[part 8 of 23: package /Cluster]
AUTOSAR XML (schema 4-3-0)
package /Cluster  (continued)
  can cluster E3V_EVCANFD: baudrate=500000, protocol-name=CAN, protocol-version=2.0, bus-off-recovery={bor-counter-l-1-to-l-2=1, bor-time-l-1=0.05, bor-time-l-2=0.2}, can-fd-baudrate=2000000  (continued)
    can physical channel CHNL: comm-connectors=CN_E3V_EVCANFD  (continued)
      frame SAD_01_XIX_E3V_EVCANFD: id 0x5E0, to Klima, frame-length=8, can-addressing-mode=STANDARD, can-frame-rx-behavior=CAN-FD, can-frame-tx-behavior=CAN-FD
        pdu SAD_01_XIX_E3V_EVCANFD: length=8, minimum-delay=0.05, transmission-mode-true-timing={cyclic-timing={time-offset=0.0, time-period=0.5}, event-controlled-timing={number-of-repetitions=5, repetition-period=0.1}}, unused-bit-pattern=0  # MLBevo 8Byte LIN-CAN (1:1) Botschaft wird geroutet: - wenn entsprechender Slave codiert ist - wenn fehlerfreie Kommunikation zum Slave besteht - bei fehlerhafter Kommunikation zum Slave wird die Botschaft für 4s mit den letzten gültigen Werten versendet
          signal MD1_Position_XIX_SAD_01_XIX_E3V_EVCANFD: start 8, 7 bit, little-endian, data-type-policy=OVERRIDE, i-signal-type=PRIMITIVE, init-value=126, base-type=BT_MD1_Position, compu {phys=raw for raw 0..100, 126=Cx7e_Init (CM_MD1_Position_Cx7e_Init), 127=Cx7f_nicht_normiert (CM_MD1_Position_Cx7f_nicht_normiert); unit Unit_PerCent}, range phys 0..100 Unit_PerCent, raw 0..127, unit=Unit_PerCent, transfer-property=PENDING, to Klima(timeout 5 s)  # Aktuelle Öffnungsweite Schiebedach.
          signal MD1_Lage_XIX_SAD_01_XIX_E3V_EVCANFD: start 15, 1 bit, little-endian, data-type-policy=OVERRIDE, i-signal-type=PRIMITIVE, init-value=0, base-type=BT_MD1_Lage, compu {0=Cx0_Ausstelllage (CM_MD1_Lage_Cx0_Ausstelllage), 1=Cx1_Schiebelage (CM_MD1_Lage_Cx1_Schiebelage)}, range raw 0..1, transfer-property=PENDING, to Klima(timeout 5 s)  # Lage Schiebedachstellung 1 (Signal wird 1:1 vom BCM2 geroutet; ursprünglicher Sender: SAD = LIN-Slave vom BCM2)
          signal MD3_Position_XIX_SAD_01_XIX_E3V_EVCANFD: start 16, 7 bit, little-endian, data-type-policy=OVERRIDE, i-signal-type=PRIMITIVE, init-value=0, base-type=BT_MD3_Position, compu {phys=raw for raw 0..100; unit Unit_PerCent}, range phys 0..100 Unit_PerCent, raw 0..100, unit=Unit_PerCent, transfer-property=PENDING  # Schiebedachstellung 3 (Signal wird 1:1 vom BCM2 geroutet; ursprünglicher Sender: SAD = LIN-Slave vom BCM2)
          signal MD3_Lage_XIX_SAD_01_XIX_E3V_EVCANFD: start 23, 1 bit, little-endian, data-type-policy=OVERRIDE, i-signal-type=PRIMITIVE, init-value=0, base-type=BT_MD3_Lage, compu {0=Cx0_Ausstelllage (CM_MD3_Lage_Cx0_Ausstelllage), 1=Cx1_Schiebelage (CM_MD3_Lage_Cx1_Schiebelage)}, range raw 0..1, transfer-property=PENDING, to Klima(timeout 5 s)  # Lage Schiebedachstellung 3 (Signal wird 1:1 vom BCM2 geroutet; ursprünglicher Sender: SAD = LIN-Slave vom BCM2)
          signal MRollo_Position_XIX_SAD_01_XIX_E3V_EVCANFD: start 24, 7 bit, little-endian, data-type-policy=OVERRIDE, i-signal-type=PRIMITIVE, init-value=126, base-type=BT_MRollo_Position, compu {phys=raw for raw 0..100, 126=Cx7e_Init (CM_MRollo_Position_Cx7e_Init), 127=Cx7f_nicht_normiert (CM_MRollo_Position_Cx7f_nicht_normiert); unit Unit_PerCent}, range phys 0..100 Unit_PerCent, raw 0..127, unit=Unit_PerCent, transfer-property=PENDING, to Klima(timeout 5 s)  # Aktuelle Öffnungsweite des Dachrollos.
          signal MRollo_Lage_XIX_SAD_01_XIX_E3V_EVCANFD: start 31, 1 bit, little-endian, data-type-policy=OVERRIDE, i-signal-type=PRIMITIVE, init-value=0, base-type=BT_MRollo_Lage, compu {0=Cx0_Ausstelllage (CM_MRollo_Lage_Cx0_Ausstelllage), 1=Cx1_Schiebelage (CM_MRollo_Lage_Cx1_Schiebelage)}, range raw 0..1, transfer-property=PENDING, to Klima(timeout 5 s)  # Lage Rollo (Signal wird 1:1 vom BCM2 geroutet; ursprünglicher Sender: Rollo = LIN-Slave vom BCM2)
          signal SAD_normiert_XIX_SAD_01_XIX_E3V_EVCANFD: start 32, 1 bit, little-endian, data-type-policy=OVERRIDE, i-signal-type=PRIMITIVE, init-value=0, base-type=BT_SAD_normiert, compu {0=Cx0_inaktiv (CM_SAD_normiert_Cx0_inaktiv), 1=Cx1_aktiv (CM_SAD_normiert_Cx1_aktiv)}, range raw 0..1, transfer-property=TRIGGERED-ON-CHANGE-WITHOUT-REPETITION  # Anzeige Normierung des Schiebeausstelldaches
          signal SAD_Thermoschutz_XIX_SAD_01_XIX_E3V_EVCANFD: start 33, 1 bit, little-endian, data-type-policy=OVERRIDE, i-signal-type=PRIMITIVE, init-value=0, base-type=BT_SAD_Thermoschutz, compu {0=Cx0_inaktiv (CM_SAD_Thermoschutz_Cx0_inaktiv), 1=Cx1_aktiv (CM_SAD_Thermoschutz_Cx1_aktiv)}, range raw 0..1, transfer-property=TRIGGERED-ON-CHANGE-WITHOUT-REPETITION  # Anzeige aktivierter Thermoschutz des Schiebeausstelldaches
          signal SAD_UEKB_aktiv_XIX_SAD_01_XIX_E3V_EVCANFD: start 34, 1 bit, little-endian, data-type-policy=OVERRIDE, i-signal-type=PRIMITIVE, init-value=0, base-type=BT_SAD_UEKB_aktiv, compu {0=Cx0_inaktiv (CM_SAD_UEKB_aktiv_Cx0_inaktiv), 1=Cx1_aktiv (CM_SAD_UEKB_aktiv_Cx1_aktiv)}, range raw 0..1, transfer-property=TRIGGERED-ON-CHANGE-WITHOUT-REPETITION  # Anzeige aktivierter Überschusskraftbegrenzung des Schiebeausstelldaches
          signal Rollo_normiert_XIX_SAD_01_XIX_E3V_EVCANFD: start 35, 1 bit, little-endian, data-type-policy=OVERRIDE, i-signal-type=PRIMITIVE, init-value=0, base-type=BT_Rollo_normiert, compu {0=Cx0_inaktiv (CM_Rollo_normiert_Cx0_inaktiv), 1=Cx1_aktiv (CM_Rollo_normiert_Cx1_aktiv)}, range raw 0..1, transfer-property=TRIGGERED-ON-CHANGE-WITHOUT-REPETITION  # Anzeigen Normierung des Dachrollos
          signal Rollo_Thermoschutz_XIX_SAD_01_XIX_E3V_EVCANFD: start 36, 1 bit, little-endian, data-type-policy=OVERRIDE, i-signal-type=PRIMITIVE, init-value=0, base-type=BT_Rollo_Thermoschutz, compu {0=Cx0_inaktiv (CM_Rollo_Thermoschutz_Cx0_inaktiv), 1=Cx1_aktiv (CM_Rollo_Thermoschutz_Cx1_aktiv)}, range raw 0..1, transfer-property=TRIGGERED-ON-CHANGE-WITHOUT-REPETITION  # Anzeigen aktivierter Thermoschutz des Dachrollo
          signal Rollo_UEKB_aktiv_XIX_SAD_01_XIX_E3V_EVCANFD: start 37, 1 bit, little-endian, data-type-policy=OVERRIDE, i-signal-type=PRIMITIVE, init-value=0, base-type=BT_Rollo_UEKB_aktiv, compu {0=Cx0_inaktiv (CM_Rollo_UEKB_aktiv_Cx0_inaktiv), 1=Cx1_aktiv (CM_Rollo_UEKB_aktiv_Cx1_aktiv)}, range raw 0..1, transfer-property=TRIGGERED-ON-CHANGE-WITHOUT-REPETITION  # Anzeigen aktivierter Überschusskraftbegrenzung des Dachrollos
          signal SAD_Taster_Deckel_hi_XIX_SAD_01_XIX_E3V_EVCANFD: start 38, 4 bit, little-endian, data-type-policy=OVERRIDE, i-signal-type=PRIMITIVE, init-value=0, base-type=BT_SAD_Taster_Deckel_hi, compu {0=Cx0_nicht_betaetigt (CM_SAD_Taster_Deckel_hi_Cx0_nicht_betaetigt), 1=Cx1_man_sl_zu (CM_SAD_Taster_Deckel_hi_Cx1_man_sl_zu), 2=Cx2_auto_sl_zu (CM_SAD_Taster_Deckel_hi_Cx2_auto_sl_zu), 3=Cx3_man_sl_auf (CM_SAD_Taster_Deckel_hi_Cx3_man_sl_auf), 4=Cx4_auto_sl_auf (CM_SAD_Taster_Deckel_hi_Cx4_auto_sl_auf), 5=Cx5_man_al_auf (CM_SAD_Taster_Deckel_hi_Cx5_man_al_auf), 6=Cx6_auto_al_auf (CM_SAD_Taster_Deckel_hi_Cx6_auto_al_auf), 7=Cx7_man_al_zu (CM_SAD_Taster_Deckel_hi_Cx7_man_al_zu), 8=Cx8_auto_al_zu (CM_SAD_Taster_Deckel_hi_Cx8_auto_al_zu), 14=Cxe_fehler_schalter_haengt (CM_SAD_Taster_Deckel_hi_Cxe_fehler_schalter_haengt), 15=Cxf_fehler_schalter_unplausibel (CM_SAD_Taster_Deckel_hi_Cxf_fehler_schalter_unplausibel)}, range raw 0..15, transfer-property=TRIGGERED-ON-CHANGE  # Taster für SAD Deckel hinten
          signal SAD_Taster_Deckel_vo_XIX_SAD_01_XIX_E3V_EVCANFD: start 42, 4 bit, little-endian, data-type-policy=OVERRIDE, i-signal-type=PRIMITIVE, init-value=0, base-type=BT_SAD_Taster_Deckel_vo, compu {0=Cx0_nicht_betaetigt (CM_SAD_Taster_Deckel_vo_Cx0_nicht_betaetigt), 1=Cx1_man_sl_zu (CM_SAD_Taster_Deckel_vo_Cx1_man_sl_zu), 2=Cx2_auto_sl_zu (CM_SAD_Taster_Deckel_vo_Cx2_auto_sl_zu), 3=Cx3_man_sl_auf (CM_SAD_Taster_Deckel_vo_Cx3_man_sl_auf), 4=Cx4_auto_sl_auf (CM_SAD_Taster_Deckel_vo_Cx4_auto_sl_auf), 5=Cx5_man_al_auf (CM_SAD_Taster_Deckel_vo_Cx5_man_al_auf), 6=Cx6_auto_al_auf (CM_SAD_Taster_Deckel_vo_Cx6_auto_al_auf), 7=Cx7_man_al_zu (CM_SAD_Taster_Deckel_vo_Cx7_man_al_zu), 8=Cx8_auto_al_zu (CM_SAD_Taster_Deckel_vo_Cx8_auto_al_zu), 14=Cxe_fehler_schalter_haengt (CM_SAD_Taster_Deckel_vo_Cxe_fehler_schalter_haengt), 15=Cxf_fehler_schalter_unplausibel (CM_SAD_Taster_Deckel_vo_Cxf_fehler_schalter_unplausibel)}, range raw 0..15, transfer-property=TRIGGERED-ON-CHANGE  # Taster für SAD Deckel vorne
          signal SAD_Taster_Rollo_hi_XIX_SAD_01_XIX_E3V_EVCANFD: start 46, 3 bit, little-endian, data-type-policy=OVERRIDE, i-signal-type=PRIMITIVE, init-value=0, base-type=BT_SAD_Taster_Rollo_hi, compu {0=Cx0_nicht_betaetigt (CM_SAD_Taster_Rollo_hi_Cx0_nicht_betaetigt), 1=Cx1_man_zu (CM_SAD_Taster_Rollo_hi_Cx1_man_zu), 2=Cx2_auto_zu (CM_SAD_Taster_Rollo_hi_Cx2_auto_zu), 3=Cx3_man_auf (CM_SAD_Taster_Rollo_hi_Cx3_man_auf), 4=Cx4_auto_auf (CM_SAD_Taster_Rollo_hi_Cx4_auto_auf), 6=Cx6_fehler_schalter_haengt (CM_SAD_Taster_Rollo_hi_Cx6_fehler_schalter_haengt), 7=Cx7_fehler_schalter_unplausibel (CM_SAD_Taster_Rollo_hi_Cx7_fehler_schalter_unplausibel)}, range raw 0..7, transfer-property=TRIGGERED-ON-CHANGE  # Taster für SAD Rollo hinten
          signal SAD_Taster_Rollo_vo_XIX_SAD_01_XIX_E3V_EVCANFD: start 49, 3 bit, little-endian, data-type-policy=OVERRIDE, i-signal-type=PRIMITIVE, init-value=0, base-type=BT_SAD_Taster_Rollo_vo, compu {0=Cx0_nicht_betaetigt (CM_SAD_Taster_Rollo_vo_Cx0_nicht_betaetigt), 1=Cx1_man_zu (CM_SAD_Taster_Rollo_vo_Cx1_man_zu), 2=Cx2_auto_zu (CM_SAD_Taster_Rollo_vo_Cx2_auto_zu), 3=Cx3_man_auf (CM_SAD_Taster_Rollo_vo_Cx3_man_auf), 4=Cx4_auto_auf (CM_SAD_Taster_Rollo_vo_Cx4_auto_auf), 6=Cx6_fehler_schalter_haengt (CM_SAD_Taster_Rollo_vo_Cx6_fehler_schalter_haengt), 7=Cx7_fehler_schalter_unplausibel (CM_SAD_Taster_Rollo_vo_Cx7_fehler_schalter_unplausibel)}, range raw 0..7, transfer-property=TRIGGERED-ON-CHANGE  # Taster für SAD Rollo vorne
          signal SAD_Anf_ESC_Zuschaltung_XIX_SAD_01_XIX_E3V_EVCANFD: start 52, 1 bit, little-endian, data-type-policy=OVERRIDE, i-signal-type=PRIMITIVE, init-value=0, base-type=BT_SAD_Anf_ESC_Zuschaltung, compu {0=Cx0_inaktiv (CM_SAD_Anf_ESC_Zuschaltung_Cx0_inaktiv), 1=Cx1_aktiv (CM_SAD_Anf_ESC_Zuschaltung_Cx1_aktiv)}, range raw 0..1, transfer-property=TRIGGERED-ON-CHANGE-WITHOUT-REPETITION  # Zwangsaktivierung ESP durch SAD-SG (bei geöffnetem Schiebedach und V> xx km/h).
          signal SAD_Text_XIX_SAD_01_XIX_E3V_EVCANFD: start 53, 1 bit, little-endian, data-type-policy=OVERRIDE, i-signal-type=PRIMITIVE, init-value=0, base-type=BT_SAD_Text, compu {0=Cx0_inaktiv (CM_SAD_Text_Cx0_inaktiv), 1=Cx1_aktiv (CM_SAD_Text_Cx1_aktiv)}, range raw 0..1, transfer-property=TRIGGERED-ON-CHANGE  # Fehler Windabweiser in Abhängigkeit von der Geschwindigkeit
          signal SAD_ToggleBit_XIX_SAD_01_XIX_E3V_EVCANFD: start 54, 1 bit, little-endian, data-type-policy=OVERRIDE, i-signal-type=PRIMITIVE, init-value=0, base-type=BT_SAD_ToggleBit, compu {phys=raw for raw 0..1}, range phys 0..1, raw 0..1, transfer-property=PENDING  # SIL A Absicherung für die Signale: SAD_normiert, MD1_Lage, MD1_Position, SAD_Anf_ESC_Zuschaltung
          signal SAD_ParityBit_XIX_SAD_01_XIX_E3V_EVCANFD: start 55, 1 bit, little-endian, data-type-policy=OVERRIDE, i-signal-type=PRIMITIVE, init-value=0, base-type=BT_SAD_ParityBit, compu {phys=raw for raw 0..1}, range phys 0..1, raw 0..1, transfer-property=PENDING  # SIL A Absicherung für die Signale: SAD_normiert, MD1_Lage, MD1_Position, SAD_Anf_ESC_Zuschaltung
      frame SMLS_01_XIX_E3V_EVCANFD: id 0x3D4, to Klima, frame-length=8, can-addressing-mode=STANDARD, can-frame-rx-behavior=CAN-FD, can-frame-tx-behavior=CAN-FD
        pdu SMLS_01_XIX_E3V_EVCANFD: length=8, minimum-delay=0.05, transmission-mode-true-timing={cyclic-timing={time-offset=0.0, time-period=1.0}, event-controlled-timing={number-of-repetitions=5, repetition-period=0.1}}, unused-bit-pattern=0  # Ab MQB 7.2
          signal SMLS_01_CRC_XIX_SMLS_01_XIX_E3V_EVCANFD: start 0, 8 bit, little-endian, data-type-policy=OVERRIDE, i-signal-type=PRIMITIVE, base-type=BT_SMLS_01_CRC, compu {phys=raw for raw 0..255}, range phys 0..255, raw 0..255, transfer-property=PENDING  # Für MLB: "Berechnung siehe Lastenheft "Kommunikationsabsicherung für FlexRay und CAN"" Ab MQB und MLBevo: "Berechnung siehe Lastenheft "End-to-End Kommunikationsabsicherung"" Endwerte siehe Begleitdokument "S-PDU Kennungsfolgen"
          signal SMLS_01_BZ_XIX_SMLS_01_XIX_E3V_EVCANFD: start 8, 4 bit, little-endian, data-type-policy=OVERRIDE, i-signal-type=PRIMITIVE, base-type=BT_SMLS_01_BZ, compu {phys=raw for raw 0..15}, range phys 0..15, raw 0..15, transfer-property=PENDING  # 4bit Botschaftszaehler, wird mit jeder Sendebotschaft inkrementiert
          signal BH_Blinker_li_XIX_SMLS_01_XIX_E3V_EVCANFD: start 12, 1 bit, little-endian, data-type-policy=OVERRIDE, i-signal-type=PRIMITIVE, init-value=0, base-type=BT_BH_Blinker_li, compu {0=Cx0_nicht_betaetigt (CM_BH_Blinker_li_Cx0_nicht_betaetigt), 1=Cx1_Blinkerhebel_Pos_li_betaetigt (CM_BH_Blinker_li_Cx1_Blinkerhebel_Pos_li_betaetigt)}, range raw 0..1, transfer-property=TRIGGERED-ON-CHANGE  # Blinkerhebel Richtung links
          signal BH_Blinker_re_XIX_SMLS_01_XIX_E3V_EVCANFD: start 13, 1 bit, little-endian, data-type-policy=OVERRIDE, i-signal-type=PRIMITIVE, init-value=0, base-type=BT_BH_Blinker_re, compu {0=Cx0_nicht_betaetigt (CM_BH_Blinker_re_Cx0_nicht_betaetigt), 1=Cx1_Blinkerhebel_Pos_re_betaetigt (CM_BH_Blinker_re_Cx1_Blinkerhebel_Pos_re_betaetigt)}, range raw 0..1, transfer-property=TRIGGERED-ON-CHANGE  # Blinkerhebel Richtung rechts
          signal BH_Lichthupe_XIX_SMLS_01_XIX_E3V_EVCANFD: start 14, 1 bit, little-endian, data-type-policy=OVERRIDE, i-signal-type=PRIMITIVE, init-value=0, base-type=BT_BH_Lichthupe, compu {0=Cx0_nicht_betaetigt (CM_BH_Lichthupe_Cx0_nicht_betaetigt), 1=Cx1_Blinkerhebel_in_Richtung_Lichthupe_betaetigt (CM_BH_Lichthupe_Cx1_Blinkerhebel_in_Richtung_Lichthupe_betaetigt) (Blinkerhebel in Richtung Lichthupe betaetigt)}, range raw 0..1, transfer-property=TRIGGERED-ON-CHANGE  # Betaetigung Lichthupe
          signal BH_Fernlicht_XIX_SMLS_01_XIX_E3V_EVCANFD: start 15, 1 bit, little-endian, data-type-policy=OVERRIDE, i-signal-type=PRIMITIVE, init-value=0, base-type=BT_BH_Fernlicht, compu {0=Cx0_nicht_betaetigt (CM_BH_Fernlicht_Cx0_nicht_betaetigt), 1=Cx1_Blinkerhebel_in_Richtung_Fernlicht_betaetigt (CM_BH_Fernlicht_Cx1_Blinkerhebel_in_Richtung_Fernlicht_betaetigt)}, range raw 0..1, transfer-property=TRIGGERED-ON-CHANGE-WITHOUT-REPETITION  # Betaetigung Fernlicht
          signal WH_Tipwischen_XIX_SMLS_01_XIX_E3V_EVCANFD: start 16, 1 bit, little-endian, data-type-policy=OVERRIDE, i-signal-type=PRIMITIVE, init-value=0, base-type=BT_WH_Tipwischen, compu {0=Cx0_nicht_betaetigt (CM_WH_Tipwischen_Cx0_nicht_betaetigt), 1=Cx1_betaetigt (CM_WH_Tipwischen_Cx1_betaetigt)}, range raw 0..1, transfer-property=TRIGGERED-ON-CHANGE  # Wischerhebel: Tippwischen MQB A0/ PQ26: Bei Verbau LSS (kein SMLS): gespiegelter Wert zu Signal WH_WischerStufe1
          signal WH_Intervall_XIX_SMLS_01_XIX_E3V_EVCANFD: start 17, 1 bit, little-endian, data-type-policy=OVERRIDE, i-signal-type=PRIMITIVE, init-value=0, base-type=BT_WH_Intervall, compu {0=Cx0_aus (CM_WH_Intervall_Cx0_aus), 1=Cx1_Wischerhebel_in_Stellung_Intervall (CM_WH_Intervall_Cx1_Wischerhebel_in_Stellung_Intervall) (Wischerhebel in Stellung Intervall)}, range raw 0..1, transfer-property=TRIGGERED-ON-CHANGE-WITHOUT-REPETITION  # Wischerhebel: Stellung Intervall
          signal WH_WischerStufe1_XIX_SMLS_01_XIX_E3V_EVCANFD: start 18, 1 bit, little-endian, data-type-policy=OVERRIDE, i-signal-type=PRIMITIVE, init-value=0, base-type=BT_WH_WischerStufe1, compu {0=Cx0_aus (CM_WH_WischerStufe1_Cx0_aus), 1=Cx1_Wischerhebel_in_Stufe_Wischen_1 (CM_WH_WischerStufe1_Cx1_Wischerhebel_in_Stufe_Wischen_1) (Wischerhebel in Stufe Wischen 1)}, range raw 0..1, transfer-property=TRIGGERED-ON-CHANGE-WITHOUT-REPETITION  # Wischerhebel: Stufe Wischen 1
          signal WH_WischerStufe2_XIX_SMLS_01_XIX_E3V_EVCANFD: start 19, 1 bit, little-endian, data-type-policy=OVERRIDE, i-signal-type=PRIMITIVE, init-value=0, base-type=BT_WH_WischerStufe2, compu {0=Cx0_aus (CM_WH_WischerStufe2_Cx0_aus), 1=Cx1_Wischerhebel_in_Stufe_Wischen_2 (CM_WH_WischerStufe2_Cx1_Wischerhebel_in_Stufe_Wischen_2) (Wischerhebel in Stufe Wischen 2)}, range raw 0..1, transfer-property=TRIGGERED-ON-CHANGE-WITHOUT-REPETITION  # Wischerhebel: Stufe Wischen 2
          signal WH_Frontwaschen_XIX_SMLS_01_XIX_E3V_EVCANFD: start 20, 1 bit, little-endian, data-type-policy=OVERRIDE, i-signal-type=PRIMITIVE, init-value=0, base-type=BT_WH_Frontwaschen, compu {0=Cx0_aus (CM_WH_Frontwaschen_Cx0_aus), 1=Cx1_Wischerhebel_in_Stellung_Wisch_Wasch_vorne (CM_WH_Frontwaschen_Cx1_Wischerhebel_in_Stellung_Wisch_Wasch_vorne) (Wischerhebel in Stellung Wisch Wasch vorne)}, range raw 0..1, transfer-property=TRIGGERED-ON-CHANGE-WITHOUT-REPETITION  # Wischerhebel: Stellung Wisch Wasch vorne
          signal WH_Heckintervall_XIX_SMLS_01_XIX_E3V_EVCANFD: start 21, 1 bit, little-endian, data-type-policy=OVERRIDE, i-signal-type=PRIMITIVE, init-value=0, base-type=BT_WH_Heckintervall, compu {0=Cx0_nicht_betaetigt (CM_WH_Heckintervall_Cx0_nicht_betaetigt), 1=Cx1_Wischerhebel_in_Stellung_Heckintervall (CM_WH_Heckintervall_Cx1_Wischerhebel_in_Stellung_Heckintervall) (Wischerhebel in Stellung Heckintervall)}, range raw 0..1, transfer-property=TRIGGERED-ON-CHANGE-WITHOUT-REPETITION  # Wischerhebel: Stellung Heckintervall
          signal WH_Heckwaschen_XIX_SMLS_01_XIX_E3V_EVCANFD: start 22, 1 bit, little-endian, data-type-policy=OVERRIDE, i-signal-type=PRIMITIVE, init-value=0, base-type=BT_WH_Heckwaschen, compu {0=Cx0_nicht_betaetigt (CM_WH_Heckwaschen_Cx0_nicht_betaetigt), 1=Cx1_Wischerhebel_in_Stellung_Wisch_Wasch_hinten (CM_WH_Heckwaschen_Cx1_Wischerhebel_in_Stellung_Wisch_Wasch_hinten) (Wischerhebel in Stellung Wisch Wasch hinten)}, range raw 0..1, transfer-property=TRIGGERED-ON-CHANGE-WITHOUT-REPETITION  # Wischerhebel: Stellung Wisch Wasch hinten
          signal WH_Intervallstufen_XIX_SMLS_01_XIX_E3V_EVCANFD: start 23, 4 bit, little-endian, data-type-policy=OVERRIDE, i-signal-type=PRIMITIVE, init-value=0, base-type=BT_WH_Intervallstufen, invalid-value=Invalid_WH_Intervallstufen_XIX_SMLS_01_XIX_E3V_EVCANFD:15, compu {0=Cx0_Init_Default (CM_WH_Intervallstufen_Cx0_Init_Default) (Init / Default), 1=Cx1_Intervallstufe_1 (CM_WH_Intervallstufen_Cx1_Intervallstufe_1) (Intervallstufe 1), 5=Cx5_Intervallstufe_2 (CM_WH_Intervallstufen_Cx5_Intervallstufe_2) (Intervallstufe 2), 9=Cx9_Intervallstufe_3 (CM_WH_Intervallstufen_Cx9_Intervallstufe_3) (Intervallstufe 3), 13=Cxd_Intervallstufe_4 (CM_WH_Intervallstufen_Cxd_Intervallstufe_4) (Intervallstufe 4), 15=Cxf_Fehler (CM_WH_Intervallstufen_Cxf_Fehler)}, range raw 0..15, transfer-property=TRIGGERED-ON-CHANGE-WITHOUT-REPETITION  # Wischerhebel: Stellung Intervallstufen
          signal FAS_Taster_XIX_SMLS_01_XIX_E3V_EVCANFD: start 27, 1 bit, little-endian, data-type-policy=OVERRIDE, i-signal-type=PRIMITIVE, init-value=0, base-type=BT_FAS_Taster, compu {0=Cx0_nicht_betaetigt (CM_FAS_Taster_Cx0_nicht_betaetigt), 1=Cx1_betaetigt (CM_FAS_Taster_Cx1_betaetigt)}, range raw 0..1, transfer-property=TRIGGERED-ON-CHANGE-WITHOUT-REPETITION  # Betaetigung FAS Taster
          signal FAS_Taster_Fehler_XIX_SMLS_01_XIX_E3V_EVCANFD: start 28, 1 bit, little-endian, data-type-policy=OVERRIDE, i-signal-type=PRIMITIVE, init-value=0, base-type=BT_FAS_Taster_Fehler, invalid-value=Invalid_FAS_Taster_Fehler_XIX_SMLS_01_XIX_E3V_EVCANFD:1, compu {0=Cx0_kein_Fehler (CM_FAS_Taster_Fehler_Cx0_kein_Fehler), 1=Cx1_Fehler (CM_FAS_Taster_Fehler_Cx1_Fehler)}, range raw 0..1, transfer-property=TRIGGERED-ON-CHANGE-WITHOUT-REPETITION  # Fehlerstatus FAS Taster
          signal SMLS_Hupe_XIX_SMLS_01_XIX_E3V_EVCANFD: start 29, 1 bit, little-endian, data-type-policy=OVERRIDE, i-signal-type=PRIMITIVE, init-value=0, base-type=BT_SMLS_Hupe, compu {0=Cx0_nicht_betaetigt (CM_SMLS_Hupe_Cx0_nicht_betaetigt), 1=Cx1_Hupe_gedrueckt (CM_SMLS_Hupe_Cx1_Hupe_gedrueckt)}, range raw 0..1, transfer-property=TRIGGERED-ON-CHANGE  # Betaetigung Hupe
          signal LRH_On_Off_XIX_SMLS_01_XIX_E3V_EVCANFD: start 30, 2 bit, little-endian, data-type-policy=OVERRIDE, i-signal-type=PRIMITIVE, init-value=0, base-type=BT_LRH_On_Off, invalid-value=Invalid_LRH_On_Off_XIX_SMLS_01_XIX_E3V_EVCANFD:3, compu {0=Cx0_LRH_aus_keine_Anzeige (CM_LRH_On_Off_Cx0_LRH_aus_keine_Anzeige) (LRH_aus__keine Anzeige), 1=Cx1_LRH_aus (CM_LRH_On_Off_Cx1_LRH_aus), 2=Cx2_LRH_ein (CM_LRH_On_Off_Cx2_LRH_ein), 3=Cx3_Fehler (CM_LRH_On_Off_Cx3_Fehler)}, range raw 0..3, transfer-property=TRIGGERED-ON-CHANGE-WITHOUT-REPETITION, to Klima(timeout 5 s)  # Status Lenkradheizung
          signal LSS_Tastencode_XIX_SMLS_01_XIX_E3V_EVCANFD: start 32, 8 bit, little-endian, data-type-policy=OVERRIDE, i-signal-type=PRIMITIVE, init-value=0, base-type=BT_LSS_Tastencode, compu {0=Cx0_Key_Released_No_Key (CM_LSS_Tastencode_Cx0_Key_Released_No_Key) (Key_Released__No_Key), 4=Cx4_Up (CM_LSS_Tastencode_Cx4_Up), 5=Cx5_Down (CM_LSS_Tastencode_Cx5_Down), 7=Cx7_OK_ThumbWheel_Button (CM_LSS_Tastencode_Cx7_OK_ThumbWheel_Button) (OK__ThumbWheel_Button)}, range raw 0..7, transfer-property=TRIGGERED-ON-CHANGE-WITHOUT-REPETITION  # 0x00 = No key pressed / key released 0x01 = Menu 0x02 = Menu Up / Next Screen 0x03 = Menu Down / Previous Screen 0x04 = Up 0x05 = Down 0x06 = Up / Down ThumbWheel 0x07 = OK (ThumbWheel-Button) 0x08 = Cancel / Escape 0x09..0x0F = reserved for further menu controls 0x10 = Volume Up 0x11 = Volume Down 0x12 = Volume Up / Down ThumbWheel 0x13 = Volume-ThumbWheel-Button 0x14 = Audio Source 0x15 = Arrow A Up / Right 0x16 = Arrow A Down / Left 0x17 = Arrow B Up / Right 0x18 = Arrow B Down / Left 0x19 = PTT (Push To Talk) 0x1A = PTT Cancel 0x1B = Route Info 0x1C = Hook 0x1D = Hang Up 0x1E = Off Hook 0x1F = Light On / Off 0x20 = Mute 0x21 = Joker1 0x22 = Joker2 0x23..0xEF = reserved for further function controls 0xF0 = Startup_Reset
          signal LRH_aktiv_XIX_SMLS_01_XIX_E3V_EVCANFD: start 40, 1 bit, little-endian, data-type-policy=OVERRIDE, i-signal-type=PRIMITIVE, init-value=0, base-type=BT_LRH_aktiv, compu {0=Cx0_inaktiv (CM_LRH_aktiv_Cx0_inaktiv), 1=Cx1_aktiv (CM_LRH_aktiv_Cx1_aktiv)}, range raw 0..1, transfer-property=TRIGGERED-ON-CHANGE-WITHOUT-REPETITION  # Signal gibt an, ob ein Heizstrom durch die Lenkradheizung fließt. Es dient der Auswertung durch das Energiemanagement.
          signal SMLS_P_verriegelt_XIX_SMLS_01_XIX_E3V_EVCANFD: start 41, 2 bit, little-endian, data-type-policy=OVERRIDE, i-signal-type=PRIMITIVE, init-value=0, base-type=BT_SMLS_P_verriegelt, invalid-value=Invalid_SMLS_P_verriegelt_XIX_SMLS_01_XIX_E3V_EVCANFD:3, compu {0=Cx0_Init (CM_SMLS_P_verriegelt_Cx0_Init), 1=Cx1_nicht_verriegelt (CM_SMLS_P_verriegelt_Cx1_nicht_verriegelt), 2=Cx2_verriegelt (CM_SMLS_P_verriegelt_Cx2_verriegelt), 3=Cx3_Fehler (CM_SMLS_P_verriegelt_Cx3_Fehler)}, range raw 0..3, transfer-property=TRIGGERED-ON-CHANGE  # Signal stellt den Status des Signals P-verriegelt auf den Fahrzeugbus zur Verfügung. Nutzer sind z.B. die ELV, die das Signal für die Verriegelung benötigt und die Funktion Verlassenswarnung, die den Fahrer beim Verrollen des Fahrzeugs warnt.
          signal SMLS_P_verriegelt_plausibel_XIX_SMLS_01_XIX_E3V_EVCANFD: start 43, 1 bit, little-endian, data-type-policy=OVERRIDE, i-signal-type=PRIMITIVE, init-value=0, base-type=BT_SMLS_P_verriegelt_plausibel, compu {0=Cx0_unplausibel (CM_SMLS_P_verriegelt_plausibel_Cx0_unplausibel), 1=Cx1_plausibel (CM_SMLS_P_verriegelt_plausibel_Cx1_plausibel)}, range raw 0..1, transfer-property=TRIGGERED-ON-CHANGE-WITHOUT-REPETITION  # Signal stellt den Plausibilisierungstatus des Signals p_verriegelt auf den Fahrzeugbus zur Verfügung. Eine Plausibilität muss explizit erkannt werden. Initial wird "unplausibel" gesendet. Ein plausibles Signal wird erkannt, wenn p_verriegelt plausibel gegenüber Geschwindigkeit oder der Wählhebelposition ist. Nutzer des Signals ist die Funktion Verlassenskonzept mit der Automatischen Klemmenabschaltung.
          signal WH_SRA_XIX_SMLS_01_XIX_E3V_EVCANFD: start 44, 1 bit, little-endian, data-type-policy=OVERRIDE, i-signal-type=PRIMITIVE, init-value=0, base-type=BT_WH_SRA, compu {0=Cx0_SRA_Aus (CM_WH_SRA_Cx0_SRA_Aus), 1=Cx1_SRA_Ein (CM_WH_SRA_Cx1_SRA_Ein)}, range raw 0..1, transfer-property=TRIGGERED-ON-CHANGE-WITHOUT-REPETITION  # Scheinwerferreinigungsanlage derzeit nur bei PAG umgesetzt
          signal WH_Wischer_Fehler_XIX_SMLS_01_XIX_E3V_EVCANFD: start 45, 1 bit, little-endian, data-type-policy=OVERRIDE, i-signal-type=PRIMITIVE, init-value=0, base-type=BT_WH_Wischer_Fehler, invalid-value=Invalid_WH_Wischer_Fehler_XIX_SMLS_01_XIX_E3V_EVCANFD:1, compu {0=Cx0_kein_Fehler (CM_WH_Wischer_Fehler_Cx0_kein_Fehler), 1=Cx1_Fehler (CM_WH_Wischer_Fehler_Cx1_Fehler)}, range raw 0..1, transfer-property=TRIGGERED-ON-CHANGE-WITHOUT-REPETITION  # Anzeige, ob am Lenkstockschalter ein Fehler anliegt. Notwendig aufgrund ASIL-Einstufung
          signal BH_Blinker_Fehler_XIX_SMLS_01_XIX_E3V_EVCANFD: start 46, 1 bit, little-endian, data-type-policy=OVERRIDE, i-signal-type=PRIMITIVE, init-value=0, base-type=BT_BH_Blinker_Fehler, invalid-value=Invalid_BH_Blinker_Fehler_XIX_SMLS_01_XIX_E3V_EVCANFD:1, compu {0=Cx0_kein_Fehler (CM_BH_Blinker_Fehler_Cx0_kein_Fehler), 1=Cx1_Fehler (CM_BH_Blinker_Fehler_Cx1_Fehler)}, range raw 0..1, transfer-property=TRIGGERED-ON-CHANGE  # Anzeige, ob am Lenkstockschalter ein Fehler anliegt. Notwendig aufgrund ASIL-Einstufung
          signal SMLS_PTT_XIX_SMLS_01_XIX_E3V_EVCANFD: start 47, 1 bit, little-endian, data-type-policy=OVERRIDE, i-signal-type=PRIMITIVE, init-value=0, base-type=BT_SMLS_PTT, compu {0=Cx0_nicht_betaetigt (CM_SMLS_PTT_Cx0_nicht_betaetigt), 1=Cx1_PTT_gedrueckt (CM_SMLS_PTT_Cx1_PTT_gedrueckt)}, range raw 0..1, transfer-property=TRIGGERED-ON-CHANGE  # Betaetigung PTT
          signal WH_Tipwischen_lang_XIX_SMLS_01_XIX_E3V_EVCANFD: start 48, 1 bit, little-endian, data-type-policy=OVERRIDE, i-signal-type=PRIMITIVE, init-value=0, base-type=BT_WH_Tipwischen_lang, compu {0=Cx0_nicht_betaetigt (CM_WH_Tipwischen_lang_Cx0_nicht_betaetigt), 1=Cx1_betaetigt (CM_WH_Tipwischen_lang_Cx1_betaetigt)}, range raw 0..1, transfer-property=TRIGGERED-ON-CHANGE  # Wischerhebel: Tippwischen lang (dient zur Auswertung für die Unterscheidung Tippwischen oder Serviceposition Wischer)
      frame SOK_FoD_Klima_Req_Chal_02_XIX_E3V_EVCANFD: id 0x12E01046, from Klima, frame-length=8, can-addressing-mode=EXTENDED, can-frame-rx-behavior=CAN-FD, can-frame-tx-behavior=CAN-FD
        pdu SOK_FoD_Klima_Req_Chal_02_XIX_E3V_EVCANFD: length=8, minimum-delay=0.05, transmission-mode-true-timing=event-controlled-timing={number-of-repetitions=0, repetition-period=0.0}, unused-bit-pattern=0
          signal SOK_FoD_Klima_Req_Challenge_XIX_SOK_FoD_Klima_Req_Chal_02_XIX_E3V_EVCANFD: start 0, 64 bit, opaque, data-type-policy=OVERRIDE, i-signal-type=ARRAY, base-type=BT_SOK_FoD_Klima_Req_Challenge, compu {phys=raw for raw 0..18446744073709551615; unit Unit_None}, range phys 0..18446744073709551615 Unit_None, raw 0..18446744073709551615, unit=Unit_None, transfer-property=TRIGGERED-ON-CHANGE-WITHOUT-REPETITION  # Challenge im Rahmen des SOK Challenge-Response Protokolls. Geschützte Funktion: Function on Demand
      frame SOK_FoD_Klima_Resp_Chal_02_XIX_E3V_EVCANFD: id 0x12E22046, to Klima, frame-length=8, can-addressing-mode=EXTENDED, can-frame-rx-behavior=CAN-FD, can-frame-tx-behavior=CAN-FD
        pdu SOK_FoD_Klima_Resp_Chal_02_XIX_E3V_EVCANFD: length=8, minimum-delay=0.05, transmission-mode-true-timing=event-controlled-timing={number-of-repetitions=0, repetition-period=0.0}, unused-bit-pattern=0
          signal SOK_FoD_Klima_Resp_Challenge_XIX_SOK_FoD_Klima_Resp_Chal_02_XIX_E3V_EVCANFD: start 0, 64 bit, opaque, data-type-policy=OVERRIDE, i-signal-type=ARRAY, base-type=BT_SOK_FoD_Klima_Resp_Challenge, compu {phys=raw for raw 0..18446744073709551615; unit Unit_None}, range phys 0..18446744073709551615 Unit_None, raw 0..18446744073709551615, unit=Unit_None, transfer-property=TRIGGERED-ON-CHANGE-WITHOUT-REPETITION, to Klima  # Challenge im Rahmen des SOK Challenge-Response Protokolls. Geschützte Funktion: Function on Demand
      frame SoSe_01_XIX_E3V_EVCANFD: id 0x5BB, to Klima, frame-length=8, can-addressing-mode=STANDARD, can-frame-rx-behavior=CAN-FD, can-frame-tx-behavior=CAN-FD
        pdu SoSe_01_XIX_E3V_EVCANFD: length=8, transmission-mode-true-timing=cyclic-timing={time-offset=0.0, time-period=0.5}, unused-bit-pattern=0
          signal SoSe_SunInt_2D_Li_XIX_SoSe_01_XIX_E3V_EVCANFD: start 0, 8 bit, little-endian, data-type-policy=OVERRIDE, i-signal-type=PRIMITIVE, init-value=254, base-type=BT_SoSe_SunInt_2D_Li, invalid-value=Invalid_SoSe_SunInt_2D_Li_XIX_SoSe_01_XIX_E3V_EVCANFD:255, compu {phys=raw*5 for raw 0..240, 254=Cxfe_Init (CM_SoSe_SunInt_2D_Li_Cxfe_Init), 255=Cxff_Fehler (CM_SoSe_SunInt_2D_Li_Cxff_Fehler); unit Unit_WattPerMeterSquar}, range phys 0..1200 Unit_WattPerMeterSquar, raw 0..255, unit=Unit_WattPerMeterSquar, transfer-property=PENDING, to Klima(timeout 5 s)  # Sonnenintensität links (2D Sensor)
          signal SoSe_SunInt_2D_Re_XIX_SoSe_01_XIX_E3V_EVCANFD: start 8, 8 bit, little-endian, data-type-policy=OVERRIDE, i-signal-type=PRIMITIVE, init-value=254, base-type=BT_SoSe_SunInt_2D_Re, invalid-value=Invalid_SoSe_SunInt_2D_Re_XIX_SoSe_01_XIX_E3V_EVCANFD:255, compu {phys=raw*5 for raw 0..240, 254=Cxfe_Init (CM_SoSe_SunInt_2D_Re_Cxfe_Init), 255=Cxff_Fehler (CM_SoSe_SunInt_2D_Re_Cxff_Fehler); unit Unit_WattPerMeterSquar}, range phys 0..1200 Unit_WattPerMeterSquar, raw 0..255, unit=Unit_WattPerMeterSquar, transfer-property=PENDING, to Klima(timeout 5 s)  # Sonnenintensität rechts (2D Sensor)
      frame Standklima_01_XIX_E3V_EVCANFD: id 0x16A954FB, to Klima, frame-length=8, can-addressing-mode=EXTENDED, can-frame-rx-behavior=CAN-FD, can-frame-tx-behavior=CAN-FD
        pdu Standklima_01_XIX_E3V_EVCANFD: length=8, minimum-delay=0.05, transmission-mode-true-timing={cyclic-timing={time-offset=0.0, time-period=0.5}, event-controlled-timing={number-of-repetitions=0, repetition-period=0.0}}, unused-bit-pattern=0
          signal STK_Sofortstart_Sperre_FFB_XIX_Standklima_01_XIX_E3V_EVCANFD: start 4, 1 bit, little-endian, data-type-policy=OVERRIDE, i-signal-type=PRIMITIVE, base-type=BT_STK_Sofortstart_Sperre_FFB, compu {0=Cx0_nicht_gesperrt (CM_STK_Sofortstart_Sperre_FFB_Cx0_nicht_gesperrt), 1=Cx1_gesperrt (CM_STK_Sofortstart_Sperre_FFB_Cx1_gesperrt)}, range raw 0..1, transfer-property=PENDING, to Klima(timeout 5 s)  # Signalisiert den Sperrzustand beim Verwenden einer FFB zum Sofortstart der Standklimatisierung.
          signal STK_Betriebsdauer_XIX_Standklima_01_XIX_E3V_EVCANFD: start 5, 7 bit, little-endian, data-type-policy=OVERRIDE, i-signal-type=PRIMITIVE, init-value=0, base-type=BT_STK_Betriebsdauer, compu {phys=raw for raw 0..120; unit Unit_Minut}, range phys 0..120 Unit_Minut, raw 0..120, unit=Unit_Minut, transfer-property=PENDING, to Klima(timeout 5 s)  # Betriebsdauer (TimeRemaining) Standklima Frontend
          signal STK_FSH_Anf_XIX_Standklima_01_XIX_E3V_EVCANFD: start 12, 1 bit, little-endian, data-type-policy=OVERRIDE, i-signal-type=PRIMITIVE, init-value=0, base-type=BT_STK_FSH_Anf, compu {0=Cx0_keine_Anforderung (CM_STK_FSH_Anf_Cx0_keine_Anforderung), 1=Cx1_Frontscheibenheizung_Anf (CM_STK_FSH_Anf_Cx1_Frontscheibenheizung_Anf)}, range raw 0..1, transfer-property=TRIGGERED-ON-CHANGE-WITHOUT-REPETITION, to Klima(timeout 5 s)  # Frontscheibenheizung anfordern
          signal STK_HSH_Anf_XIX_Standklima_01_XIX_E3V_EVCANFD: start 13, 1 bit, little-endian, data-type-policy=OVERRIDE, i-signal-type=PRIMITIVE, init-value=0, base-type=BT_STK_HSH_Anf, compu {0=Cx0_keine_Anforderung (CM_STK_HSH_Anf_Cx0_keine_Anforderung), 1=Cx1_Heckscheibenheizung_Anf (CM_STK_HSH_Anf_Cx1_Heckscheibenheizung_Anf)}, range raw 0..1, transfer-property=TRIGGERED-ON-CHANGE-WITHOUT-REPETITION, to Klima(timeout 5 s)  # Heckscheibenheizung anfordern
          signal STK_Klima_Temp_XIX_Standklima_01_XIX_E3V_EVCANFD: start 14, 5 bit, little-endian, data-type-policy=OVERRIDE, i-signal-type=PRIMITIVE, init-value=30, base-type=BT_STK_Klima_Temp, invalid-value=Invalid_STK_Klima_Temp_XIX_Standklima_01_XIX_E3V_EVCANFD:31, compu {phys=raw*0.5+15.5 for raw 0..28, 29=Cx1d_VW_high_30C (CM_STK_Klima_Temp_Cx1d_VW_high_30C), 30=Cx1e_Init (CM_STK_Klima_Temp_Cx1e_Init), 31=Cx1f_Fehler (CM_STK_Klima_Temp_Cx1f_Fehler); unit Unit_DegreCelsi}, range phys 15.5..29.5 Unit_DegreCelsi, raw 0..31, unit=Unit_DegreCelsi, transfer-property=PENDING, to Klima(timeout 5 s)  # MEB: Gewünschte Innenraumtemperatur, auf die bei der Standklimatisierung geregelt werden soll. MQB: Temperatur die vom Nutzer vorgewählt wurde (VW: low=15,5 °C/ high=30,0°C)
          signal STK_KurzVK_Anf_XIX_Standklima_01_XIX_E3V_EVCANFD: start 19, 1 bit, little-endian, data-type-policy=OVERRIDE, i-signal-type=PRIMITIVE, init-value=0, base-type=BT_STK_KurzVK_Anf, compu {0=Cx0_nicht_angefordert (CM_STK_KurzVK_Anf_Cx0_nicht_angefordert), 1=Cx1_angefordert (CM_STK_KurzVK_Anf_Cx1_angefordert)}, range raw 0..1, transfer-property=TRIGGERED-ON-CHANGE-WITHOUT-REPETITION, to Klima(timeout 5 s)  # Anforderung der kurz-Vorkonditionierung zur Aktivierung der Vorkonditionierung Innenraum
          signal STK_Standklima_Anf_XIX_Standklima_01_XIX_E3V_EVCANFD: start 20, 1 bit, little-endian, data-type-policy=OVERRIDE, i-signal-type=PRIMITIVE, init-value=0, base-type=BT_STK_Standklima_Anf, compu {0=Cx0_nicht_angefordert (CM_STK_Standklima_Anf_Cx0_nicht_angefordert), 1=Cx1_angefordert (CM_STK_Standklima_Anf_Cx1_angefordert)}, range raw 0..1, transfer-property=TRIGGERED-ON-CHANGE-WITHOUT-REPETITION, to Klima(timeout 5 s)  # Anforderung der Vorkonditionierung zur Aktivierung der Vorkonditionierung Innenraum
          signal STK_Standklima_Timer_Status_XIX_Standklima_01_XIX_E3V_EVCANFD: start 21, 1 bit, little-endian, data-type-policy=OVERRIDE, i-signal-type=PRIMITIVE, init-value=0, base-type=BT_STK_Standklima_Timer_Status, compu {0=Cx0_Standklimatimer_nicht_aktiv (CM_STK_Standklima_Timer_Status_Cx0_Standklimatimer_nicht_aktiv), 1=Cx1_Standklimatimer_aktiv (CM_STK_Standklima_Timer_Status_Cx1_Standklimatimer_aktiv)}, range raw 0..1, transfer-property=TRIGGERED-ON-CHANGE-WITHOUT-REPETITION, to Klima(timeout 5 s)  # Signalisierung an die Klima Black Box ob mind. ein Timer zur Standklimatisierung programmiert ist
          signal STK_AirCLeaner_Anf_XIX_Standklima_01_XIX_E3V_EVCANFD: start 22, 1 bit, little-endian, data-type-policy=OVERRIDE, i-signal-type=PRIMITIVE, init-value=0, base-type=BT_STK_AirCLeaner_Anf, compu {0=Cx0_nicht_angefordert (CM_STK_AirCLeaner_Anf_Cx0_nicht_angefordert), 1=Cx1_angefordert (CM_STK_AirCLeaner_Anf_Cx1_angefordert)}, range raw 0..1, transfer-property=PENDING, to Klima(timeout 5 s)  # Anforderung an das Klimasteuergerät dien Zustand der Umluftklappe zu ändern.
          signal STK_VK_Modus_XIX_Standklima_01_XIX_E3V_EVCANFD: start 23, 2 bit, little-endian, data-type-policy=OVERRIDE, i-signal-type=PRIMITIVE, init-value=0, base-type=BT_STK_VK_Modus, invalid-value=Invalid_STK_VK_Modus_XIX_Standklima_01_XIX_E3V_EVCANFD:3, compu {0=Cx0_keine_Vorkonditionierung (CM_STK_VK_Modus_Cx0_keine_Vorkonditionierung), 1=Cx1_Sofort_Konditionierung (CM_STK_VK_Modus_Cx1_Sofort_Konditionierung), 2=Cx2_zeitversetzte_Konditionierung (CM_STK_VK_Modus_Cx2_zeitversetzte_Konditionierung), 3=Cx3_Fehler (CM_STK_VK_Modus_Cx3_Fehler)}, range raw 0..3, transfer-property=TRIGGERED-ON-CHANGE-WITHOUT-REPETITION, to Klima(timeout 5 s)  # Übermittlung des aktuellen Konditionierungs-Status für HMI, Mobile Online Dienste
          signal STK_ErwVK_Anf_XIX_Standklima_01_XIX_E3V_EVCANFD: start 25, 1 bit, little-endian, data-type-policy=OVERRIDE, i-signal-type=PRIMITIVE, init-value=0, base-type=BT_STK_ErwVK_Anf, compu {0=Cx0_nicht_angefordert (CM_STK_ErwVK_Anf_Cx0_nicht_angefordert), 1=Cx1_angefordert (CM_STK_ErwVK_Anf_Cx1_angefordert)}, range raw 0..1, transfer-property=TRIGGERED-ON-CHANGE-WITHOUT-REPETITION, to Klima(timeout 5 s)  # Anforderung zur Aktivierung der Erweiterten-Vorkonditionierung im Innenraum
          signal STK_ErwVK_Modus_XIX_Standklima_01_XIX_E3V_EVCANFD: start 26, 4 bit, little-endian, data-type-policy=OVERRIDE, i-signal-type=PRIMITIVE, init-value=0, base-type=BT_STK_ErwVK_Modus, compu {0=Cx0_nicht_angefordert (CM_STK_ErwVK_Modus_Cx0_nicht_angefordert), 1=Cx1_Fahrerzone (CM_STK_ErwVK_Modus_Cx1_Fahrerzone), 2=Cx2_Beifahrerzone (CM_STK_ErwVK_Modus_Cx2_Beifahrerzone), 3=Cx3_Heckzone_links (CM_STK_ErwVK_Modus_Cx3_Heckzone_links), 4=Cx4_Heckzone_rechts (CM_STK_ErwVK_Modus_Cx4_Heckzone_rechts), 5=Cx5_Scheibenheizung (CM_STK_ErwVK_Modus_Cx5_Scheibenheizung)}, range raw 0..5, transfer-property=TRIGGERED-ON-CHANGE-WITHOUT-REPETITION, to Klima(timeout 5 s)  # Erweiterte Voko angefordert
          signal STK_Berechnungsphase_XIX_Standklima_01_XIX_E3V_EVCANFD: start 30, 2 bit, little-endian, data-type-policy=OVERRIDE, i-signal-type=PRIMITIVE, init-value=2, base-type=BT_STK_Berechnungsphase, invalid-value=Invalid_STK_Berechnungsphase_XIX_Standklima_01_XIX_E3V_EVCANFD:3, compu {0=Cx0_keine_Berechnungsphase (CM_STK_Berechnungsphase_Cx0_keine_Berechnungsphase), 1=Cx1_Berechnungsphase_erforderlich (CM_STK_Berechnungsphase_Cx1_Berechnungsphase_erforderlich), 2=Cx2_Init (CM_STK_Berechnungsphase_Cx2_Init), 3=Cx3_Fehler (CM_STK_Berechnungsphase_Cx3_Fehler)}, range raw 0..3, transfer-property=TRIGGERED-ON-CHANGE-WITHOUT-REPETITION, to Klima(timeout 5 s)  # Status der Berechnungsphase Vorkonditionierung. 0 = keine Berechnungsphase 1 = Berechnungsphase erforderlich 2 = Init 3 = Fehler
          signal STK_VK_Timer_Status_XIX_Standklima_01_XIX_E3V_EVCANFD: start 32, 2 bit, little-endian, data-type-policy=OVERRIDE, i-signal-type=PRIMITIVE, base-type=BT_STK_VK_Timer_Status, compu {0=Cx0_nicht_aktiv (CM_STK_VK_Timer_Status_Cx0_nicht_aktiv), 1=Cx1_aktiv (CM_STK_VK_Timer_Status_Cx1_aktiv), 2=Cx2_Sofortstart_aktiv (CM_STK_VK_Timer_Status_Cx2_Sofortstart_aktiv)}, range raw 0..2, transfer-property=TRIGGERED-ON-CHANGE-WITHOUT-REPETITION  # Statusmeldung an BMCe zum Vorkonditionierungsmodus, zur Aktivierung der Vorkonditionierung der HV-Batterie. "aktiv" = falls die Batterie einen Kühl-/Heizbedarf festgestellt hat, darf diese Batterie darf diese eine HV-Aktivierung anfordern und die Batterie-Vorkonditionierung starten. "Sofortstart_aktiv" = falls die Batterie einen Kühl-/Heizbedarf festgestellt hat, darf diese die Batterie-Konditionierung starten.
          signal STK_Anf_AussenspiegelHZ_XIX_Standklima_01_XIX_E3V_EVCANFD: start 34, 1 bit, little-endian, data-type-policy=OVERRIDE, i-signal-type=PRIMITIVE, init-value=0, base-type=BT_STK_Anf_AussenspiegelHZ, compu {0=Cx0_nicht_angefordert (CM_STK_Anf_AussenspiegelHZ_Cx0_nicht_angefordert), 1=Cx1_angefordert (CM_STK_Anf_AussenspiegelHZ_Cx1_angefordert)}, range raw 0..1, transfer-property=PENDING, to Klima(timeout 5 s)  # Anforderung Außenspiegelheizung seitens Klimafunktion (z.B. bei Erweiterter VoKo)
          signal STK_ErwVK_Beifahrerzone_XIX_Standklima_01_XIX_E3V_EVCANFD: start 35, 1 bit, little-endian, data-type-policy=OVERRIDE, i-signal-type=PRIMITIVE, init-value=0, base-type=BT_STK_ErwVK_Beifahrerzone, compu {0=Cx0_nicht_angefordert (CM_STK_ErwVK_Beifahrerzone_Cx0_nicht_angefordert), 1=Cx1_Beifahrerzone_angefordert (CM_STK_ErwVK_Beifahrerzone_Cx1_Beifahrerzone_angefordert)}, range raw 0..1, transfer-property=TRIGGERED-ON-CHANGE-WITHOUT-REPETITION, to Klima(timeout 5 s)  # Erweiterte Voko Beifahrerseite
          signal STK_ErwVK_Fahrerzone_XIX_Standklima_01_XIX_E3V_EVCANFD: start 36, 1 bit, little-endian, data-type-policy=OVERRIDE, i-signal-type=PRIMITIVE, init-value=0, base-type=BT_STK_ErwVK_Fahrerzone, compu {0=Cx0_nicht_angefordert (CM_STK_ErwVK_Fahrerzone_Cx0_nicht_angefordert), 1=Cx1_Fahrerzone_angefordert (CM_STK_ErwVK_Fahrerzone_Cx1_Fahrerzone_angefordert)}, range raw 0..1, transfer-property=TRIGGERED-ON-CHANGE-WITHOUT-REPETITION, to Klima(timeout 5 s)  # Erweiterte Voko Fahrerseite
          signal STK_ErwVK_Heckzone_links_XIX_Standklima_01_XIX_E3V_EVCANFD: start 37, 1 bit, little-endian, data-type-policy=OVERRIDE, i-signal-type=PRIMITIVE, init-value=0, base-type=BT_STK_ErwVK_Heckzone_links, compu {0=Cx0_nicht_angefordert (CM_STK_ErwVK_Heckzone_links_Cx0_nicht_angefordert), 1=Cx1_Heckzone_links_angefordert (CM_STK_ErwVK_Heckzone_links_Cx1_Heckzone_links_angefordert)}, range raw 0..1, transfer-property=TRIGGERED-ON-CHANGE-WITHOUT-REPETITION, to Klima(timeout 5 s)  # Erweiterte Voko Sitzheizung hinten links
          signal STK_ErwVK_Heckzone_rechts_XIX_Standklima_01_XIX_E3V_EVCANFD: start 38, 1 bit, little-endian, data-type-policy=OVERRIDE, i-signal-type=PRIMITIVE, init-value=0, base-type=BT_STK_ErwVK_Heckzone_rechts, compu {0=Cx0_nicht_angefordert (CM_STK_ErwVK_Heckzone_rechts_Cx0_nicht_angefordert), 1=Cx1_Heckzone_rechts_angefordert (CM_STK_ErwVK_Heckzone_rechts_Cx1_Heckzone_rechts_angefordert)}, range raw 0..1, transfer-property=TRIGGERED-ON-CHANGE-WITHOUT-REPETITION, to Klima(timeout 5 s)  # Erweiterte Voko Sitzheizung hinten rechts
          signal STK_ErwVK_Scheibenheizung_XIX_Standklima_01_XIX_E3V_EVCANFD: start 39, 1 bit, little-endian, data-type-policy=OVERRIDE, i-signal-type=PRIMITIVE, init-value=0, base-type=BT_STK_ErwVK_Scheibenheizung, compu {0=Cx0_nicht_angefordert (CM_STK_ErwVK_Scheibenheizung_Cx0_nicht_angefordert), 1=Cx1_Scheibenheizung_angefordert (CM_STK_ErwVK_Scheibenheizung_Cx1_Scheibenheizung_angefordert)}, range raw 0..1, transfer-property=TRIGGERED-ON-CHANGE-WITHOUT-REPETITION, to Klima(timeout 5 s)  # Erweiterte Voko Scheibenheizung Freigabe
          signal STK_VK_STH_Einsatz_XIX_Standklima_01_XIX_E3V_EVCANFD: start 40, 3 bit, little-endian, data-type-policy=OVERRIDE, i-signal-type=PRIMITIVE, init-value=6, base-type=BT_STK_VK_STH_Einsatz, invalid-value=Invalid_STK_VK_STH_Einsatz_XIX_Standklima_01_XIX_E3V_EVCANFD:7, compu {0=Cx0_Verbrennerstandheizung_verbieten (CM_STK_VK_STH_Einsatz_Cx0_Verbrennerstandheizung_verbieten) (Verbrennerstandheizung verbieten), 1=Cx1_Automatik_Verbrennerstandheizung_erlauben (CM_STK_VK_STH_Einsatz_Cx1_Automatik_Verbrennerstandheizung_erlauben) (Automatik (Verbrennerstandheizung erlauben)), 2=Cx2_Verbrennerstandheizung_erzwingen (CM_STK_VK_STH_Einsatz_Cx2_Verbrennerstandheizung_erzwingen) (Verbrennerstandheizung erzwingen), 3=Cx3_reserviert (CM_STK_VK_STH_Einsatz_Cx3_reserviert), 4=Cx4_reserviert (CM_STK_VK_STH_Einsatz_Cx4_reserviert), 5=Cx5_reserviert (CM_STK_VK_STH_Einsatz_Cx5_reserviert), 6=Cx6_Init (CM_STK_VK_STH_Einsatz_Cx6_Init), 7=Cx7_Fehler (CM_STK_VK_STH_Einsatz_Cx7_Fehler)}, range raw 0..7, transfer-property=TRIGGERED-ON-CHANGE-WITHOUT-REPETITION  # Anforderung(STK) an CCM zur Freigabe der Standheizung
          signal STK_Voko_LED_XIX_Standklima_01_XIX_E3V_EVCANFD: start 43, 1 bit, little-endian, data-type-policy=OVERRIDE, i-signal-type=PRIMITIVE, init-value=0, base-type=BT_STK_Voko_LED, compu {0=Cx0_Aus (CM_STK_Voko_LED_Cx0_Aus), 1=Cx1_Ein (CM_STK_Voko_LED_Cx1_Ein)}, range raw 0..1, transfer-property=TRIGGERED-ON-CHANGE-WITHOUT-REPETITION  # Signalisierung des Standheizungsbetriebs
          signal STK_MaxLeistung_XIX_Standklima_01_XIX_E3V_EVCANFD: start 44, 8 bit, little-endian, data-type-policy=OVERRIDE, i-signal-type=PRIMITIVE, init-value=254, base-type=BT_STK_MaxLeistung, invalid-value=Invalid_STK_MaxLeistung_XIX_Standklima_01_XIX_E3V_EVCANFD:255, compu {phys=raw*0.1 for raw 0..150, 254=Cxfe_Init (CM_STK_MaxLeistung_Cxfe_Init), 255=Cxff_Fehler (CM_STK_MaxLeistung_Cxff_Fehler); unit Unit_KiloWatt}, range phys 0..15 Unit_KiloWatt, raw 0..255, unit=Unit_KiloWatt, transfer-property=PENDING  # Anforderung an HVLM über den Maximalwert der angeforderten Energieleistung für Klima-Vorkonditionierung
          signal STK_GesamtEnergiebedarf_XIX_Standklima_01_XIX_E3V_EVCANFD: start 52, 8 bit, little-endian, data-type-policy=OVERRIDE, i-signal-type=PRIMITIVE, init-value=254, base-type=BT_STK_GesamtEnergiebedarf, invalid-value=Invalid_STK_GesamtEnergiebedarf_XIX_Standklima_01_XIX_E3V_EVCANFD:255, compu {phys=raw*0.1 for raw 0..150, 254=Cxfe_Init (CM_STK_GesamtEnergiebedarf_Cxfe_Init), 255=Cxff_Fehler (CM_STK_GesamtEnergiebedarf_Cxff_Fehler); unit Unit_KiloWattHour}, range phys 0..15 Unit_KiloWattHour, raw 0..255, unit=Unit_KiloWattHour, transfer-property=PENDING  # Für den Klimavorgang benötigte Energie von ca. 15 kWh für Signal STK_GesamtEnergiebedarf
          signal STK_Stecker_Status_XIX_Standklima_01_XIX_E3V_EVCANFD: start 60, 2 bit, little-endian, data-type-policy=OVERRIDE, i-signal-type=PRIMITIVE, base-type=BT_STK_Stecker_Status, compu {0=Cx0_kein_Stecker_erkannt (CM_STK_Stecker_Status_Cx0_kein_Stecker_erkannt), 1=Cx1_AC_Stecker_erkannt (CM_STK_Stecker_Status_Cx1_AC_Stecker_erkannt), 2=Cx2_DC_Stecker_erkannt (CM_STK_Stecker_Status_Cx2_DC_Stecker_erkannt)}, range raw 0..2, transfer-property=PENDING  # Übermittlung Status des Ladesteckers für das Klima Steuergerät
          signal STK_ErwVK_Heckzone2_links_XIX_Standklima_01_XIX_E3V_EVCANFD: start 62, 1 bit, little-endian, data-type-policy=OVERRIDE, i-signal-type=PRIMITIVE, init-value=0, base-type=BT_STK_ErwVK_Heckzone2_links, compu {0=Cx0_nicht_angefordert (CM_STK_ErwVK_Heckzone2_links_Cx0_nicht_angefordert), 1=Cx1_Heckzone2_links_angefordert (CM_STK_ErwVK_Heckzone2_links_Cx1_Heckzone2_links_angefordert)}, range raw 0..1, transfer-property=PENDING  # Anforderung der erweiterten Standklimatisierung in der dritten Sitzreihe links
          signal STK_ErwVK_Heckzone2_rechts_XIX_Standklima_01_XIX_E3V_EVCANFD: start 63, 1 bit, little-endian, data-type-policy=OVERRIDE, i-signal-type=PRIMITIVE, init-value=0, base-type=BT_STK_ErwVK_Heckzone2_rechts, compu {0=Cx0_nicht_angefordert (CM_STK_ErwVK_Heckzone2_rechts_Cx0_nicht_angefordert), 1=Cx1_Heckzone2_rechts_angefordert (CM_STK_ErwVK_Heckzone2_rechts_Cx1_Heckzone2_rechts_angefordert)}, range raw 0..1, transfer-property=PENDING  # Anforderung der erweiterten Standklimatisierung für die dritte Sitzreihe rechts.
      frame Systeminfo_01_XIX_E3V_EVCANFD: id 0x585, to Klima, frame-length=8, can-addressing-mode=STANDARD, can-frame-rx-behavior=CAN-FD, can-frame-tx-behavior=CAN-FD
        pdu Systeminfo_01_XIX_E3V_EVCANFD: length=8, minimum-delay=0.01, transmission-mode-true-timing={cyclic-timing={time-offset=0.0, time-period=1.0}, event-controlled-timing={number-of-repetitions=0, repetition-period=0.0}}, unused-bit-pattern=0  # MQB, MLBevo
          signal SI_Sammel_SG_Fehler_XIX_Systeminfo_01_XIX_E3V_EVCANFD: start 0, 6 bit, little-endian, data-type-policy=OVERRIDE, i-signal-type=PRIMITIVE, init-value=63, base-type=BT_SI_Sammel_SG_Fehler, compu {phys=raw for raw 0..60, 61=Cx3d_Reserviert (CM_SI_Sammel_SG_Fehler_Cx3d_Reserviert), 62=Cx3e_Overflow (CM_SI_Sammel_SG_Fehler_Cx3e_Overflow), 63=Cx3f_ungueltig (CM_SI_Sammel_SG_Fehler_Cx3f_ungueltig)}, range phys 0..60, raw 0..63, transfer-property=PENDING  # Anzahl der gesetzten KD-Fehler direkt angeschlossener Steuergeräte der DK3 und DK4 gemäß 80127. Hinweis: Ein Subbusmaster stellt nur die gesammelte Information der an ihn angeschlossenen Steuergeräte der DK3 und DK4 zur Verfügung. Für ServiceKey Auswertung
          signal SI_P_Mode_gueltig_XIX_Systeminfo_01_XIX_E3V_EVCANFD: start 6, 1 bit, little-endian, data-type-policy=OVERRIDE, i-signal-type=PRIMITIVE, init-value=0, base-type=BT_SI_P_Mode_gueltig, compu {0=Cx0_dezentraler_Produktionsmode (CM_SI_P_Mode_gueltig_Cx0_dezentraler_Produktionsmode), 1=Cx1_zentraler_Produktionsmode (CM_SI_P_Mode_gueltig_Cx1_zentraler_Produktionsmode)}, range raw 0..1, transfer-property=TRIGGERED-ON-CHANGE-WITHOUT-REPETITION, to Klima(timeout 5 s)  # zeigt an, ob es sich um ein Fahrzeug mit zentraler oder dezentraler Steu-erung des Produktionsmodes handelt Siehe Q-LAH Produktionsmode (LAH.DUM.907.AS)
          signal SI_Diagnose_Aktiv_XIX_Systeminfo_01_XIX_E3V_EVCANFD: start 7, 1 bit, little-endian, data-type-policy=OVERRIDE, i-signal-type=PRIMITIVE, init-value=0, base-type=BT_SI_Diagnose_Aktiv, compu {0=Cx0_inaktiv (CM_SI_Diagnose_Aktiv_Cx0_inaktiv), 1=Cx1_aktiv (CM_SI_Diagnose_Aktiv_Cx1_aktiv)}, range raw 0..1, transfer-property=TRIGGERED-ON-CHANGE-WITHOUT-REPETITION  # Gibt an ob Diagnose-Botschaften empfangen werden und somit eine Diagnose aktiv ist. MQB: Gibt an ob Diagnose-Bus Botschaften empfangen werden und somit eine Diagnose aktiv ist.
          signal SI_QRS_Mode_XIX_Systeminfo_01_XIX_E3V_EVCANFD: start 8, 1 bit, little-endian, data-type-policy=OVERRIDE, i-signal-type=PRIMITIVE, init-value=0, base-type=BT_SI_QRS_Mode, compu {0=Cx0_QRS_Messmodus_nicht_aktiv (CM_SI_QRS_Mode_Cx0_QRS_Messmodus_nicht_aktiv), 1=Cx1_QRS_Messmodus_aktiv (CM_SI_QRS_Mode_Cx1_QRS_Messmodus_aktiv)}, range raw 0..1, transfer-property=TRIGGERED-ON-CHANGE-WITHOUT-REPETITION, to Klima(timeout 5 s)  # Messmodus Quick-Ruhestrom
          signal SI_T_Mode_XIX_Systeminfo_01_XIX_E3V_EVCANFD: start 9, 1 bit, little-endian, data-type-policy=OVERRIDE, i-signal-type=PRIMITIVE, init-value=0, base-type=BT_SI_T_Mode, compu {0=Cx0_Transportmodus_nicht_aktiv (CM_SI_T_Mode_Cx0_Transportmodus_nicht_aktiv), 1=Cx1_Transportmodus_aktiv (CM_SI_T_Mode_Cx1_Transportmodus_aktiv)}, range raw 0..1, transfer-property=TRIGGERED-ON-CHANGE-WITHOUT-REPETITION, to Klima(timeout 5 s)  # 0x0: Transportmodus nicht aktiv 0x1: Transportmodus aktiv
          signal SI_NWDF_XIX_Systeminfo_01_XIX_E3V_EVCANFD: start 10, 1 bit, little-endian, data-type-policy=OVERRIDE, i-signal-type=PRIMITIVE, init-value=0, base-type=BT_SI_NWDF, compu {0=Cx0_Ueberwachung_nicht_freigegeben (CM_SI_NWDF_Cx0_Ueberwachung_nicht_freigegeben), 1=Cx1_Ueberwachung_freigegeben (CM_SI_NWDF_Cx1_Ueberwachung_freigegeben)}, range raw 0..1, transfer-property=TRIGGERED-ON-CHANGE-WITHOUT-REPETITION, to Klima(timeout 5 s)  # Netzwerk-Diagnose Freigebe zur zentralen Aktivierung der Netzwerkdiagnose
          signal SI_NWDF_gueltig_XIX_Systeminfo_01_XIX_E3V_EVCANFD: start 11, 1 bit, little-endian, data-type-policy=OVERRIDE, i-signal-type=PRIMITIVE, base-type=BT_SI_NWDF_gueltig, compu {0=Cx0_NWDF_wird_nicht_unterstuetzt (CM_SI_NWDF_gueltig_Cx0_NWDF_wird_nicht_unterstuetzt), 1=Cx1_NWDF_wird_unterstuetzt (CM_SI_NWDF_gueltig_Cx1_NWDF_wird_unterstuetzt)}, range raw 0..1, transfer-property=TRIGGERED-ON-CHANGE-WITHOUT-REPETITION, to Klima(timeout 5 s)  # Gültigkeitsbit zu SI_NWDF gemäß Lastenheft: Zentrale Aktivierung Netzwerkdiagnose
          signal SI_Sammelfehler_XIX_Systeminfo_01_XIX_E3V_EVCANFD: start 12, 1 bit, little-endian, data-type-policy=OVERRIDE, i-signal-type=PRIMITIVE, init-value=0, base-type=BT_SI_Sammelfehler, compu {0=Cx0_kein_Sammelfehler (CM_SI_Sammelfehler_Cx0_kein_Sammelfehler), 1=Cx1_Sammelfehler (CM_SI_Sammelfehler_Cx1_Sammelfehler)}, range raw 0..1, transfer-property=TRIGGERED-ON-CHANGE-WITHOUT-REPETITION  # Sammelfehlermeldung zur Anzeige im Kombi - siehe Spez. Sammelfehlermeldung Hinweis: Einzelne Steuergeräte können zur Anpassung an den Produktionsprozess im Gateway auskodiert werden!
          signal GW_KD_Fehler_XIX_Systeminfo_01_XIX_E3V_EVCANFD: start 13, 1 bit, little-endian, data-type-policy=OVERRIDE, i-signal-type=PRIMITIVE, init-value=0, base-type=BT_GW_KD_Fehler, compu {0=Cx0_kein_KD_Fehler (CM_GW_KD_Fehler_Cx0_kein_KD_Fehler), 1=Cx1_KD_Fehler (CM_GW_KD_Fehler_Cx1_KD_Fehler)}, range raw 0..1, transfer-property=TRIGGERED-ON-CHANGE-WITHOUT-REPETITION  # Kundendienstfehlerbit Gateway zur Anzeige eines im Gateway abgelegten Fehlerspeichereintrages.
          signal SI_T_Schutz_XIX_Systeminfo_01_XIX_E3V_EVCANFD: start 14, 1 bit, little-endian, data-type-policy=OVERRIDE, i-signal-type=PRIMITIVE, init-value=0, base-type=BT_SI_T_Schutz, compu {0=Cx0_Transportschutz_nicht_aktiv (CM_SI_T_Schutz_Cx0_Transportschutz_nicht_aktiv), 1=Cx1_Transportschutz_aktiv (CM_SI_T_Schutz_Cx1_Transportschutz_aktiv)}, range raw 0..1, transfer-property=TRIGGERED-ON-CHANGE-WITHOUT-REPETITION, to Klima(timeout 5 s)  # Transportschutz-Signal, das bei Transportmodus und Motorlauf aktiv bleibt 0x0: Transportschutz nicht aktiv 0x1: Transportschutz aktiv
          signal SI_P_Mode_XIX_Systeminfo_01_XIX_E3V_EVCANFD: start 15, 1 bit, little-endian, data-type-policy=OVERRIDE, i-signal-type=PRIMITIVE, init-value=0, base-type=BT_SI_P_Mode, compu {0=Cx0_inaktiv (CM_SI_P_Mode_Cx0_inaktiv), 1=Cx1_aktiv (CM_SI_P_Mode_Cx1_aktiv)}, range raw 0..1, transfer-property=TRIGGERED-ON-CHANGE-WITHOUT-REPETITION, to Klima(timeout 5 s)  # Zentrale Steuerung des Produktionsmodes gemäß Q-LAH-Produktionsmode (LAH.DUM.907.AS)
          signal SI_BUS_01_XIX_Systeminfo_01_XIX_E3V_EVCANFD: start 16, 1 bit, little-endian, data-type-policy=OVERRIDE, i-signal-type=PRIMITIVE, init-value=1, base-type=BT_SI_BUS_01, compu {0=Cx0_keine_Busruhe (CM_SI_BUS_01_Cx0_keine_Busruhe), 1=Cx1_Busruhe (CM_SI_BUS_01_Cx1_Busruhe)}, range raw 0..1, transfer-property=TRIGGERED-ON-CHANGE-WITHOUT-REPETITION  # MQB/MQB_A0/PQ26: ACAN MQB2020: ACAN(FD) MLBevo: HCAN E3_Volumen: ACAN(FD) MQBw_Baseline: ACAN(FD)
          signal SI_BUS_02_XIX_Systeminfo_01_XIX_E3V_EVCANFD: start 17, 1 bit, little-endian, data-type-policy=OVERRIDE, i-signal-type=PRIMITIVE, init-value=1, base-type=BT_SI_BUS_02, compu {0=Cx0_keine_Busruhe (CM_SI_BUS_02_Cx0_keine_Busruhe), 1=Cx1_Busruhe (CM_SI_BUS_02_Cx1_Busruhe)}, range raw 0..1, transfer-property=TRIGGERED-ON-CHANGE-WITHOUT-REPETITION  # MQB/MQB A0 Standard+, High: FCAN MQB2020: FCAN(FD) MLBevo: Frei E3_Volumen: FCAN(FD) MQBw_Baseline: FCAN(FD)
          signal SI_BUS_03_XIX_Systeminfo_01_XIX_E3V_EVCANFD: start 18, 1 bit, little-endian, data-type-policy=OVERRIDE, i-signal-type=PRIMITIVE, init-value=1, base-type=BT_SI_BUS_03, compu {0=Cx0_keine_Busruhe (CM_SI_BUS_03_Cx0_keine_Busruhe), 1=Cx1_Busruhe (CM_SI_BUS_03_Cx1_Busruhe)}, range raw 0..1, transfer-property=TRIGGERED-ON-CHANGE-WITHOUT-REPETITION  # MQB/MQB A0/PQ26: KCAN MQB2020: KCAN MLBevo: KCAN E3_Volumen: KCAN(HS) / K2CAN(FD) (Buskopplung) MQBw_Baseline: KCAN(HS)
          signal SI_BUS_04_XIX_Systeminfo_01_XIX_E3V_EVCANFD: start 19, 1 bit, little-endian, data-type-policy=OVERRIDE, i-signal-type=PRIMITIVE, init-value=1, base-type=BT_SI_BUS_04, compu {0=Cx0_keine_Busruhe (CM_SI_BUS_04_Cx0_keine_Busruhe), 1=Cx1_Busruhe (CM_SI_BUS_04_Cx1_Busruhe)}, range raw 0..1, transfer-property=TRIGGERED-ON-CHANGE-WITHOUT-REPETITION, to Klima(timeout 5 s)  # MQB/MQB A0 Standard+, High: ICAN MQB2020: ICAN(HS) MLBevo: ICAN E3_Volumen: ABCAN(FD) MQBw_Baseline: ICAN(HS)
          signal SI_BUS_05_XIX_Systeminfo_01_XIX_E3V_EVCANFD: start 20, 1 bit, little-endian, data-type-policy=OVERRIDE, i-signal-type=PRIMITIVE, init-value=1, base-type=BT_SI_BUS_05, compu {0=Cx0_keine_Busruhe (CM_SI_BUS_05_Cx0_keine_Busruhe), 1=Cx1_Busruhe (CM_SI_BUS_05_Cx1_Busruhe)}, range raw 0..1, transfer-property=TRIGGERED-ON-CHANGE-WITHOUT-REPETITION  # MQB/MQB A0/PQ26: DiagCAN MQB2020: DiagCAN(FD) MLBevo: DiagCAN E3_Volumen: DiagCAN(FD) MQBw_Baseline: DiagCAN(FD)
          signal SI_BUS_06_XIX_Systeminfo_01_XIX_E3V_EVCANFD: start 21, 1 bit, little-endian, data-type-policy=OVERRIDE, i-signal-type=PRIMITIVE, init-value=1, base-type=BT_SI_BUS_06, compu {0=Cx0_keine_Busruhe (CM_SI_BUS_06_Cx0_keine_Busruhe), 1=Cx1_Busruhe (CM_SI_BUS_06_Cx1_Busruhe)}, range raw 0..1, transfer-property=TRIGGERED-ON-CHANGE-WITHOUT-REPETITION  # MQB/MQB A0/PQ26: ECAN MQB2020: FASCAN(FD) MLBevo: ECAN E3_Volumen: FASCAN_1(FD) MQBw_Baseline: FASCAN_1(FD)
          signal SI_BUS_07_XIX_Systeminfo_01_XIX_E3V_EVCANFD: start 22, 1 bit, little-endian, data-type-policy=OVERRIDE, i-signal-type=PRIMITIVE, init-value=1, base-type=BT_SI_BUS_07, compu {0=Cx0_keine_Busruhe (CM_SI_BUS_07_Cx0_keine_Busruhe), 1=Cx1_Busruhe (CM_SI_BUS_07_Cx1_Busruhe)}, range raw 0..1, transfer-property=TRIGGERED-ON-CHANGE-WITHOUT-REPETITION  # MQB: LIN1 (Energie) MQB2020: LIN1 (Energie) MLBevo: LIN1 (Energie) E3_Volumen: LIN 1 (Energie) MQBw_Baseline: LIN1 (Energie)
          signal SI_BUS_08_XIX_Systeminfo_01_XIX_E3V_EVCANFD: start 23, 1 bit, little-endian, data-type-policy=OVERRIDE, i-signal-type=PRIMITIVE, init-value=1, base-type=BT_SI_BUS_08, compu {0=Cx0_keine_Busruhe (CM_SI_BUS_08_Cx0_keine_Busruhe), 1=Cx1_Busruhe (CM_SI_BUS_08_Cx1_Busruhe)}, range raw 0..1, transfer-property=TRIGGERED-ON-CHANGE-WITHOUT-REPETITION  # MQB: LIN2 (MFL) MQB2020: LIN2 (MFL) MLBevo: LIN2 (MFL) E3_Volumen: LIN2 (MFL) MQBw_Baseline: LIN2 (MFL)
          signal SI_BUS_09_XIX_Systeminfo_01_XIX_E3V_EVCANFD: start 24, 1 bit, little-endian, data-type-policy=OVERRIDE, i-signal-type=PRIMITIVE, init-value=1, base-type=BT_SI_BUS_09, compu {0=Cx0_keine_Busruhe (CM_SI_BUS_09_Cx0_keine_Busruhe), 1=Cx1_Busruhe (CM_SI_BUS_09_Cx1_Busruhe)}, range raw 0..1, transfer-property=TRIGGERED-ON-CHANGE-WITHOUT-REPETITION  # MQB: LIN3 (unbelegt) MQB2020: LIN3 (Uhr/FES) MLBevo: LIN3 (Energie2) MEB: LIN3 E³ 1.1 UNECE: MDKCAN
          signal SI_BUS_10_XIX_Systeminfo_01_XIX_E3V_EVCANFD: start 25, 1 bit, little-endian, data-type-policy=OVERRIDE, i-signal-type=PRIMITIVE, init-value=1, base-type=BT_SI_BUS_10, compu {0=Cx0_keine_Busruhe (CM_SI_BUS_10_Cx0_keine_Busruhe), 1=Cx1_Busruhe (CM_SI_BUS_10_Cx1_Busruhe)}, range raw 0..1, transfer-property=TRIGGERED-ON-CHANGE-WITHOUT-REPETITION  # MLBevo: Flexray MQB2020: MCAN MQBw_Baseline: FASCAN_2(FD) E³ 1.1 UNECE: FASCAN_2(FD)
          signal SI_BUS_11_XIX_Systeminfo_01_XIX_E3V_EVCANFD: start 26, 1 bit, little-endian, data-type-policy=OVERRIDE, i-signal-type=PRIMITIVE, init-value=1, base-type=BT_SI_BUS_11, compu {0=Cx0_keine_Busruhe (CM_SI_BUS_11_Cx0_keine_Busruhe), 1=Cx1_Busruhe (CM_SI_BUS_11_Cx1_Busruhe)}, range raw 0..1, transfer-property=TRIGGERED-ON-CHANGE-WITHOUT-REPETITION  # MLBevo: Ethernet MEB: LIN4
          signal SI_BUS_12_XIX_Systeminfo_01_XIX_E3V_EVCANFD: start 27, 1 bit, little-endian, data-type-policy=OVERRIDE, i-signal-type=PRIMITIVE, init-value=1, base-type=BT_SI_BUS_12, compu {0=Cx0_keine_Busruhe (CM_SI_BUS_12_Cx0_keine_Busruhe), 1=Cx1_Busruhe (CM_SI_BUS_12_Cx1_Busruhe)}, range raw 0..1, transfer-property=TRIGGERED-ON-CHANGE-WITHOUT-REPETITION  # MQB: unbelegt MLBevo: K2CAN E3_Volumen: MFLCAN MQBw_Baseline: K2CAN(FD)
          signal SI_BUS_13_XIX_Systeminfo_01_XIX_E3V_EVCANFD: start 28, 1 bit, little-endian, data-type-policy=OVERRIDE, i-signal-type=PRIMITIVE, init-value=1, base-type=BT_SI_BUS_13, compu {0=Cx0_keine_Busruhe (CM_SI_BUS_13_Cx0_keine_Busruhe), 1=Cx1_Busruhe (CM_SI_BUS_13_Cx1_Busruhe)}, range raw 0..1, transfer-property=TRIGGERED-ON-CHANGE-WITHOUT-REPETITION  # MQB: unbelegt MLBevo: DCAN MEB: CCAN MQBw_Baseline: K3CAN(FD)
          signal SI_BUS_14_XIX_Systeminfo_01_XIX_E3V_EVCANFD: start 29, 1 bit, little-endian, data-type-policy=OVERRIDE, i-signal-type=PRIMITIVE, init-value=1, base-type=BT_SI_BUS_14, compu {0=Cx0_keine_Busruhe (CM_SI_BUS_14_Cx0_keine_Busruhe), 1=Cx1_Busruhe (CM_SI_BUS_14_Cx1_Busruhe)}, range raw 0..1, transfer-property=TRIGGERED-ON-CHANGE-WITHOUT-REPETITION  # MQB/MQB A0: unbelegt MQB2020: HCAN MLBevo: CCAN E3_Volumen: EVCAN(FD) MQBw_Baseline: EVCANFD(FD)
          signal SI_BUS_15_XIX_Systeminfo_01_XIX_E3V_EVCANFD: start 30, 1 bit, little-endian, data-type-policy=OVERRIDE, i-signal-type=PRIMITIVE, init-value=1, base-type=BT_SI_BUS_15, compu {0=Cx0_keine_Busruhe (CM_SI_BUS_15_Cx0_keine_Busruhe), 1=Cx1_Busruhe (CM_SI_BUS_15_Cx1_Busruhe)}, range raw 0..1, transfer-property=TRIGGERED-ON-CHANGE-WITHOUT-REPETITION  # MQB: frei MQB2020: frei MLBevo: frei MEB: AFSCAN
          signal SI_NWDF_30_XIX_Systeminfo_01_XIX_E3V_EVCANFD: start 31, 1 bit, little-endian, data-type-policy=OVERRIDE, i-signal-type=PRIMITIVE, init-value=0, base-type=BT_SI_NWDF_30, compu {0=Cx0_Ueberwachung_nicht_freigegeben (CM_SI_NWDF_30_Cx0_Ueberwachung_nicht_freigegeben), 1=Cx1_Ueberwachung_freigegeben (CM_SI_NWDF_30_Cx1_Ueberwachung_freigegeben)}, range raw 0..1, transfer-property=PENDING  # Netzwerk-Diagnose Freigabe zur zentralen Aktivierung der Netzwerkdiagnose (keine Ausblendbedingung aktiv)
          signal SI_Bus_Identifikation_XIX_Systeminfo_01_XIX_E3V_EVCANFD: start 32, 8 bit, little-endian, data-type-policy=OVERRIDE, i-signal-type=PRIMITIVE, base-type=BT_SI_Bus_Identifikation, compu {16=Cx10_CAN_Diagnose (CM_SI_Bus_Identifikation_Cx10_CAN_Diagnose), 17=Cx11_CAN_Antrieb (CM_SI_Bus_Identifikation_Cx11_CAN_Antrieb), 18=Cx12_CAN_Komfort (CM_SI_Bus_Identifikation_Cx12_CAN_Komfort), 19=Cx13_CAN_Infotainment (CM_SI_Bus_Identifikation_Cx13_CAN_Infotainment), 20=Cx14_CAN_Fahrwerk (CM_SI_Bus_Identifikation_Cx14_CAN_Fahrwerk), 21=Cx15_CAN_Extended (CM_SI_Bus_Identifikation_Cx15_CAN_Extended), 22=Cx16_CAN_Hybrid (CM_SI_Bus_Identifikation_Cx16_CAN_Hybrid), 23=Cx17_CAN_Lade (CM_SI_Bus_Identifikation_Cx17_CAN_Lade), 24=Cx18_CAN_Kombi (CM_SI_Bus_Identifikation_Cx18_CAN_Kombi), 25=Cx19_CAN_Komfort_2 (CM_SI_Bus_Identifikation_Cx19_CAN_Komfort_2), 26=Cx1a_CAN_AFS (CM_SI_Bus_Identifikation_Cx1a_CAN_AFS), 27=Cx1b_CAN_MIB (CM_SI_Bus_Identifikation_Cx1b_CAN_MIB), 28=Cx1c_CAN_Batterie_BMC (CM_SI_Bus_Identifikation_Cx1c_CAN_Batterie_BMC), 29=Cx1d_CAN_Motor (CM_SI_Bus_Identifikation_Cx1d_CAN_Motor), 31=Cx1f_CAN_Airbag_Sicherheitssysteme (CM_SI_Bus_Identifikation_Cx1f_CAN_Airbag_Sicherheitssysteme), 33=Cx21_CAN_FahrerAssistenzSysteme (CM_SI_Bus_Identifikation_Cx21_CAN_FahrerAssistenzSysteme), 34=Cx22_CAN_Migration (CM_SI_Bus_Identifikation_Cx22_CAN_Migration), 35=Cx23_CAN_Connect (CM_SI_Bus_Identifikation_Cx23_CAN_Connect), 36=Cx24_CAN_AnzeigeBedienung (CM_SI_Bus_Identifikation_Cx24_CAN_AnzeigeBedienung), 37=Cx25_CAN_ElectricalVehicle (CM_SI_Bus_Identifikation_Cx25_CAN_ElectricalVehicle), 40=Cx28_CAN_Telematik (CM_SI_Bus_Identifikation_Cx28_CAN_Telematik), 41=Cx29_CAN_MFL (CM_SI_Bus_Identifikation_Cx29_CAN_MFL), 42=Cx2a_CAN_FahrerAssistenzSysteme_2 (CM_SI_Bus_Identifikation_Cx2a_CAN_FahrerAssistenzSysteme_2), 43=Cx2b_CAN_FahrerAssistenzSysteme_3 (CM_SI_Bus_Identifikation_Cx2b_CAN_FahrerAssistenzSysteme_3), 45=Cx2d_CAN_Fahrwerk_2 (CM_SI_Bus_Identifikation_Cx2d_CAN_Fahrwerk_2), 47=Cx2f_CAN_Komfort_3 (CM_SI_Bus_Identifikation_Cx2f_CAN_Komfort_3), 48=Cx30_FlexRay_A (CM_SI_Bus_Identifikation_Cx30_FlexRay_A), 49=Cx31_FlexRay_B (CM_SI_Bus_Identifikation_Cx31_FlexRay_B), 70=Cx46_CAN_PowerSupply (CM_SI_Bus_Identifikation_Cx46_CAN_PowerSupply), 71=Cx47_CAN_Passenger (CM_SI_Bus_Identifikation_Cx47_CAN_Passenger), 72=Cx48_CAN_Connect_2 (CM_SI_Bus_Identifikation_Cx48_CAN_Connect_2), 73=Cx49_CAN_ElectricalVehicle_2 (CM_SI_Bus_Identifikation_Cx49_CAN_ElectricalVehicle_2), 74=Cx4a_CAN_ElectricalVehicle_3 (CM_SI_Bus_Identifikation_Cx4a_CAN_ElectricalVehicle_3), 75=Cx4b_CAN_ElectricalVehicle_4 (CM_SI_Bus_Identifikation_Cx4b_CAN_ElectricalVehicle_4), 76=Cx4c_CAN_AutonomousDriving_1 (CM_SI_Bus_Identifikation_Cx4c_CAN_AutonomousDriving_1), 77=Cx4d_CAN_AutonomousDriving_2 (CM_SI_Bus_Identifikation_Cx4d_CAN_AutonomousDriving_2), 78=Cx4e_CAN_Drive (CM_SI_Bus_Identifikation_Cx4e_CAN_Drive), 79=Cx4f_CAN_NVEV (CM_SI_Bus_Identifikation_Cx4f_CAN_NVEV), 97=Cx61_VLAN_FAS (CM_SI_Bus_Identifikation_Cx61_VLAN_FAS), 98=Cx62_VLAN_Infotainment (CM_SI_Bus_Identifikation_Cx62_VLAN_Infotainment), 99=Cx63_VLAN_Connect (CM_SI_Bus_Identifikation_Cx63_VLAN_Connect), 100=Cx64_VLAN_Komfort (CM_SI_Bus_Identifikation_Cx64_VLAN_Komfort), 101=Cx65_VLAN_Antrieb (CM_SI_Bus_Identifikation_Cx65_VLAN_Antrieb), 102=Cx66_VLAN_Diagnose (CM_SI_Bus_Identifikation_Cx66_VLAN_Diagnose), 103=Cx67_VLAN_Internet (CM_SI_Bus_Identifikation_Cx67_VLAN_Internet), 104=Cx68_VLAN_Gateway (CM_SI_Bus_Identifikation_Cx68_VLAN_Gateway), 105=Cx69_VLAN_Remote_FC (CM_SI_Bus_Identifikation_Cx69_VLAN_Remote_FC), 106=Cx6a_VLAN_Connect_2 (CM_SI_Bus_Identifikation_Cx6a_VLAN_Connect_2), 107=Cx6b_VLAN_Licht (CM_SI_Bus_Identifikation_Cx6b_VLAN_Licht), 108=Cx6c_VLAN_Charge (CM_SI_Bus_Identifikation_Cx6c_VLAN_Charge), 109=Cx6d_VLAN_Cockpit (CM_SI_Bus_Identifikation_Cx6d_VLAN_Cockpit), 110=Cx6e_VLAN_Connect_3 (CM_SI_Bus_Identifikation_Cx6e_VLAN_Connect_3), 111=Cx6f_VLAN_IoT (CM_SI_Bus_Identifikation_Cx6f_VLAN_IoT), 112=Cx70_VLAN_CarPerformance (CM_SI_Bus_Identifikation_Cx70_VLAN_CarPerformance), 113=Cx71_VLAN_ConMod (CM_SI_Bus_Identifikation_Cx71_VLAN_ConMod), 114=Cx72_VLAN_FAS2 (CM_SI_Bus_Identifikation_Cx72_VLAN_FAS2), 115=Cx73_VLAN_DMZ_1 (CM_SI_Bus_Identifikation_Cx73_VLAN_DMZ_1), 116=Cx74_VLAN_SDS (CM_SI_Bus_Identifikation_Cx74_VLAN_SDS), 117=Cx75_VLAN_Rechenplattform (CM_SI_Bus_Identifikation_Cx75_VLAN_Rechenplattform), 118=Cx76_VLAN_Internet_2 (CM_SI_Bus_Identifikation_Cx76_VLAN_Internet_2), 119=Cx77_VLAN_MaaS (CM_SI_Bus_Identifikation_Cx77_VLAN_MaaS), 176=Cxb0_HCP1_CANFD01 (CM_SI_Bus_Identifikation_Cxb0_HCP1_CANFD01), 177=Cxb1_HCP1_CANFD02 (CM_SI_Bus_Identifikation_Cxb1_HCP1_CANFD02), 178=Cxb2_HCP1_CANFD03 (CM_SI_Bus_Identifikation_Cxb2_HCP1_CANFD03), 179=Cxb3_HCP1_CANFD04 (CM_SI_Bus_Identifikation_Cxb3_HCP1_CANFD04), 180=Cxb4_HCP1_CANFD05 (CM_SI_Bus_Identifikation_Cxb4_HCP1_CANFD05), 181=Cxb5_HCP1_CANFD06 (CM_SI_Bus_Identifikation_Cxb5_HCP1_CANFD06), 182=Cxb6_HCP1_CANFD07 (CM_SI_Bus_Identifikation_Cxb6_HCP1_CANFD07), 183=Cxb7_HCP1_CANFD08 (CM_SI_Bus_Identifikation_Cxb7_HCP1_CANFD08), 186=Cxba_HCP4_CANFD03 (CM_SI_Bus_Identifikation_Cxba_HCP4_CANFD03), 187=Cxbb_HCP4_CANFD04 (CM_SI_Bus_Identifikation_Cxbb_HCP4_CANFD04), 188=Cxbc_HCP1_CANFD09 (CM_SI_Bus_Identifikation_Cxbc_HCP1_CANFD09), 189=Cxbd_HCP4_CANFD06 (CM_SI_Bus_Identifikation_Cxbd_HCP4_CANFD06), 190=Cxbe_HCP4_CANFD07 (CM_SI_Bus_Identifikation_Cxbe_HCP4_CANFD07), 191=Cxbf_HCP4_CANFD08 (CM_SI_Bus_Identifikation_Cxbf_HCP4_CANFD08), 192=Cxc0_HCP4_CANFD09 (CM_SI_Bus_Identifikation_Cxc0_HCP4_CANFD09), 193=Cxc1_HCP4_CANFD10 (CM_SI_Bus_Identifikation_Cxc1_HCP4_CANFD10), 194=Cxc2_HCP1_CANFD10 (CM_SI_Bus_Identifikation_Cxc2_HCP1_CANFD10), 195=Cxc3_ICAS1_CANFD2_HCP5_CANFD02 (CM_SI_Bus_Identifikation_Cxc3_ICAS1_CANFD2_HCP5_CANFD02), 196=Cxc4_HCP1_CANFD11 (CM_SI_Bus_Identifikation_Cxc4_HCP1_CANFD11), 197=Cxc5_WU_HCP1_CANFD (CM_SI_Bus_Identifikation_Cxc5_WU_HCP1_CANFD), 199=Cxc7_WU_HCP2_CANFD (CM_SI_Bus_Identifikation_Cxc7_WU_HCP2_CANFD), 200=Cxc8_WU_HCP3_CANFD (CM_SI_Bus_Identifikation_Cxc8_WU_HCP3_CANFD), 201=Cxc9_WU_HCP4_CANFD (CM_SI_Bus_Identifikation_Cxc9_WU_HCP4_CANFD), 202=Cxca_HCP3_CANFD02 (CM_SI_Bus_Identifikation_Cxca_HCP3_CANFD02), 204=Cxcc_ESC_CANFD (CM_SI_Bus_Identifikation_Cxcc_ESC_CANFD), 205=Cxcd_HCP4_CANFD11 (CM_SI_Bus_Identifikation_Cxcd_HCP4_CANFD11), 206=Cxce_HCP4_CANFD12 (CM_SI_Bus_Identifikation_Cxce_HCP4_CANFD12), 207=Cxcf_CAN_Innenraumsensorik (CM_SI_Bus_Identifikation_Cxcf_CAN_Innenraumsensorik), 212=Cxd4_WU_ConMod_CANFD (CM_SI_Bus_Identifikation_Cxd4_WU_ConMod_CANFD), 213=Cxd5_WU_PASD_CANFD (CM_SI_Bus_Identifikation_Cxd5_WU_PASD_CANFD), 215=Cxd7_CAN_MobileDeviceKey (CM_SI_Bus_Identifikation_Cxd7_CAN_MobileDeviceKey), 217=Cxd9_CAN_Tuerantrieb_VL (CM_SI_Bus_Identifikation_Cxd9_CAN_Tuerantrieb_VL), 218=Cxda_CAN_Tuerantrieb_VR (CM_SI_Bus_Identifikation_Cxda_CAN_Tuerantrieb_VR), 219=Cxdb_CAN_Tuerantrieb_HL (CM_SI_Bus_Identifikation_Cxdb_CAN_Tuerantrieb_HL), 220=Cxdc_CAN_Tuerantrieb_HR (CM_SI_Bus_Identifikation_Cxdc_CAN_Tuerantrieb_HR), 221=Cxdd_CAN_Komfort_4 (CM_SI_Bus_Identifikation_Cxdd_CAN_Komfort_4), 222=Cxde_CAN_Komfort_5 (CM_SI_Bus_Identifikation_Cxde_CAN_Komfort_5)}, range raw 16..222, transfer-property=PENDING  # Das Signal identifiziert den Bus eindeutig. Das Signal ist konstant auf jedem Bus. Der Signalwert entspricht dem Wert "Busnummer" aus der VW80127 Gateway_component_list_databus_identification (0x2A2D) "Bus-Identifier".
          signal SI_CAB_V15_XIX_Systeminfo_01_XIX_E3V_EVCANFD: start 40, 24 bit, opaque, data-type-policy=OVERRIDE, i-signal-type=ARRAY, base-type=BT_SI_CAB_V15, compu {0=Cx0_Init (CM_SI_CAB_V15_Cx0_Init), 1=Cx1_CAB_01_Antrieb (CM_SI_CAB_V15_Cx1_CAB_01_Antrieb), 2=Cx2_CAB_02_Hybrid_Laden (CM_SI_CAB_V15_Cx2_CAB_02_Hybrid_Laden), 4=Cx4_CAB_03_Fahrwerk (CM_SI_CAB_V15_Cx4_CAB_03_Fahrwerk), 8=Cx8_CAB_04_Fahrerassistenz (CM_SI_CAB_V15_Cx8_CAB_04_Fahrerassistenz), 16=Cx10_CAB_05_Komfort (CM_SI_CAB_V15_Cx10_CAB_05_Komfort), 32=Cx20_CAB_06_Anzeige (CM_SI_CAB_V15_Cx20_CAB_06_Anzeige), 64=Cx40_CAB_07_Connect (CM_SI_CAB_V15_Cx40_CAB_07_Connect), 128=Cx80_CAB_08_MIB (CM_SI_CAB_V15_Cx80_CAB_08_MIB), 256=Cx100_CAB_09_Standheizung (CM_SI_CAB_V15_Cx100_CAB_09_Standheizung), 512=Cx200_CAB_10_MDK (CM_SI_CAB_V15_Cx200_CAB_10_MDK), 1024=Cx400_CAB_11_VLAN_Fahrerassistenz (CM_SI_CAB_V15_Cx400_CAB_11_VLAN_Fahrerassistenz), 4096=Cx1000_CAB_13_VLAN_Connect (CM_SI_CAB_V15_Cx1000_CAB_13_VLAN_Connect), 8192=Cx2000_CAB_14_VLAN_Infotainment (CM_SI_CAB_V15_Cx2000_CAB_14_VLAN_Infotainment), 16384=Cx4000_CAB_15_Laden (CM_SI_CAB_V15_Cx4000_CAB_15_Laden), 32768=Cx8000_CAB_16_Licht (CM_SI_CAB_V15_Cx8000_CAB_16_Licht), 65536=Cx10000_CAB_17_RTM (CM_SI_CAB_V15_Cx10000_CAB_17_RTM)}, range raw 0..65536, transfer-property=TRIGGERED-ON-CHANGE-WITHOUT-REPETITION, to Klima(timeout 5 s)  # CAB = Clusteraktivbits (V15)
      frame Temperaturen_01_XIX_E3V_EVCANFD: id 0x1A5555A6, to Klima, frame-length=8, can-addressing-mode=EXTENDED, can-frame-rx-behavior=CAN-FD, can-frame-tx-behavior=CAN-FD
        pdu Temperaturen_01_XIX_E3V_EVCANFD: length=8, transmission-mode-true-timing=cyclic-timing={time-offset=0.0, time-period=1.0}, unused-bit-pattern=0
          signal KBI_QBit_Aussen_Temp_gef_XIX_Temperaturen_01_XIX_E3V_EVCANFD: start 12, 1 bit, little-endian, data-type-policy=OVERRIDE, i-signal-type=PRIMITIVE, init-value=1, base-type=BT_KBI_QBit_Aussen_Temp_gef, compu {0=Cx0_gueltiger_Wert (CM_KBI_QBit_Aussen_Temp_gef_Cx0_gueltiger_Wert), 1=Cx1_Ersatz_Init_oder_Fehlerwert (CM_KBI_QBit_Aussen_Temp_gef_Cx1_Ersatz_Init_oder_Fehlerwert)}, range raw 0..1, transfer-property=PENDING, to Klima(timeout 5 s)  # 0x0 = gültiger Wert 0x1 = Ersatz-, Init- oder Fehlerwert
          signal KBI_Aussen_Temp_gef_XIX_Temperaturen_01_XIX_E3V_EVCANFD: start 16, 8 bit, little-endian, data-type-policy=OVERRIDE, i-signal-type=PRIMITIVE, init-value=254, base-type=BT_KBI_Aussen_Temp_gef, invalid-value=Invalid_KBI_Aussen_Temp_gef_XIX_Temperaturen_01_XIX_E3V_EVCANFD:255, compu {phys=raw*0.5-50 for raw 0..250, 253=Cxfd_nicht_verbaut (CM_KBI_Aussen_Temp_gef_Cxfd_nicht_verbaut) (nicht verbaut), 254=Cxfe_Init (CM_KBI_Aussen_Temp_gef_Cxfe_Init), 255=Cxff_Fehler (CM_KBI_Aussen_Temp_gef_Cxff_Fehler); unit Unit_DegreCelsi}, range phys -50..75 Unit_DegreCelsi, raw 0..255, unit=Unit_DegreCelsi, transfer-property=PENDING, to Klima(timeout 5 s)
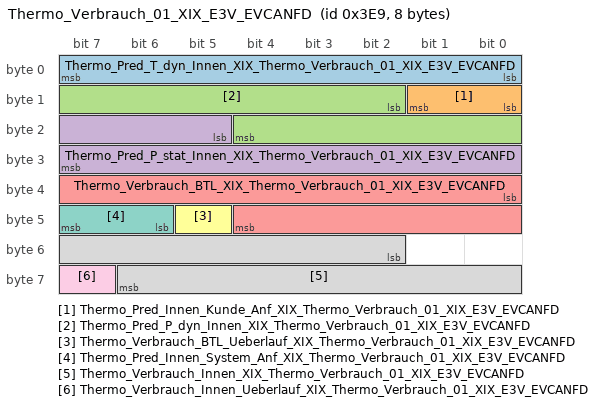
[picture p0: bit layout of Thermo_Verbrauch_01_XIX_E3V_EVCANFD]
      frame Thermo_Verbrauch_01_XIX_E3V_EVCANFD: id 0x3E9, from Klima, frame-length=8, can-addressing-mode=STANDARD, can-frame-rx-behavior=CAN-FD, can-frame-tx-behavior=CAN-FD
        pdu Thermo_Verbrauch_01_XIX_E3V_EVCANFD: length=8, transmission-mode-true-timing=cyclic-timing={time-offset=0.0, time-period=0.1}, unused-bit-pattern=0
          signal Thermo_Pred_T_dyn_Innen_XIX_Thermo_Verbrauch_01_XIX_E3V_EVCANFD: start 0, 8 bit, little-endian, data-type-policy=OVERRIDE, i-signal-type=PRIMITIVE, init-value=254, base-type=BT_Thermo_Pred_T_dyn_Innen, invalid-value=Invalid_Thermo_Pred_T_dyn_Innen_XIX_Thermo_Verbrauch_01_XIX_E3V_EVCANFD:255, compu {phys=raw for raw 0..253, 254=Cxfe_Init (CM_Thermo_Pred_T_dyn_Innen_Cxfe_Init), 255=Cxff_Fehler (CM_Thermo_Pred_T_dyn_Innen_Cxff_Fehler); unit Unit_Minut}, range phys 0..253 Unit_Minut, raw 0..255, unit=Unit_Minut, transfer-property=PENDING  # Zeit bis zum Übergang vom dynamischen in stationären Betrieb
          signal Thermo_Pred_Innen_Kunde_Anf_XIX_Thermo_Verbrauch_01_XIX_E3V_EVCANFD: start 8, 2 bit, little-endian, data-type-policy=OVERRIDE, i-signal-type=PRIMITIVE, init-value=0, base-type=BT_Thermo_Pred_Innen_Kunde_Anf, compu {phys=raw for raw 0..3; unit Unit_None}, range phys 0..3 Unit_None, raw 0..3, unit=Unit_None, transfer-property=PENDING  # Änderung der Prädiktion iniziiert durch Kundenaktion
          signal Thermo_Pred_P_dyn_Innen_XIX_Thermo_Verbrauch_01_XIX_E3V_EVCANFD: start 10, 11 bit, little-endian, data-type-policy=OVERRIDE, i-signal-type=PRIMITIVE, init-value=2046, base-type=BT_Thermo_Pred_P_dyn_Innen, invalid-value=Invalid_Thermo_Pred_P_dyn_Innen_XIX_Thermo_Verbrauch_01_XIX_E3V_EVCANFD:2047, compu {phys=raw*10 for raw 0..2045, 2046=Cx7fe_Init (CM_Thermo_Pred_P_dyn_Innen_Cx7fe_Init), 2047=Cx7ff_Fehler (CM_Thermo_Pred_P_dyn_Innen_Cx7ff_Fehler); unit Unit_Watt}, range phys 0..20450 Unit_Watt, raw 0..2047, unit=Unit_Watt, transfer-property=PENDING  # Dynamsiche Leistung für Headup / Cooldown
          signal Thermo_Pred_P_stat_Innen_XIX_Thermo_Verbrauch_01_XIX_E3V_EVCANFD: start 21, 11 bit, little-endian, data-type-policy=OVERRIDE, i-signal-type=PRIMITIVE, init-value=2046, base-type=BT_Thermo_Pred_P_stat_Innen, invalid-value=Invalid_Thermo_Pred_P_stat_Innen_XIX_Thermo_Verbrauch_01_XIX_E3V_EVCANFD:2047, compu {phys=raw*10 for raw 0..2045, 2046=Cx7fe_Init (CM_Thermo_Pred_P_stat_Innen_Cx7fe_Init), 2047=Cx7ff_Fehler (CM_Thermo_Pred_P_stat_Innen_Cx7ff_Fehler); unit Unit_Watt}, range phys 0..20450 Unit_Watt, raw 0..2047, unit=Unit_Watt, transfer-property=PENDING  # Stationäre Leistung für Heizen / Kühlen
          signal Thermo_Verbrauch_BTL_XIX_Thermo_Verbrauch_01_XIX_E3V_EVCANFD: start 32, 13 bit, little-endian, data-type-policy=OVERRIDE, i-signal-type=PRIMITIVE, init-value=0, base-type=BT_Thermo_Verbrauch_BTL, compu {phys=raw for raw 0..8191; unit Unit_WattSecond}, range phys 0..8191 Unit_WattSecond, raw 0..8191, unit=Unit_WattSecond, transfer-property=PENDING  # Verbrauch für Heizen und Kühlen der Bauteile
          signal Thermo_Verbrauch_BTL_Ueberlauf_XIX_Thermo_Verbrauch_01_XIX_E3V_EVCANFD: start 45, 1 bit, little-endian, data-type-policy=OVERRIDE, i-signal-type=PRIMITIVE, init-value=0, base-type=BT_Thermo_Verbrauch_BTL_Ueberlauf, compu {0=Cx0_kein_Ueberlauf (CM_Thermo_Verbrauch_BTL_Ueberlauf_Cx0_kein_Ueberlauf), 1=Cx1_Ueberlauf (CM_Thermo_Verbrauch_BTL_Ueberlauf_Cx1_Ueberlauf)}, range raw 0..1, transfer-property=PENDING  # Überlauf-Bit Verbrauch Bauteil
          signal Thermo_Pred_Innen_System_Anf_XIX_Thermo_Verbrauch_01_XIX_E3V_EVCANFD: start 46, 2 bit, little-endian, data-type-policy=OVERRIDE, i-signal-type=PRIMITIVE, init-value=0, base-type=BT_Thermo_Pred_Innen_System_Anf, compu {phys=raw for raw 0..3; unit Unit_None}, range phys 0..3 Unit_None, raw 0..3, unit=Unit_None, transfer-property=PENDING  # Systemseitig initiierte Änderung der Prädiktion; Signal ist einheitsloser Zähler mit Überlauf. Eine Inkrementierung steht für die Änderung der Umgebungsbedingungen mit dazugehöriger Klimaleistungsänderung.
          signal Thermo_Verbrauch_Innen_XIX_Thermo_Verbrauch_01_XIX_E3V_EVCANFD: start 50, 13 bit, little-endian, data-type-policy=OVERRIDE, i-signal-type=PRIMITIVE, init-value=0, base-type=BT_Thermo_Verbrauch_Innen, compu {phys=raw for raw 0..8191; unit Unit_WattSecond}, range phys 0..8191 Unit_WattSecond, raw 0..8191, unit=Unit_WattSecond, transfer-property=PENDING  # Verbrauch für Heizen und Kühlen Innenraum
          signal Thermo_Verbrauch_Innen_Ueberlauf_XIX_Thermo_Verbrauch_01_XIX_E3V_EVCANFD: start 63, 1 bit, little-endian, data-type-policy=OVERRIDE, i-signal-type=PRIMITIVE, init-value=0, base-type=BT_Thermo_Verbrauch_Innen_Ueberlauf, compu {0=Cx0_kein_Ueberlauf (CM_Thermo_Verbrauch_Innen_Ueberlauf_Cx0_kein_Ueberlauf), 1=Cx1_Ueberlauf (CM_Thermo_Verbrauch_Innen_Ueberlauf_Cx1_Ueberlauf)}, range raw 0..1, transfer-property=PENDING  # Überlauf-Bit Verbrauch Innenraum
      frame Thermo_Verbrauch_02_XIX_E3V_EVCANFD: id 0x16A954FA, from Klima, frame-length=16, can-addressing-mode=EXTENDED, can-frame-rx-behavior=CAN-FD, can-frame-tx-behavior=CAN-FD
        pdu Thermo_Verbrauch_02_XIX_E3V_EVCANFD: length=16, transmission-mode-true-timing=cyclic-timing={time-offset=0.0, time-period=0.2}, unused-bit-pattern=0
          signal Thermo_Pred_T_dyn_In_Standard_XIX_Thermo_Verbrauch_02_XIX_E3V_EVCANFD: start 12, 8 bit, little-endian, data-type-policy=OVERRIDE, i-signal-type=PRIMITIVE, init-value=254, base-type=BT_Thermo_Pred_T_dyn_In_Standard, invalid-value=Invalid_Thermo_Pred_T_dyn_In_Standard_XIX_Thermo_Verbrauch_02_XIX_E3V_EVCANFD:255, compu {phys=raw for raw 0..253, 254=Cxfe_Init (CM_Thermo_Pred_T_dyn_In_Standard_Cxfe_Init), 255=Cxff_Fehler (CM_Thermo_Pred_T_dyn_In_Standard_Cxff_Fehler); unit Unit_Minut}, range phys 0..253 Unit_Minut, raw 0..255, unit=Unit_Minut, transfer-property=PENDING  # Zeit bis zum Übergang vom dynamischen in stationären Betrieb für Fahrprofil "Standard".
          signal Thermo_Pred_P_stat_In_Standard_XIX_Thermo_Verbrauch_02_XIX_E3V_EVCANFD: start 20, 11 bit, little-endian, data-type-policy=OVERRIDE, i-signal-type=PRIMITIVE, init-value=2046, base-type=BT_Thermo_Pred_P_stat_In_Standard, invalid-value=Invalid_Thermo_Pred_P_stat_In_Standard_XIX_Thermo_Verbrauch_02_XIX_E3V_EVCANFD:2047, compu {phys=raw*10 for raw 0..2045, 2046=Cx7fe_Init (CM_Thermo_Pred_P_stat_In_Standard_Cx7fe_Init), 2047=Cx7ff_Fehler (CM_Thermo_Pred_P_stat_In_Standard_Cx7ff_Fehler); unit Unit_Watt}, range phys 0..20450 Unit_Watt, raw 0..2047, unit=Unit_Watt, transfer-property=PENDING  # Stationäre Leistung für Heizen / Kühlen für Fahrprofil "Standard"
          signal Thermo_Pred_T_dyn_In_Efficien1_XIX_Thermo_Verbrauch_02_XIX_E3V_EVCANFD: start 31, 8 bit, little-endian, data-type-policy=OVERRIDE, i-signal-type=PRIMITIVE, init-value=254, base-type=BT_Thermo_Pred_T_dyn_In_Efficien1, invalid-value=Invalid_Thermo_Pred_T_dyn_In_Efficien1_XIX_Thermo_Verbrauch_02_XIX_E3V_EVCANFD:255, compu {phys=raw for raw 0..253, 254=Cxfe_Init (CM_Thermo_Pred_T_dyn_In_Efficien1_Cxfe_Init), 255=Cxff_Fehler (CM_Thermo_Pred_T_dyn_In_Efficien1_Cxff_Fehler); unit Unit_Minut}, range phys 0..253 Unit_Minut, raw 0..255, unit=Unit_Minut, transfer-property=PENDING  # Zeit bis zum Übergang vom dynamischen in stationären Betrieb für Fahrprofil "Efficiency1"
          signal Thermo_Pred_P_dyn_In_Efficien1_XIX_Thermo_Verbrauch_02_XIX_E3V_EVCANFD: start 39, 11 bit, little-endian, data-type-policy=OVERRIDE, i-signal-type=PRIMITIVE, init-value=2046, base-type=BT_Thermo_Pred_P_dyn_In_Efficien1, invalid-value=Invalid_Thermo_Pred_P_dyn_In_Efficien1_XIX_Thermo_Verbrauch_02_XIX_E3V_EVCANFD:2047, compu {phys=raw*10 for raw 0..2045, 2046=Cx7fe_Init (CM_Thermo_Pred_P_dyn_In_Efficien1_Cx7fe_Init), 2047=Cx7ff_Fehler (CM_Thermo_Pred_P_dyn_In_Efficien1_Cx7ff_Fehler); unit Unit_Watt}, range phys 0..20450 Unit_Watt, raw 0..2047, unit=Unit_Watt, transfer-property=PENDING  # Dynamische Leistung für Heatup / Cooldown für Fahrprofil "Efficiency1"
          signal Thermo_Pred_P_stat_In_Efficien1_XIX_Thermo_Verbrauch_02_XIX_E3V_EVCANFD: start 50, 11 bit, little-endian, data-type-policy=OVERRIDE, i-signal-type=PRIMITIVE, init-value=2046, base-type=BT_Thermo_Pred_P_stat_In_Efficien1, invalid-value=Invalid_Thermo_Pred_P_stat_In_Efficien1_XIX_Thermo_Verbrauch_02_XIX_E3V_EVCANFD:2047, compu {phys=raw*10 for raw 0..2045, 2046=Cx7fe_Init (CM_Thermo_Pred_P_stat_In_Efficien1_Cx7fe_Init), 2047=Cx7ff_Fehler (CM_Thermo_Pred_P_stat_In_Efficien1_Cx7ff_Fehler); unit Unit_Watt}, range phys 0..20450 Unit_Watt, raw 0..2047, unit=Unit_Watt, transfer-property=PENDING  # Stationäre Leistung für Heizen / Kühlen für Fahrprofil "Efficiency1"
          signal Thermo_Pred_P_dyn_In_Efficien2_XIX_Thermo_Verbrauch_02_XIX_E3V_EVCANFD: start 76, 11 bit, little-endian, data-type-policy=OVERRIDE, i-signal-type=PRIMITIVE, init-value=2046, base-type=BT_Thermo_Pred_P_dyn_In_Efficien2, invalid-value=Invalid_Thermo_Pred_P_dyn_In_Efficien2_XIX_Thermo_Verbrauch_02_XIX_E3V_EVCANFD:2047, compu {phys=raw*10 for raw 0..2045, 2046=Cx7fe_Init (CM_Thermo_Pred_P_dyn_In_Efficien2_Cx7fe_Init), 2047=Cx7ff_Fehler (CM_Thermo_Pred_P_dyn_In_Efficien2_Cx7ff_Fehler); unit Unit_Watt}, range phys 0..20450 Unit_Watt, raw 0..2047, unit=Unit_Watt, transfer-property=PENDING  # Dynamische Leistung für Heatup / Cooldown für Fahrprofil "Efficiency2"
          signal Thermo_Pred_P_stat_In_Efficien2_XIX_Thermo_Verbrauch_02_XIX_E3V_EVCANFD: start 87, 11 bit, little-endian, data-type-policy=OVERRIDE, i-signal-type=PRIMITIVE, init-value=2046, base-type=BT_Thermo_Pred_P_stat_In_Efficien2, invalid-value=Invalid_Thermo_Pred_P_stat_In_Efficien2_XIX_Thermo_Verbrauch_02_XIX_E3V_EVCANFD:2047, compu {phys=raw*10 for raw 0..2045, 2046=Cx7fe_Init (CM_Thermo_Pred_P_stat_In_Efficien2_Cx7fe_Init), 2047=Cx7ff_Fehler (CM_Thermo_Pred_P_stat_In_Efficien2_Cx7ff_Fehler); unit Unit_Watt}, range phys 0..20450 Unit_Watt, raw 0..2047, unit=Unit_Watt, transfer-property=PENDING  # Stationäre Leistung für Heizen / Kühlen für Fahrprofil "Efficiency2"
          signal Thermo_Pred_T_dyn_In_Efficien2_XIX_Thermo_Verbrauch_02_XIX_E3V_EVCANFD: start 98, 8 bit, little-endian, data-type-policy=OVERRIDE, i-signal-type=PRIMITIVE, init-value=254, base-type=BT_Thermo_Pred_T_dyn_In_Efficien2, invalid-value=Invalid_Thermo_Pred_T_dyn_In_Efficien2_XIX_Thermo_Verbrauch_02_XIX_E3V_EVCANFD:255, compu {phys=raw for raw 0..253, 254=Cxfe_Init (CM_Thermo_Pred_T_dyn_In_Efficien2_Cxfe_Init), 255=Cxff_Fehler (CM_Thermo_Pred_T_dyn_In_Efficien2_Cxff_Fehler); unit Unit_Minut}, range phys 0..253 Unit_Minut, raw 0..255, unit=Unit_Minut, transfer-property=PENDING  # Zeit bis zum Übergang vom dynamischen in stationären Betrieb für Fahrprofil "Efficiency2"
          signal Thermo_Pred_P_dyn_In_Standard_XIX_Thermo_Verbrauch_02_XIX_E3V_EVCANFD: start 106, 11 bit, little-endian, data-type-policy=OVERRIDE, i-signal-type=PRIMITIVE, init-value=2046, base-type=BT_Thermo_Pred_P_dyn_In_Standard, invalid-value=Invalid_Thermo_Pred_P_dyn_In_Standard_XIX_Thermo_Verbrauch_02_XIX_E3V_EVCANFD:2047, compu {phys=raw*10 for raw 0..2045, 2046=Cx7fe_Init (CM_Thermo_Pred_P_dyn_In_Standard_Cx7fe_Init), 2047=Cx7ff_Fehler (CM_Thermo_Pred_P_dyn_In_Standard_Cx7ff_Fehler); unit Unit_Watt}, range phys 0..20450 Unit_Watt, raw 0..2047, unit=Unit_Watt, transfer-property=PENDING  # Dynamische Leistung für Heatup / Cooldown für Fahrprofil "Standard"
      frame TM_01_XIX_E3V_EVCANFD: id 0x5A7, to Klima, frame-length=8, can-addressing-mode=STANDARD, can-frame-rx-behavior=CAN-FD, can-frame-tx-behavior=CAN-FD
        pdu TM_01_XIX_E3V_EVCANFD: length=8, minimum-delay=0.05, transmission-mode-false-timing={cyclic-timing={time-offset=0.0, time-period=1.0}, event-controlled-timing={number-of-repetitions=0, repetition-period=0.0}}, transmission-mode-true-timing={cyclic-timing={time-offset=0.0, time-period=0.1}, event-controlled-timing={number-of-repetitions=0, repetition-period=0.0}}, unused-bit-pattern=0
          transmission-mode-conditions:
            {data-filter={data-filter-type=MASKED-NEW-DIFFERS-X, mask=1, x=0}, i-signal-in-i-pdu=TM_Spiegel_Anklappen}
            {data-filter={data-filter-type=MASKED-NEW-DIFFERS-X, mask=1, x=0}, i-signal-in-i-pdu=TM_Nur_Hupen}
            {data-filter={data-filter-type=MASKED-NEW-DIFFERS-X, mask=1, x=0}, i-signal-in-i-pdu=TM_Door_Lock}
            {data-filter={data-filter-type=MASKED-NEW-DIFFERS-X, mask=1, x=0}, i-signal-in-i-pdu=TM_Door_Unlock}
            {data-filter={data-filter-type=MASKED-NEW-DIFFERS-X, mask=1, x=0}, i-signal-in-i-pdu=TM_Warnblinken}
            {data-filter={data-filter-type=MASKED-NEW-DIFFERS-X, mask=1, x=0}, i-signal-in-i-pdu=TM_Panik_Alarm}
          signal TM_01_BZ_XIX_TM_01_XIX_E3V_EVCANFD: start 8, 4 bit, little-endian, data-type-policy=OVERRIDE, i-signal-type=PRIMITIVE, init-value=0, base-type=BT_TM_01_BZ, compu {phys=raw for raw 0..15}, range phys 0..15, raw 0..15, transfer-property=PENDING  # 4bit Botschaftszähler, wird mit jeder Sendebotschaft inkrementiert
          signal OCU_Privacymode_Locationdata_XIX_TM_01_XIX_E3V_EVCANFD: start 12, 2 bit, little-endian, data-type-policy=OVERRIDE, i-signal-type=PRIMITIVE, init-value=0, base-type=BT_OCU_Privacymode_Locationdata, compu {0=Cx0_Init (CM_OCU_Privacymode_Locationdata_Cx0_Init), 1=Cx1_locationdata_freigabe (CM_OCU_Privacymode_Locationdata_Cx1_locationdata_freigabe), 2=Cx2_locationdata_gesperrt (CM_OCU_Privacymode_Locationdata_Cx2_locationdata_gesperrt)}, range raw 0..2, transfer-property=PENDING  # Signal zur Ausgabe des speziellen Privacymode Status zur Ausleitung von Fahrzeugpositionsdaten. 0 = Init 1 = Ausgabe der Fahrzeugpositionsdaten ist erlaubt 2 = Ausgabe der Fahrzeugpositionsdaten ist untersagt
          signal OCU_Privacymode_Status_XIX_TM_01_XIX_E3V_EVCANFD: start 14, 2 bit, little-endian, data-type-policy=OVERRIDE, i-signal-type=PRIMITIVE, init-value=0, base-type=BT_OCU_Privacymode_Status, compu {0=Cx0_Init (CM_OCU_Privacymode_Status_Cx0_Init), 1=Cx1_Privacymode_not_active (CM_OCU_Privacymode_Status_Cx1_Privacymode_not_active), 2=Cx2_Privacymode_active (CM_OCU_Privacymode_Status_Cx2_Privacymode_active)}, range raw 0..2, transfer-property=PENDING  # Signal zur Ausgabe des Privacymode Status 0 = Init 1 = Privacymode ist nicht aktiv 2 = Privacymode ist aktiv
          signal MOD_Energie_Anf_XIX_TM_01_XIX_E3V_EVCANFD: start 22, 2 bit, little-endian, data-type-policy=OVERRIDE, i-signal-type=PRIMITIVE, init-value=0, base-type=BT_MOD_Energie_Anf, invalid-value=Invalid_MOD_Energie_Anf_XIX_TM_01_XIX_E3V_EVCANFD:3, compu {0=Cx0_Keine_Anforderung (CM_MOD_Energie_Anf_Cx0_Keine_Anforderung), 1=Cx1_Anforderung_NV (CM_MOD_Energie_Anf_Cx1_Anforderung_NV), 2=Cx2_Anforderung_HV_Nutzung_Erlaubt (CM_MOD_Energie_Anf_Cx2_Anforderung_HV_Nutzung_Erlaubt), 3=Cx3_Fehler (CM_MOD_Energie_Anf_Cx3_Fehler)}, range raw 0..3, transfer-property=PENDING  # Anforderung Energieversorgung MOD-Job an das NVEM
          signal FaceRec_Enroll_Challenge_Request_XIX_TM_01_XIX_E3V_EVCANFD: start 24, 1 bit, little-endian, data-type-policy=OVERRIDE, i-signal-type=PRIMITIVE, init-value=0, base-type=BT_FaceRec_Enroll_Challenge_Request, compu {0=Cx0_SEND_NOTHING (CM_FaceRec_Enroll_Challenge_Request_Cx0_SEND_NOTHING), 1=Cx1_SEND_CHALLENGE (CM_FaceRec_Enroll_Challenge_Request_Cx1_SEND_CHALLENGE)}, range raw 0..1, transfer-property=PENDING  # When FaceRec on MIK receives this signal it will provide a challenge via SOK_FR_Enroll_MIK_Challenge.
          signal eCall_Mute_Anf_XIX_TM_01_XIX_E3V_EVCANFD: start 25, 1 bit, little-endian, data-type-policy=OVERRIDE, i-signal-type=PRIMITIVE, init-value=0, base-type=BT_eCall_Mute_Anf, compu {0=Cx0_kein_mute (CM_eCall_Mute_Anf_Cx0_kein_mute), 1=Cx1_mute (CM_eCall_Mute_Anf_Cx1_mute)}, range raw 0..1, transfer-property=PENDING  # Signalisiert die Aufforderungen alle Soundquellen im Fahrzeug während eines aktiven Notrufs zu muten
          signal iCall_active_XIX_TM_01_XIX_E3V_EVCANFD: start 38, 1 bit, little-endian, data-type-policy=OVERRIDE, i-signal-type=PRIMITIVE, init-value=0, base-type=BT_iCall_active, compu {0=Cx0_inaktiv (CM_iCall_active_Cx0_inaktiv), 1=Cx1_aktiv (CM_iCall_active_Cx1_aktiv)}, range raw 0..1, transfer-property=TRIGGERED-ON-CHANGE-WITHOUT-REPETITION  # Statusrückmeldung von OCU über Infocall aktiv/inaktiv
          signal bCall_active_XIX_TM_01_XIX_E3V_EVCANFD: start 39, 1 bit, little-endian, data-type-policy=OVERRIDE, i-signal-type=PRIMITIVE, base-type=BT_bCall_active, compu {0=Cx0_bcall_inactive (CM_bCall_active_Cx0_bcall_inactive), 1=Cx1_bcall_active (CM_bCall_active_Cx1_bcall_active)}, range raw 0..1, transfer-property=TRIGGERED-ON-CHANGE-WITHOUT-REPETITION  # 1: Breakdown call is active 0: BreakdownCall is inactive
          signal eCall_Funktionsstatus_02_XIX_TM_01_XIX_E3V_EVCANFD: start 41, 3 bit, little-endian, data-type-policy=OVERRIDE, i-signal-type=PRIMITIVE, init-value=7, base-type=BT_eCall_Funktionsstatus_02, compu {0=Cx0_kein_Fehler (CM_eCall_Funktionsstatus_02_Cx0_kein_Fehler), 1=Cx1_Manueller_Notruf_aktiv (CM_eCall_Funktionsstatus_02_Cx1_Manueller_Notruf_aktiv), 2=Cx2_Automatischer_Notruf_aktiv (CM_eCall_Funktionsstatus_02_Cx2_Automatischer_Notruf_aktiv), 7=Cx7_Init (CM_eCall_Funktionsstatus_02_Cx7_Init)}, range raw 0..7, transfer-property=PENDING, to Klima(timeout 5 s)  # Erweiterung des Funktionsstatus für andere Funktionen ACN aktiv, MEC aktiv MEC = manual emergency call = maueller Notruf ACN = automatic emergency call = automatischer Notruf
          signal eCall_Funktionsstatus_XIX_TM_01_XIX_E3V_EVCANFD: start 44, 3 bit, little-endian, data-type-policy=OVERRIDE, i-signal-type=PRIMITIVE, init-value=0, base-type=BT_eCall_Funktionsstatus, compu {0=Cx0_kein_Fehler (CM_eCall_Funktionsstatus_Cx0_kein_Fehler), 1=Cx1_Fkt_eingeschraenkt (CM_eCall_Funktionsstatus_Cx1_Fkt_eingeschraenkt), 2=Cx2_Fkt_eingeschraenkt_service (CM_eCall_Funktionsstatus_Cx2_Fkt_eingeschraenkt_service), 3=Cx3_Fkt_nicht_verfuegbar (CM_eCall_Funktionsstatus_Cx3_Fkt_nicht_verfuegbar), 4=Cx4_Fkt_Service (CM_eCall_Funktionsstatus_Cx4_Fkt_Service), 5=Cx5_Fkt_deaktiviert (CM_eCall_Funktionsstatus_Cx5_Fkt_deaktiviert), 6=Cx6_Fkt_aktiviert (CM_eCall_Funktionsstatus_Cx6_Fkt_aktiviert), 7=Cx7_init (CM_eCall_Funktionsstatus_Cx7_init)}, range raw 0..7, transfer-property=PENDING  # HMI-Aufruf im Kombi (Broadcast) Fehlerfälle die im Kombi angezeigt werden können
          signal TM_Spiegel_Anklappen_XIX_TM_01_XIX_E3V_EVCANFD: start 47, 1 bit, little-endian, data-type-policy=OVERRIDE, i-signal-type=PRIMITIVE, init-value=0, base-type=BT_TM_Spiegel_Anklappen, compu {0=Cx0_Init (CM_TM_Spiegel_Anklappen_Cx0_Init), 1=Cx1_Spiegel_anklappen (CM_TM_Spiegel_Anklappen_Cx1_Spiegel_anklappen)}, range raw 0..1, transfer-property=PENDING  # Anklappen der Außenspiegel über Remote MOD Anforderung
          signal TM_Nur_Hupen_XIX_TM_01_XIX_E3V_EVCANFD: start 48, 1 bit, little-endian, data-type-policy=OVERRIDE, i-signal-type=PRIMITIVE, init-value=0, base-type=BT_TM_Nur_Hupen, compu {0=Cx0_inaktiv (CM_TM_Nur_Hupen_Cx0_inaktiv), 1=Cx1_aktiv (CM_TM_Nur_Hupen_Cx1_aktiv)}, range raw 0..1, transfer-property=PENDING  # Remote Hupen (ohne Blinken) aktiviert
          signal TM_Door_Lock_XIX_TM_01_XIX_E3V_EVCANFD: start 49, 1 bit, little-endian, data-type-policy=OVERRIDE, i-signal-type=PRIMITIVE, init-value=0, base-type=BT_TM_Door_Lock, compu {0=Cx0_Init (CM_TM_Door_Lock_Cx0_Init), 1=Cx1_door_lock (CM_TM_Door_Lock_Cx1_door_lock)}, range raw 0..1, transfer-property=PENDING  # Remote Door lock angefordert: ZV zu/verriegeln
          signal TM_Door_Unlock_XIX_TM_01_XIX_E3V_EVCANFD: start 50, 1 bit, little-endian, data-type-policy=OVERRIDE, i-signal-type=PRIMITIVE, init-value=0, base-type=BT_TM_Door_Unlock, compu {0=Cx0_Init (CM_TM_Door_Unlock_Cx0_Init), 1=Cx1_door_unlock (CM_TM_Door_Unlock_Cx1_door_unlock)}, range raw 0..1, transfer-property=PENDING  # Remote Door unlock angefordert: ZV auf/entriegeln
          signal TM_Warnblinken_XIX_TM_01_XIX_E3V_EVCANFD: start 51, 1 bit, little-endian, data-type-policy=OVERRIDE, i-signal-type=PRIMITIVE, init-value=0, base-type=BT_TM_Warnblinken, compu {0=Cx0_Init (CM_TM_Warnblinken_Cx0_Init), 1=Cx1_Warnblinken_on (CM_TM_Warnblinken_Cx1_Warnblinken_on)}, range raw 0..1, transfer-property=PENDING  # Remote Blinken aktiviert
          signal TM_Panik_Alarm_XIX_TM_01_XIX_E3V_EVCANFD: start 52, 1 bit, little-endian, data-type-policy=OVERRIDE, i-signal-type=PRIMITIVE, init-value=0, base-type=BT_TM_Panik_Alarm, compu {0=Cx0_Init (CM_TM_Panik_Alarm_Cx0_Init), 1=Cx1_panik_alarm_on (CM_TM_Panik_Alarm_Cx1_panik_alarm_on)}, range raw 0..1, transfer-property=PENDING  # Remote Hupen und Blinken aktiv
          signal TM_ZV_Signatur_XIX_TM_01_XIX_E3V_EVCANFD: start 53, 11 bit, little-endian, data-type-policy=OVERRIDE, i-signal-type=PRIMITIVE, init-value=0, base-type=BT_TM_ZV_Signatur, compu {0=Cx0_Init (CM_TM_ZV_Signatur_Cx0_Init), phys=raw for raw 1..2047; unit Unit_None}, range phys 1..2047 Unit_None, raw 0..2047, unit=Unit_None, transfer-property=PENDING  # Gespeicherte Signatur der ZV für Authentifizierung
      frame TSG_BT_01_XIX_E3V_EVCANFD: id 0x3D1, to Klima, frame-length=8, can-addressing-mode=STANDARD, can-frame-rx-behavior=CAN-FD, can-frame-tx-behavior=CAN-FD
        pdu TSG_BT_01_XIX_E3V_EVCANFD: length=8, minimum-delay=0.02, transmission-mode-true-timing={cyclic-timing={time-offset=0.0, time-period=0.1}, event-controlled-timing={number-of-repetitions=0, repetition-period=0.0}}, unused-bit-pattern=0  # ab MQB 7.05
          signal BT_Tuer_geoeffnet_XIX_TSG_BT_01_XIX_E3V_EVCANFD: start 0, 1 bit, little-endian, data-type-policy=OVERRIDE, i-signal-type=PRIMITIVE, init-value=0, base-type=BT_BT_Tuer_geoeffnet, compu {0=Cx0_geschlossen (CM_BT_Tuer_geoeffnet_Cx0_geschlossen), 1=Cx1_offen (CM_BT_Tuer_geoeffnet_Cx1_offen)}, range raw 0..1, transfer-property=TRIGGERED-ON-CHANGE-WITHOUT-REPETITION, to Klima(timeout 1 s)  # Zeigt eine geöffnete Tür an
          signal BT_verriegelt_XIX_TSG_BT_01_XIX_E3V_EVCANFD: start 1, 1 bit, little-endian, data-type-policy=OVERRIDE, i-signal-type=PRIMITIVE, init-value=0, base-type=BT_BT_verriegelt, compu {0=Cx0_Init (CM_BT_verriegelt_Cx0_Init), 1=Cx1_verriegelt (CM_BT_verriegelt_Cx1_verriegelt)}, range raw 0..1, transfer-property=TRIGGERED-ON-CHANGE-WITHOUT-REPETITION  # Zeigt eine verriegelte Tür an ( Status wird erst nach vollständiger Schlossansteuerung ausgegeben (<=1,5sek))
          signal BT_gesafet_XIX_TSG_BT_01_XIX_E3V_EVCANFD: start 2, 1 bit, little-endian, data-type-policy=OVERRIDE, i-signal-type=PRIMITIVE, init-value=0, base-type=BT_BT_gesafet, compu {0=Cx0_Init (CM_BT_gesafet_Cx0_Init), 1=Cx1_gesafet (CM_BT_gesafet_Cx1_gesafet)}, range raw 0..1, transfer-property=TRIGGERED-ON-CHANGE-WITHOUT-REPETITION  # Im Zustand Safe wird auch das Signal BT_verriegelt = 1 gesendet
          signal BT_Schluesselschalter_auf_XIX_TSG_BT_01_XIX_E3V_EVCANFD: start 3, 1 bit, little-endian, data-type-policy=OVERRIDE, i-signal-type=PRIMITIVE, init-value=0, base-type=BT_BT_Schluesselschalter_auf, compu {0=Cx0_Init (CM_BT_Schluesselschalter_auf_Cx0_Init), 1=Cx1_Schluesselschalter_auf_betaetigt (CM_BT_Schluesselschalter_auf_Cx1_Schluesselschalter_auf_betaetigt)}, range raw 0..1, transfer-property=TRIGGERED-ON-CHANGE-WITHOUT-REPETITION  # Schlüsselschalter Richtung auf betätigt
          signal BT_Schluesselschalter_zu_XIX_TSG_BT_01_XIX_E3V_EVCANFD: start 4, 1 bit, little-endian, data-type-policy=OVERRIDE, i-signal-type=PRIMITIVE, init-value=0, base-type=BT_BT_Schluesselschalter_zu, compu {0=Cx0_Init (CM_BT_Schluesselschalter_zu_Cx0_Init), 1=Cx1_Schluesselschalter_zu_betaetigt (CM_BT_Schluesselschalter_zu_Cx1_Schluesselschalter_zu_betaetigt)}, range raw 0..1, transfer-property=TRIGGERED-ON-CHANGE-WITHOUT-REPETITION  # Schluesselschalter Richtung zu betaetigt
          signal BT_Unlock_Taster_XIX_TSG_BT_01_XIX_E3V_EVCANFD: start 5, 1 bit, little-endian, data-type-policy=OVERRIDE, i-signal-type=PRIMITIVE, init-value=0, base-type=BT_BT_Unlock_Taster, compu {0=Cx0_Init (CM_BT_Unlock_Taster_Cx0_Init), 1=Cx1_Unlock_Taster_betaetigt (CM_BT_Unlock_Taster_Cx1_Unlock_Taster_betaetigt)}, range raw 0..1, transfer-property=TRIGGERED-ON-CHANGE-WITHOUT-REPETITION  # Entriegelungstaster betätigt
          signal BT_Lock_Taster_XIX_TSG_BT_01_XIX_E3V_EVCANFD: start 6, 1 bit, little-endian, data-type-policy=OVERRIDE, i-signal-type=PRIMITIVE, init-value=0, base-type=BT_BT_Lock_Taster, compu {0=Cx0_Init (CM_BT_Lock_Taster_Cx0_Init), 1=Cx1_Lock_Taster_betaetigt (CM_BT_Lock_Taster_Cx1_Lock_Taster_betaetigt)}, range raw 0..1, transfer-property=TRIGGERED-ON-CHANGE-WITHOUT-REPETITION  # Verriegelungstaster
          signal BT_Sperrklinke_XIX_TSG_BT_01_XIX_E3V_EVCANFD: start 7, 1 bit, little-endian, data-type-policy=OVERRIDE, i-signal-type=PRIMITIVE, init-value=0, base-type=BT_BT_Sperrklinke, compu {0=Cx0_Schloss_in_Vorraste_und_Hauptraste (CM_BT_Sperrklinke_Cx0_Schloss_in_Vorraste_und_Hauptraste), 1=Cx1_Tuer_auf_oder_Tuer_Position_zwischen_Vor_und_Hauptraste (CM_BT_Sperrklinke_Cx1_Tuer_auf_oder_Tuer_Position_zwischen_Vor_und_Hauptraste)}, range raw 0..1, transfer-property=TRIGGERED-ON-CHANGE-WITHOUT-REPETITION  # Vorraste für Schloß zwischen Vor- und Hauptraste Signal kurz auf 1, danach wieder auf 0 wenn Tür in Hauptraste (Tür ist sicher zu wenn Sperrklinke und Türkontakt auf 0 sind)
          signal BT_TAG_betaetigt_XIX_TSG_BT_01_XIX_E3V_EVCANFD: start 8, 1 bit, little-endian, data-type-policy=OVERRIDE, i-signal-type=PRIMITIVE, init-value=0, base-type=BT_BT_TAG_betaetigt, compu {0=Cx0_Init (CM_BT_TAG_betaetigt_Cx0_Init), 1=Cx1_Tuerinnengriff_betaetigt (CM_BT_TAG_betaetigt_Cx1_Tuerinnengriff_betaetigt)}, range raw 0..1, transfer-property=TRIGGERED-ON-CHANGE-WITHOUT-REPETITION  # Türaussengriff
          signal BT_TIG_betaetigt_XIX_TSG_BT_01_XIX_E3V_EVCANFD: start 9, 1 bit, little-endian, data-type-policy=OVERRIDE, i-signal-type=PRIMITIVE, init-value=0, base-type=BT_BT_TIG_betaetigt, compu {0=Cx0_Init (CM_BT_TIG_betaetigt_Cx0_Init), 1=Cx1_Tuerinnengriff_betaetigt (CM_BT_TIG_betaetigt_Cx1_Tuerinnengriff_betaetigt)}, range raw 0..1, transfer-property=TRIGGERED-ON-CHANGE-WITHOUT-REPETITION  # Türinnengriff
          signal BT_EC_Spiegel_Helligkeit_XIX_TSG_BT_01_XIX_E3V_EVCANFD: start 10, 5 bit, little-endian, data-type-policy=OVERRIDE, i-signal-type=PRIMITIVE, init-value=0, base-type=BT_BT_EC_Spiegel_Helligkeit, compu {phys=raw*3.125 for raw 0..31; unit Unit_PerCent}, range phys 0..96.875 Unit_PerCent, raw 0..31, unit=Unit_PerCent, transfer-property=TRIGGERED-ON-CHANGE-WITHOUT-REPETITION  # Dimmung für den Aussenspiegel in %
          signal BT_Sp_Heizung_Anf_XIX_TSG_BT_01_XIX_E3V_EVCANFD: start 15, 1 bit, little-endian, data-type-policy=OVERRIDE, i-signal-type=PRIMITIVE, init-value=0, base-type=BT_BT_Sp_Heizung_Anf, compu {phys=raw*100 for raw 0..1; unit Unit_PerCent}, range phys 0..100 Unit_PerCent, raw 0..1, unit=Unit_PerCent, transfer-property=PENDING  # Kundenanforderung der Außenspiegelheizung Beifahrertür
          signal BT_Tuer_Status_XIX_TSG_BT_01_XIX_E3V_EVCANFD: start 16, 2 bit, little-endian, data-type-policy=OVERRIDE, i-signal-type=PRIMITIVE, base-type=BT_BT_Tuer_Status, invalid-value=Invalid_BT_Tuer_Status_XIX_TSG_BT_01_XIX_E3V_EVCANFD:3, compu {0=Cx0_Init (CM_BT_Tuer_Status_Cx0_Init), 1=Cx1_Tuer_geschlossen (CM_BT_Tuer_Status_Cx1_Tuer_geschlossen), 2=Cx2_Tuer_offen (CM_BT_Tuer_Status_Cx2_Tuer_offen), 3=Cx3_Fehler (CM_BT_Tuer_Status_Cx3_Fehler)}, range raw 0..3, transfer-property=TRIGGERED-ON-CHANGE-WITHOUT-REPETITION  # Türstatus mit Fehler und Initwert
          signal BT_TSG_hinten_verbaut_XIX_TSG_BT_01_XIX_E3V_EVCANFD: start 18, 1 bit, little-endian, data-type-policy=OVERRIDE, i-signal-type=PRIMITIVE, init-value=0, base-type=BT_BT_TSG_hinten_verbaut, compu {0=Cx0_nicht_verbaut (CM_BT_TSG_hinten_verbaut_Cx0_nicht_verbaut) (nicht verbaut), 1=Cx1_verbaut (CM_BT_TSG_hinten_verbaut_Cx1_verbaut)}, range raw 0..1, transfer-property=TRIGGERED-ON-CHANGE-WITHOUT-REPETITION
          signal BT_Sp_Blk_def_XIX_TSG_BT_01_XIX_E3V_EVCANFD: start 19, 1 bit, little-endian, data-type-policy=OVERRIDE, i-signal-type=PRIMITIVE, init-value=0, base-type=BT_BT_Sp_Blk_def, compu {0=Cx0_iO (CM_BT_Sp_Blk_def_Cx0_iO), 1=Cx1_Spiegel_Blinker_defekt (CM_BT_Sp_Blk_def_Cx1_Spiegel_Blinker_defekt)}, range raw 0..1, transfer-property=TRIGGERED-ON-CHANGE-WITHOUT-REPETITION  # Blinker am Spiegel defekt
          signal BT_FH_S_ManHoch_XIX_TSG_BT_01_XIX_E3V_EVCANFD: start 20, 1 bit, little-endian, data-type-policy=OVERRIDE, i-signal-type=PRIMITIVE, init-value=0, base-type=BT_BT_FH_S_ManHoch, compu {0=Cx0_Init (CM_BT_FH_S_ManHoch_Cx0_Init), 1=Cx1_FH_Schalter_man_hoch_gedrueckt (CM_BT_FH_S_ManHoch_Cx1_FH_Schalter_man_hoch_gedrueckt)}, range raw 0..1, transfer-property=TRIGGERED-ON-CHANGE-WITHOUT-REPETITION  # FH Schalter manuell hoch gedrückt
          signal BT_FH_S_AutoHoch_XIX_TSG_BT_01_XIX_E3V_EVCANFD: start 21, 1 bit, little-endian, data-type-policy=OVERRIDE, i-signal-type=PRIMITIVE, init-value=0, base-type=BT_BT_FH_S_AutoHoch, compu {0=Cx0_Init (CM_BT_FH_S_AutoHoch_Cx0_Init), 1=Cx1_FH_Schalter_auto_hoch_gedrueckt (CM_BT_FH_S_AutoHoch_Cx1_FH_Schalter_auto_hoch_gedrueckt)}, range raw 0..1, transfer-property=TRIGGERED-ON-CHANGE-WITHOUT-REPETITION  # FH Schalter automatisch hoch gedrückt
          signal BT_FH_S_ManTief_XIX_TSG_BT_01_XIX_E3V_EVCANFD: start 22, 1 bit, little-endian, data-type-policy=OVERRIDE, i-signal-type=PRIMITIVE, init-value=0, base-type=BT_BT_FH_S_ManTief, compu {0=Cx0_Init (CM_BT_FH_S_ManTief_Cx0_Init), 1=Cx1_FH_Schalter_man_tief_gedrueckt (CM_BT_FH_S_ManTief_Cx1_FH_Schalter_man_tief_gedrueckt)}, range raw 0..1, transfer-property=TRIGGERED-ON-CHANGE-WITHOUT-REPETITION  # FH Schalter manuell tief gedrückt
          signal BT_FH_S_AutoTief_XIX_TSG_BT_01_XIX_E3V_EVCANFD: start 23, 1 bit, little-endian, data-type-policy=OVERRIDE, i-signal-type=PRIMITIVE, init-value=0, base-type=BT_BT_FH_S_AutoTief, compu {0=Cx0_Init (CM_BT_FH_S_AutoTief_Cx0_Init), 1=Cx1_FH_Schalter_auto_tief_gedrueckt (CM_BT_FH_S_AutoTief_Cx1_FH_Schalter_auto_tief_gedrueckt)}, range raw 0..1, transfer-property=TRIGGERED-ON-CHANGE-WITHOUT-REPETITION  # FH Schalter automatisch tief gedrückt
          signal BT_FH_Oeffnung_XIX_TSG_BT_01_XIX_E3V_EVCANFD: start 24, 8 bit, little-endian, data-type-policy=OVERRIDE, i-signal-type=PRIMITIVE, init-value=0, base-type=BT_BT_FH_Oeffnung, compu {phys=raw*0.5 for raw 0..200; unit Unit_PerCent}, range phys 0..100 Unit_PerCent, raw 0..200, unit=Unit_PerCent, transfer-property=TRIGGERED-ON-CHANGE-WITHOUT-REPETITION, to Klima(timeout 1 s)  # Gibt den Fensteröffnungswert in % an.
          signal BT_FH_Bew_hoch_XIX_TSG_BT_01_XIX_E3V_EVCANFD: start 32, 1 bit, little-endian, data-type-policy=OVERRIDE, i-signal-type=PRIMITIVE, init-value=0, base-type=BT_BT_FH_Bew_hoch, compu {0=Cx0_Init (CM_BT_FH_Bew_hoch_Cx0_Init), 1=Cx1_FH_ist_in_Bewegung_hoch (CM_BT_FH_Bew_hoch_Cx1_FH_ist_in_Bewegung_hoch)}, range raw 0..1, transfer-property=TRIGGERED-ON-CHANGE-WITHOUT-REPETITION  # Fensterheber in Bewegung Richtung hoch
          signal BT_FH_Bew_tief_XIX_TSG_BT_01_XIX_E3V_EVCANFD: start 33, 1 bit, little-endian, data-type-policy=OVERRIDE, i-signal-type=PRIMITIVE, init-value=0, base-type=BT_BT_FH_Bew_tief, compu {0=Cx0_Init (CM_BT_FH_Bew_tief_Cx0_Init), 1=Cx1_FH_ist_in_Bewegung_tief (CM_BT_FH_Bew_tief_Cx1_FH_ist_in_Bewegung_tief)}, range raw 0..1, transfer-property=TRIGGERED-ON-CHANGE-WITHOUT-REPETITION  # Fensterheber in Bewegung Richtung tief
          signal BT_FH_Fang_XIX_TSG_BT_01_XIX_E3V_EVCANFD: start 34, 1 bit, little-endian, data-type-policy=OVERRIDE, i-signal-type=PRIMITIVE, init-value=0, base-type=BT_BT_FH_Fang, compu {0=Cx0_ausserhalb_Fangbereich (CM_BT_FH_Fang_Cx0_ausserhalb_Fangbereich), 1=Cx1_innerhalb_Fangbereich (CM_BT_FH_Fang_Cx1_innerhalb_Fangbereich)}, range raw 0..1, transfer-property=TRIGGERED-ON-CHANGE-WITHOUT-REPETITION  # Fangbereich ist 4mm von oberer Lippendichtung
          signal BT_FH_Block_XIX_TSG_BT_01_XIX_E3V_EVCANFD: start 35, 1 bit, little-endian, data-type-policy=OVERRIDE, i-signal-type=PRIMITIVE, init-value=0, base-type=BT_BT_FH_Block, compu {0=Cx0_Init (CM_BT_FH_Block_Cx0_Init), 1=Cx1_Fensterheber_Block (CM_BT_FH_Block_Cx1_Fensterheber_Block)}, range raw 0..1, transfer-property=TRIGGERED-ON-CHANGE-WITHOUT-REPETITION  # Fensterscheibe befindet sich im mechanischen Block (oben oder unten)
          signal BT_FH_Thermo_XIX_TSG_BT_01_XIX_E3V_EVCANFD: start 36, 1 bit, little-endian, data-type-policy=OVERRIDE, i-signal-type=PRIMITIVE, init-value=0, base-type=BT_BT_FH_Thermo, compu {0=Cx0_Init (CM_BT_FH_Thermo_Cx0_Init), 1=Cx1_Thermoschutz_aktiv (CM_BT_FH_Thermo_Cx1_Thermoschutz_aktiv)}, range raw 0..1, transfer-property=TRIGGERED-ON-CHANGE-WITHOUT-REPETITION  # gibt an ob Fensterheber im Thermoschutz ist
          signal BT_UEKB_aktiviert_XIX_TSG_BT_01_XIX_E3V_EVCANFD: start 37, 1 bit, little-endian, data-type-policy=OVERRIDE, i-signal-type=PRIMITIVE, init-value=0, base-type=BT_BT_UEKB_aktiviert, compu {0=Cx0_Init (CM_BT_UEKB_aktiviert_Cx0_Init), 1=Cx1_aktiv (CM_BT_UEKB_aktiviert_Cx1_aktiv)}, range raw 0..1, transfer-property=TRIGGERED-ON-CHANGE-WITHOUT-REPETITION  # Überschutzbegrenzungskraft bei Reversieren
          signal BT_Kisi_Fehler_XIX_TSG_BT_01_XIX_E3V_EVCANFD: start 38, 1 bit, little-endian, data-type-policy=OVERRIDE, i-signal-type=PRIMITIVE, init-value=0, base-type=BT_BT_Kisi_Fehler, invalid-value=Invalid_BT_Kisi_Fehler_XIX_TSG_BT_01_XIX_E3V_EVCANFD:1, compu {0=Cx0_kein_Fehler (CM_BT_Kisi_Fehler_Cx0_kein_Fehler), 1=Cx1_Fehler (CM_BT_Kisi_Fehler_Cx1_Fehler)}, range raw 0..1, transfer-property=TRIGGERED-ON-CHANGE-WITHOUT-REPETITION  # Fehlerstatus Kindersicherungsfunktion
          signal BT_FH_normiert_XIX_TSG_BT_01_XIX_E3V_EVCANFD: start 39, 1 bit, little-endian, data-type-policy=OVERRIDE, i-signal-type=PRIMITIVE, init-value=0, base-type=BT_BT_FH_normiert, compu {0=Cx0_Init (CM_BT_FH_normiert_Cx0_Init), 1=Cx1_Fenster_normiert (CM_BT_FH_normiert_Cx1_Fenster_normiert)}, range raw 0..1, transfer-property=TRIGGERED-ON-CHANGE-WITHOUT-REPETITION  # Die Position der Fensterheberscheibe ist bekannt
          signal BT_Schliesstaster_XIX_TSG_BT_01_XIX_E3V_EVCANFD: start 40, 1 bit, little-endian, data-type-policy=OVERRIDE, i-signal-type=PRIMITIVE, init-value=0, base-type=BT_BT_Schliesstaster, compu {0=Cx0_nicht_betaetigt (CM_BT_Schliesstaster_Cx0_nicht_betaetigt), 1=Cx1_betaetigt (CM_BT_Schliesstaster_Cx1_betaetigt)}, range raw 0..1, transfer-property=TRIGGERED-ON-CHANGE-WITHOUT-REPETITION  # Schliesstaster Beifahrertür
          signal BT_Zuziehhilfe_aktiv_XIX_TSG_BT_01_XIX_E3V_EVCANFD: start 41, 1 bit, little-endian, data-type-policy=OVERRIDE, i-signal-type=PRIMITIVE, init-value=0, base-type=BT_BT_Zuziehhilfe_aktiv, compu {0=Cx0_Init (CM_BT_Zuziehhilfe_aktiv_Cx0_Init), 1=Cx1_Zuziehhilfe_aktiv (CM_BT_Zuziehhilfe_aktiv_Cx1_Zuziehhilfe_aktiv)}, range raw 0..1, transfer-property=TRIGGERED-ON-CHANGE-WITHOUT-REPETITION  # Zuziehhilfe aktiv
          signal BT_SP_ausgerastet_XIX_TSG_BT_01_XIX_E3V_EVCANFD: start 42, 1 bit, little-endian, data-type-policy=OVERRIDE, i-signal-type=PRIMITIVE, init-value=0, base-type=BT_BT_SP_ausgerastet, compu {0=Cx0_Init (CM_BT_SP_ausgerastet_Cx0_Init), 1=Cx1_Spiegel_ausgerastet (CM_BT_SP_ausgerastet_Cx1_Spiegel_ausgerastet)}, range raw 0..1, transfer-property=TRIGGERED-ON-CHANGE-WITHOUT-REPETITION  # Spiegel ausgerastet
          signal BT_SP_lr_aktiv_XIX_TSG_BT_01_XIX_E3V_EVCANFD: start 43, 1 bit, little-endian, data-type-policy=OVERRIDE, i-signal-type=PRIMITIVE, init-value=0, base-type=BT_BT_SP_lr_aktiv, compu {0=Cx0_Init (CM_BT_SP_lr_aktiv_Cx0_Init), 1=Cx1_Spiegel_xAchse_aktiv (CM_BT_SP_lr_aktiv_Cx1_Spiegel_xAchse_aktiv)}, range raw 0..1, transfer-property=TRIGGERED-ON-CHANGE-WITHOUT-REPETITION  # Spiegelverstellung in Richtung links/rechts aktiv
          signal BT_SP_ht_aktiv_XIX_TSG_BT_01_XIX_E3V_EVCANFD: start 44, 1 bit, little-endian, data-type-policy=OVERRIDE, i-signal-type=PRIMITIVE, init-value=0, base-type=BT_BT_SP_ht_aktiv, compu {0=Cx0_Init (CM_BT_SP_ht_aktiv_Cx0_Init), 1=Cx1_Spiegel_yAchse_aktiv (CM_BT_SP_ht_aktiv_Cx1_Spiegel_yAchse_aktiv)}, range raw 0..1, transfer-property=TRIGGERED-ON-CHANGE-WITHOUT-REPETITION  # Spiegelverstellung in Richtung hoch/tief aktiv
          signal BT_SP_Heizung_aktiv_XIX_TSG_BT_01_XIX_E3V_EVCANFD: start 45, 1 bit, little-endian, data-type-policy=OVERRIDE, i-signal-type=PRIMITIVE, init-value=0, base-type=BT_BT_SP_Heizung_aktiv, compu {0=Cx0_BF_Spiegelheizung_aus (CM_BT_SP_Heizung_aktiv_Cx0_BF_Spiegelheizung_aus), 1=Cx1_BF_Spiegelheizung_ein (CM_BT_SP_Heizung_aktiv_Cx1_BF_Spiegelheizung_ein)}, range raw 0..1, transfer-property=TRIGGERED-ON-CHANGE-WITHOUT-REPETITION  # Zustand Spiegelheizung Beifahrertür
          signal BT_Oben_Block_erw_XIX_TSG_BT_01_XIX_E3V_EVCANFD: start 46, 1 bit, little-endian, data-type-policy=OVERRIDE, i-signal-type=PRIMITIVE, init-value=0, base-type=BT_BT_Oben_Block_erw, compu {0=Cx0_Fensterheber_nicht_in_Blockerwar (CM_BT_Oben_Block_erw_Cx0_Fensterheber_nicht_in_Blockerwar), 1=Cx1_Fensterheber_in_Blockerwartung_o (CM_BT_Oben_Block_erw_Cx1_Fensterheber_in_Blockerwartung_o)}, range raw 0..1, transfer-property=TRIGGERED-ON-CHANGE-WITHOUT-REPETITION  # Fensterheber in Blockerwartung oben
          signal BT_Unten_Block_erw_XIX_TSG_BT_01_XIX_E3V_EVCANFD: start 47, 1 bit, little-endian, data-type-policy=OVERRIDE, i-signal-type=PRIMITIVE, init-value=0, base-type=BT_BT_Unten_Block_erw, compu {0=Cx0_Fensterheber_nicht_in_Blockerwar (CM_BT_Unten_Block_erw_Cx0_Fensterheber_nicht_in_Blockerwar), 1=Cx1_Fensterheber_in_Blockerwartung_u (CM_BT_Unten_Block_erw_Cx1_Fensterheber_in_Blockerwartung_u)}, range raw 0..1, transfer-property=TRIGGERED-ON-CHANGE-WITHOUT-REPETITION  # Fensterheber in Blockerwartung unten
          signal BT_Tuer_Status_QBit_XIX_TSG_BT_01_XIX_E3V_EVCANFD: start 48, 1 bit, little-endian, data-type-policy=OVERRIDE, i-signal-type=PRIMITIVE, init-value=0, base-type=BT_BT_Tuer_Status_QBit, compu {0=Cx0_Status_Tuerkontakt_sicher (CM_BT_Tuer_Status_QBit_Cx0_Status_Tuerkontakt_sicher), 1=Cx1_Status_Tuerkontakt_unsicher (CM_BT_Tuer_Status_QBit_Cx1_Status_Tuerkontakt_unsicher)}, range raw 0..1, transfer-property=PENDING  # Dieses Bit gibt die Zuverlässigkeit des Türkontakts an. Ein auf dieses Bit folgender Fehlereintrag ist mit dem Sender des Bits abzustimmen (gültig ab PPE).
          signal BFS_Status_eTAG_XIX_TSG_BT_01_XIX_E3V_EVCANFD: start 49, 2 bit, little-endian, data-type-policy=OVERRIDE, i-signal-type=PRIMITIVE, init-value=0, base-type=BT_BFS_Status_eTAG, invalid-value=Invalid_BFS_Status_eTAG_XIX_TSG_BT_01_XIX_E3V_EVCANFD:3, compu {0=Cx0_Init (CM_BFS_Status_eTAG_Cx0_Init), 1=Cx1_Griff_ausgefahren (CM_BFS_Status_eTAG_Cx1_Griff_ausgefahren), 2=Cx2_Griff_eingefahren (CM_BFS_Status_eTAG_Cx2_Griff_eingefahren), 3=Cx3_Fehler (CM_BFS_Status_eTAG_Cx3_Fehler)}, range raw 0..3, transfer-property=TRIGGERED-ON-CHANGE-WITHOUT-REPETITION  # Status des elektrischen Tueraussengriffes Beifahrertuer
          signal BT_TCR_Mode_aktiv_XIX_TSG_BT_01_XIX_E3V_EVCANFD: start 51, 1 bit, little-endian, data-type-policy=OVERRIDE, i-signal-type=PRIMITIVE, init-value=0, base-type=BT_BT_TCR_Mode_aktiv, compu {0=Cx0_TCR_Mode_deaktiv (CM_BT_TCR_Mode_aktiv_Cx0_TCR_Mode_deaktiv), 1=Cx1_TCR_Mode_aktiv (CM_BT_TCR_Mode_aktiv_Cx1_TCR_Mode_aktiv)}, range raw 0..1, transfer-property=TRIGGERED-ON-CHANGE-WITHOUT-REPETITION  # Signal zeigt eine aktive mechanische Redundanz am Türschloss an.
          signal BT_Lock_Unlock_Taster_XIX_TSG_BT_01_XIX_E3V_EVCANFD: start 52, 1 bit, little-endian, data-type-policy=OVERRIDE, i-signal-type=PRIMITIVE, init-value=0, base-type=BT_BT_Lock_Unlock_Taster, compu {0=Cx0_nicht_betaetigt (CM_BT_Lock_Unlock_Taster_Cx0_nicht_betaetigt), 1=Cx1_betaetigt (CM_BT_Lock_Unlock_Taster_Cx1_betaetigt)}, range raw 0..1, transfer-property=TRIGGERED-ON-CHANGE-WITHOUT-REPETITION  # ZV Funktion Lock Unlock mit Toggle-Logik
          signal BT_SP_Heizung_Status_XIX_TSG_BT_01_XIX_E3V_EVCANFD: start 55, 1 bit, little-endian, data-type-policy=OVERRIDE, i-signal-type=PRIMITIVE, init-value=0, base-type=BT_BT_SP_Heizung_Status, compu {0=Cx0_Init (CM_BT_SP_Heizung_Status_Cx0_Init), 1=Cx1_Status_Spiegelheizung_ein (CM_BT_SP_Heizung_Status_Cx1_Status_Spiegelheizung_ein)}, range raw 0..1, transfer-property=TRIGGERED-ON-CHANGE-WITHOUT-REPETITION  # Status der Spiegelheizung
          signal ASW_Warnung_aktiv_BFS_XIX_TSG_BT_01_XIX_E3V_EVCANFD: start 56, 1 bit, little-endian, data-type-policy=OVERRIDE, i-signal-type=PRIMITIVE, init-value=0, base-type=BT_ASW_Warnung_aktiv_BFS, compu {0=Cx0_nicht_angefordert (CM_ASW_Warnung_aktiv_BFS_Cx0_nicht_angefordert), 1=Cx1_angefordert (CM_ASW_Warnung_aktiv_BFS_Cx1_angefordert)}, range raw 0..1, transfer-property=TRIGGERED-ON-CHANGE-WITHOUT-REPETITION  # Abschaltung der Ambientefunktion Beifahrertür bei aktiver ASW Warnung an der Fahrertür
          signal BT_FH_Pos_oben_XIX_TSG_BT_01_XIX_E3V_EVCANFD: start 57, 1 bit, little-endian, data-type-policy=OVERRIDE, i-signal-type=PRIMITIVE, init-value=0, base-type=BT_BT_FH_Pos_oben, compu {1=Cx1_Scheibe_oben_nach_Absenken_auf_Position (CM_BT_FH_Pos_oben_Cx1_Scheibe_oben_nach_Absenken_auf_Position) (Scheibe oben (nach Absenken auf Position))}, range raw 1, transfer-property=TRIGGERED-ON-CHANGE-WITHOUT-REPETITION
          signal BT_Tuerschloss_defekt_XIX_TSG_BT_01_XIX_E3V_EVCANFD: start 58, 1 bit, little-endian, data-type-policy=OVERRIDE, i-signal-type=PRIMITIVE, base-type=BT_BT_Tuerschloss_defekt, compu {0=Cx0_Tuerschloss_funktionsfaehig (CM_BT_Tuerschloss_defekt_Cx0_Tuerschloss_funktionsfaehig), 1=Cx1_Tuerschloss_defekt (CM_BT_Tuerschloss_defekt_Cx1_Tuerschloss_defekt)}, range raw 0..1, transfer-property=PENDING  # Das Beifahrertürschloss ist nicht mehr funktionsfähig.
          signal BT_Tueroeffnen_Warnung_XIX_TSG_BT_01_XIX_E3V_EVCANFD: start 59, 1 bit, little-endian, data-type-policy=OVERRIDE, i-signal-type=PRIMITIVE, init-value=0, base-type=BT_BT_Tueroeffnen_Warnung, compu {0=Cx0_Tuerwarnung_nicht_aktiv (CM_BT_Tueroeffnen_Warnung_Cx0_Tuerwarnung_nicht_aktiv), 1=Cx1_Tuerwarnung_aktiv (CM_BT_Tueroeffnen_Warnung_Cx1_Tuerwarnung_aktiv)}, range raw 0..1, transfer-property=TRIGGERED-ON-CHANGE-WITHOUT-REPETITION  # Bit wird gesetzt, wenn Tür während der Fahrt geoeffnet werden soll.
          signal BT_Lock_Taster_inv_XIX_TSG_BT_01_XIX_E3V_EVCANFD: start 60, 1 bit, little-endian, data-type-policy=OVERRIDE, i-signal-type=PRIMITIVE, init-value=0, base-type=BT_BT_Lock_Taster_inv, compu {0=Cx0_Lock_Taster_betaetigt (CM_BT_Lock_Taster_inv_Cx0_Lock_Taster_betaetigt) (Lock Taster betätigt), 1=Cx1_Lock_Taster_nicht_betaetigt (CM_BT_Lock_Taster_inv_Cx1_Lock_Taster_nicht_betaetigt) (Lock Taster nicht betätigt)}, range raw 0..1, transfer-property=TRIGGERED-ON-CHANGE-WITHOUT-REPETITION  # Lock Taster nicht betätigt
          signal BT_Schluesselschalter_zu_inv_XIX_TSG_BT_01_XIX_E3V_EVCANFD: start 61, 1 bit, little-endian, data-type-policy=OVERRIDE, i-signal-type=PRIMITIVE, init-value=0, base-type=BT_BT_Schluesselschalter_zu_inv, compu {0=Cx0_Schluesselschalter_betaetigt (CM_BT_Schluesselschalter_zu_inv_Cx0_Schluesselschalter_betaetigt) (Schlüsselschalter betätigt), 1=Cx1_Schluesselschalter_nicht_betaetigt (CM_BT_Schluesselschalter_zu_inv_Cx1_Schluesselschalter_nicht_betaetigt) (Schlüsselschalter nicht betätigt)}, range raw 0..1, transfer-property=TRIGGERED-ON-CHANGE-WITHOUT-REPETITION  # Schluesselschalter zu nicht betaetigt
          signal BT_SWA_HMI_defekt_XIX_TSG_BT_01_XIX_E3V_EVCANFD: start 62, 1 bit, little-endian, data-type-policy=OVERRIDE, i-signal-type=PRIMITIVE, init-value=0, base-type=BT_BT_SWA_HMI_defekt, compu {0=Cx0_SWA_kein_Fehler (CM_BT_SWA_HMI_defekt_Cx0_SWA_kein_Fehler), 1=Cx1_SWA_Fehler (CM_BT_SWA_HMI_defekt_Cx1_SWA_Fehler)}, range raw 0..1, transfer-property=PENDING  # Zeigt an, ob die SWA-Anzeige defekt ist.
          signal BT_ASW_HMI_defekt_XIX_TSG_BT_01_XIX_E3V_EVCANFD: start 63, 1 bit, little-endian, data-type-policy=OVERRIDE, i-signal-type=PRIMITIVE, init-value=0, base-type=BT_BT_ASW_HMI_defekt, compu {0=Cx0_ASW_kein_Fehler (CM_BT_ASW_HMI_defekt_Cx0_ASW_kein_Fehler), 1=Cx1_ASW_Fehler (CM_BT_ASW_HMI_defekt_Cx1_ASW_Fehler)}, range raw 0..1, transfer-property=PENDING  # Zeigt an, ob die ASW-Anzeige defekt ist.
      frame TSG_FT_01_XIX_E3V_EVCANFD: id 0x3D0, to Klima, frame-length=8, can-addressing-mode=STANDARD, can-frame-rx-behavior=CAN-FD, can-frame-tx-behavior=CAN-FD
        pdu TSG_FT_01_XIX_E3V_EVCANFD: length=8, minimum-delay=0.02, transmission-mode-true-timing={cyclic-timing={time-offset=0.0, time-period=0.1}, event-controlled-timing={number-of-repetitions=0, repetition-period=0.0}}, unused-bit-pattern=0  # ab MQB 7.05
          signal FT_Tuer_geoeffnet_XIX_TSG_FT_01_XIX_E3V_EVCANFD: start 0, 1 bit, little-endian, data-type-policy=OVERRIDE, i-signal-type=PRIMITIVE, init-value=0, base-type=BT_FT_Tuer_geoeffnet, compu {0=Cx0_geschlossen (CM_FT_Tuer_geoeffnet_Cx0_geschlossen), 1=Cx1_Tuer_offen (CM_FT_Tuer_geoeffnet_Cx1_Tuer_offen)}, range raw 0..1, transfer-property=TRIGGERED-ON-CHANGE-WITHOUT-REPETITION, to Klima(timeout 1 s)  # Zeigt eine geöffnete Tür an
          signal FT_verriegelt_XIX_TSG_FT_01_XIX_E3V_EVCANFD: start 1, 1 bit, little-endian, data-type-policy=OVERRIDE, i-signal-type=PRIMITIVE, init-value=0, base-type=BT_FT_verriegelt, compu {0=Cx0_Init (CM_FT_verriegelt_Cx0_Init), 1=Cx1_verriegelt (CM_FT_verriegelt_Cx1_verriegelt)}, range raw 0..1, transfer-property=TRIGGERED-ON-CHANGE-WITHOUT-REPETITION  # Zeigt eine verriegelte Tür an ( Status wird erst nach vollständiger Schlossansteuerung ausgegeben (<=1,5sek))
          signal FT_gesafet_XIX_TSG_FT_01_XIX_E3V_EVCANFD: start 2, 1 bit, little-endian, data-type-policy=OVERRIDE, i-signal-type=PRIMITIVE, init-value=0, base-type=BT_FT_gesafet, compu {0=Cx0_Init (CM_FT_gesafet_Cx0_Init), 1=Cx1_gesafet (CM_FT_gesafet_Cx1_gesafet)}, range raw 0..1, transfer-property=TRIGGERED-ON-CHANGE-WITHOUT-REPETITION  # Im Zustand Safe wird auch das Signal FT_verriegelt = 1 gesendet
          signal FT_Schluesselschalter_auf_XIX_TSG_FT_01_XIX_E3V_EVCANFD: start 3, 1 bit, little-endian, data-type-policy=OVERRIDE, i-signal-type=PRIMITIVE, init-value=0, base-type=BT_FT_Schluesselschalter_auf, compu {0=Cx0_Init (CM_FT_Schluesselschalter_auf_Cx0_Init), 1=Cx1_Schluesselschalter_auf_betaetigt (CM_FT_Schluesselschalter_auf_Cx1_Schluesselschalter_auf_betaetigt)}, range raw 0..1, transfer-property=TRIGGERED-ON-CHANGE-WITHOUT-REPETITION  # Schlüsselschalter Richtung auf betätigt
          signal FT_Schluesselschalter_zu_XIX_TSG_FT_01_XIX_E3V_EVCANFD: start 4, 1 bit, little-endian, data-type-policy=OVERRIDE, i-signal-type=PRIMITIVE, init-value=0, base-type=BT_FT_Schluesselschalter_zu, compu {1=Cx1_Schluesselschalter_zu_betaetigt (CM_FT_Schluesselschalter_zu_Cx1_Schluesselschalter_zu_betaetigt) (Schluesselschalter zu betaetigt)}, range raw 1, transfer-property=TRIGGERED-ON-CHANGE-WITHOUT-REPETITION
          signal FT_Unlock_Taster_XIX_TSG_FT_01_XIX_E3V_EVCANFD: start 5, 1 bit, little-endian, data-type-policy=OVERRIDE, i-signal-type=PRIMITIVE, init-value=0, base-type=BT_FT_Unlock_Taster, compu {0=Cx0_Init (CM_FT_Unlock_Taster_Cx0_Init), 1=Cx1_Unlock_Taster_betaetigt (CM_FT_Unlock_Taster_Cx1_Unlock_Taster_betaetigt)}, range raw 0..1, transfer-property=TRIGGERED-ON-CHANGE-WITHOUT-REPETITION  # Entriegelungstaster betätigt
          signal FT_Lock_Taster_XIX_TSG_FT_01_XIX_E3V_EVCANFD: start 6, 1 bit, little-endian, data-type-policy=OVERRIDE, i-signal-type=PRIMITIVE, init-value=0, base-type=BT_FT_Lock_Taster, compu {0=Cx0_Init (CM_FT_Lock_Taster_Cx0_Init), 1=Cx1_Lock_Taster_betaetigt (CM_FT_Lock_Taster_Cx1_Lock_Taster_betaetigt)}, range raw 0..1, transfer-property=TRIGGERED-ON-CHANGE-WITHOUT-REPETITION  # Verriegelungstaster betätigt
          signal FT_Sperrklinke_XIX_TSG_FT_01_XIX_E3V_EVCANFD: start 7, 1 bit, little-endian, data-type-policy=OVERRIDE, i-signal-type=PRIMITIVE, init-value=0, base-type=BT_FT_Sperrklinke, compu {0=Cx0_Schloss_in_Vorraste_und_Hauptraste (CM_FT_Sperrklinke_Cx0_Schloss_in_Vorraste_und_Hauptraste), 1=Cx1_Tuer_auf_oder_Tuer_Position_zwischen_Vor_und_Hauptraste (CM_FT_Sperrklinke_Cx1_Tuer_auf_oder_Tuer_Position_zwischen_Vor_und_Hauptraste)}, range raw 0..1, transfer-property=TRIGGERED-ON-CHANGE-WITHOUT-REPETITION  # Vorraste für Schloß zwischen Vor- und Hauptraste Signal kurz auf 1, danach wieder auf 0 wenn Tür in Hauptraste (Tür ist sicher zu wenn Sperrklinke und Türkontakt auf 0 sind)
          signal FT_TAG_betaetigt_XIX_TSG_FT_01_XIX_E3V_EVCANFD: start 8, 1 bit, little-endian, data-type-policy=OVERRIDE, i-signal-type=PRIMITIVE, init-value=0, base-type=BT_FT_TAG_betaetigt, compu {0=Cx0_nicht_betaetigt (CM_FT_TAG_betaetigt_Cx0_nicht_betaetigt), 1=Cx1_betaetigt (CM_FT_TAG_betaetigt_Cx1_betaetigt)}, range raw 0..1, transfer-property=TRIGGERED-ON-CHANGE-WITHOUT-REPETITION  # Türaussengriff wird nicht im MLB-B8 verwendet
          signal FT_TIG_betaetigt_XIX_TSG_FT_01_XIX_E3V_EVCANFD: start 9, 1 bit, little-endian, data-type-policy=OVERRIDE, i-signal-type=PRIMITIVE, init-value=0, base-type=BT_FT_TIG_betaetigt, compu {0=Cx0_nicht_betaetigt (CM_FT_TIG_betaetigt_Cx0_nicht_betaetigt), 1=Cx1_betaetigt (CM_FT_TIG_betaetigt_Cx1_betaetigt)}, range raw 0..1, transfer-property=TRIGGERED-ON-CHANGE-WITHOUT-REPETITION  # Türinnengriff wird nicht im MLB-B8 verwendet
          signal FT_IRUE_Taste_XIX_TSG_FT_01_XIX_E3V_EVCANFD: start 10, 1 bit, little-endian, data-type-policy=OVERRIDE, i-signal-type=PRIMITIVE, init-value=0, base-type=BT_FT_IRUE_Taste, compu {0=Cx0_Init (CM_FT_IRUE_Taste_Cx0_Init), 1=Cx1_IRUE_Taste_betaetigt (CM_FT_IRUE_Taste_Cx1_IRUE_Taste_betaetigt)}, range raw 0..1, transfer-property=TRIGGERED-ON-CHANGE-WITHOUT-REPETITION  # Betätigung IRUE-Taster (Innenraumüberwachung) MQB: Bei Verbau eines einzelnen Taster zur Deaktivierung von IRUE und NGS wird dieses Signal als Deaktivierungsanforderung beider DWA-Alarmquellen gesendet.
          signal FT_HD_Taste_XIX_TSG_FT_01_XIX_E3V_EVCANFD: start 11, 1 bit, little-endian, data-type-policy=OVERRIDE, i-signal-type=PRIMITIVE, init-value=0, base-type=BT_FT_HD_Taste, compu {0=Cx0_nicht_betaetigt (CM_FT_HD_Taste_Cx0_nicht_betaetigt), 1=Cx1_Heckdeckeltaste_betaetigt (CM_FT_HD_Taste_Cx1_Heckdeckeltaste_betaetigt)}, range raw 0..1, transfer-property=TRIGGERED-ON-CHANGE-WITHOUT-REPETITION  # Taste in der Fahrertür zum Öffnen des Heckschlosses
          signal FT_TD_Taste_Fehler_XIX_TSG_FT_01_XIX_E3V_EVCANFD: start 12, 1 bit, little-endian, data-type-policy=OVERRIDE, i-signal-type=PRIMITIVE, init-value=0, base-type=BT_FT_TD_Taste_Fehler, compu {0=Cx0_iO (CM_FT_TD_Taste_Fehler_Cx0_iO), 1=Cx1_defekt (CM_FT_TD_Taste_Fehler_Cx1_defekt)}, range raw 0..1, transfer-property=PENDING  # Fehlerstatus des Tankdeckelentriegelungstasters. Wird bei Drucktankkonzepten vom MSG zusammen mit dem Signal FT_TD_Taste ausgewertet, um Tankbereitschaft herzustellen. Der Fehler beschreibt einen hängenden TD_Taster. Ein Kurzschluss oder Leitungsunterbrechung kann nicht diagnostiziert werden.
          signal FT_TD_Taste_XIX_TSG_FT_01_XIX_E3V_EVCANFD: start 13, 1 bit, little-endian, data-type-policy=OVERRIDE, i-signal-type=PRIMITIVE, init-value=0, base-type=BT_FT_TD_Taste, compu {0=Cx0_Init (CM_FT_TD_Taste_Cx0_Init), 1=Cx1_Tankdeckel_Taster_betaetigt (CM_FT_TD_Taste_Cx1_Tankdeckel_Taster_betaetigt)}, range raw 0..1, transfer-property=TRIGGERED-ON-CHANGE-WITHOUT-REPETITION  # Tankdeckelentriegelungs-Taste betätigt
          signal SSR_Temp_Freigabe_XIX_TSG_FT_01_XIX_E3V_EVCANFD: start 14, 1 bit, little-endian, data-type-policy=OVERRIDE, i-signal-type=PRIMITIVE, init-value=0, base-type=BT_SSR_Temp_Freigabe, compu {0=Cx0_SSR_Deaktiviert (CM_SSR_Temp_Freigabe_Cx0_SSR_Deaktiviert), 1=Cx1_SSR_Freigegeben (CM_SSR_Temp_Freigabe_Cx1_SSR_Freigegeben)}, range raw 0..1, transfer-property=PENDING  # Freigabe des Seitenscheibenrollos. Bit wird für die Deaktivierung des SSR bei Innenraumtemperaturen kleiner -10 Grad verwendet.
          signal FT_Sp_Heizung_Anf_XIX_TSG_FT_01_XIX_E3V_EVCANFD: start 15, 1 bit, little-endian, data-type-policy=OVERRIDE, i-signal-type=PRIMITIVE, init-value=0, base-type=BT_FT_Sp_Heizung_Anf, compu {phys=raw*100 for raw 0..1; unit Unit_PerCent}, range phys 0..100 Unit_PerCent, raw 0..1, unit=Unit_PerCent, transfer-property=PENDING  # Kundenanforderung der Außenspiegelheizung Fahrertür
          signal FT_HD_Taste_2_XIX_TSG_FT_01_XIX_E3V_EVCANFD: start 16, 1 bit, little-endian, data-type-policy=OVERRIDE, i-signal-type=PRIMITIVE, init-value=0, base-type=BT_FT_HD_Taste_2, compu {0=Cx0_Taste_nicht_gedrueckt (CM_FT_HD_Taste_2_Cx0_Taste_nicht_gedrueckt), 1=Cx1_Taste_gedrueckt (CM_FT_HD_Taste_2_Cx1_Taste_gedrueckt)}, range raw 0..1, transfer-property=TRIGGERED-ON-CHANGE-WITHOUT-REPETITION  # 2. HD-Taste im Bedienfeld Funktion: Heckdeckel schließen
          signal FT_Lock_Unlock_Taster_XIX_TSG_FT_01_XIX_E3V_EVCANFD: start 17, 1 bit, little-endian, data-type-policy=OVERRIDE, i-signal-type=PRIMITIVE, init-value=0, base-type=BT_FT_Lock_Unlock_Taster, compu {0=Cx0_nicht_betaetigt (CM_FT_Lock_Unlock_Taster_Cx0_nicht_betaetigt), 1=Cx1_betaetigt (CM_FT_Lock_Unlock_Taster_Cx1_betaetigt)}, range raw 0..1, transfer-property=TRIGGERED-ON-CHANGE-WITHOUT-REPETITION  # ZV Funktion Lock Unlock mit Toggle-Logik
          signal FT_TSG_hinten_verbaut_XIX_TSG_FT_01_XIX_E3V_EVCANFD: start 18, 1 bit, little-endian, data-type-policy=OVERRIDE, i-signal-type=PRIMITIVE, init-value=0, base-type=BT_FT_TSG_hinten_verbaut, compu {0=Cx0_nicht_verbaut (CM_FT_TSG_hinten_verbaut_Cx0_nicht_verbaut) (nicht verbaut), 1=Cx1_verbaut (CM_FT_TSG_hinten_verbaut_Cx1_verbaut)}, range raw 0..1, transfer-property=TRIGGERED-ON-CHANGE-WITHOUT-REPETITION
          signal FT_Sp_Blk_def_XIX_TSG_FT_01_XIX_E3V_EVCANFD: start 19, 1 bit, little-endian, data-type-policy=OVERRIDE, i-signal-type=PRIMITIVE, init-value=0, base-type=BT_FT_Sp_Blk_def, compu {0=Cx0_iO (CM_FT_Sp_Blk_def_Cx0_iO), 1=Cx1_defekt (CM_FT_Sp_Blk_def_Cx1_defekt)}, range raw 0..1, transfer-property=TRIGGERED-ON-CHANGE-WITHOUT-REPETITION  # Blinker am Spiegel defekt
          signal FT_FH_S_ManHoch_XIX_TSG_FT_01_XIX_E3V_EVCANFD: start 20, 1 bit, little-endian, data-type-policy=OVERRIDE, i-signal-type=PRIMITIVE, init-value=0, base-type=BT_FT_FH_S_ManHoch, compu {0=Cx0_Init (CM_FT_FH_S_ManHoch_Cx0_Init), 1=Cx1_FH_Schalter_man_hoch_betaetigt (CM_FT_FH_S_ManHoch_Cx1_FH_Schalter_man_hoch_betaetigt)}, range raw 0..1, transfer-property=TRIGGERED-ON-CHANGE-WITHOUT-REPETITION  # FH Schalter manuell hoch gedrückt
          signal FT_FH_S_AutoHoch_XIX_TSG_FT_01_XIX_E3V_EVCANFD: start 21, 1 bit, little-endian, data-type-policy=OVERRIDE, i-signal-type=PRIMITIVE, init-value=0, base-type=BT_FT_FH_S_AutoHoch, compu {0=Cx0_Init (CM_FT_FH_S_AutoHoch_Cx0_Init), 1=Cx1_FH_Schalter_auto_hoch_betaetigt (CM_FT_FH_S_AutoHoch_Cx1_FH_Schalter_auto_hoch_betaetigt)}, range raw 0..1, transfer-property=TRIGGERED-ON-CHANGE-WITHOUT-REPETITION  # FH Schalter automatisch hoch gedrückt
          signal FT_FH_S_ManTief_XIX_TSG_FT_01_XIX_E3V_EVCANFD: start 22, 1 bit, little-endian, data-type-policy=OVERRIDE, i-signal-type=PRIMITIVE, init-value=0, base-type=BT_FT_FH_S_ManTief, compu {0=Cx0_Init (CM_FT_FH_S_ManTief_Cx0_Init), 1=Cx1_FH_Schalter_man_tief_betaetigt (CM_FT_FH_S_ManTief_Cx1_FH_Schalter_man_tief_betaetigt)}, range raw 0..1, transfer-property=TRIGGERED-ON-CHANGE-WITHOUT-REPETITION  # FH Schalter manuell tief gedrückt
          signal FT_FH_S_AutoTief_XIX_TSG_FT_01_XIX_E3V_EVCANFD: start 23, 1 bit, little-endian, data-type-policy=OVERRIDE, i-signal-type=PRIMITIVE, init-value=0, base-type=BT_FT_FH_S_AutoTief, compu {0=Cx0_Init (CM_FT_FH_S_AutoTief_Cx0_Init), 1=Cx1_FH_Schalter_auto_tief_betaetigt (CM_FT_FH_S_AutoTief_Cx1_FH_Schalter_auto_tief_betaetigt)}, range raw 0..1, transfer-property=TRIGGERED-ON-CHANGE-WITHOUT-REPETITION  # FH Schalter automatisch tief gedrückt
          signal FT_FH_Oeffnung_XIX_TSG_FT_01_XIX_E3V_EVCANFD: start 24, 8 bit, little-endian, data-type-policy=OVERRIDE, i-signal-type=PRIMITIVE, init-value=0, base-type=BT_FT_FH_Oeffnung, compu {phys=raw*0.5 for raw 0..200; unit Unit_PerCent}, range phys 0..100 Unit_PerCent, raw 0..200, unit=Unit_PerCent, transfer-property=TRIGGERED-ON-CHANGE-WITHOUT-REPETITION, to Klima(timeout 1 s)  # Gibt den Fensteröffnungswert in % an.
          signal FT_FH_Bew_hoch_XIX_TSG_FT_01_XIX_E3V_EVCANFD: start 32, 1 bit, little-endian, data-type-policy=OVERRIDE, i-signal-type=PRIMITIVE, init-value=0, base-type=BT_FT_FH_Bew_hoch, compu {0=Cx0_Init (CM_FT_FH_Bew_hoch_Cx0_Init), 1=Cx1_FH_in_Bewegung_hoch (CM_FT_FH_Bew_hoch_Cx1_FH_in_Bewegung_hoch)}, range raw 0..1, transfer-property=TRIGGERED-ON-CHANGE-WITHOUT-REPETITION  # Fensterheber in Bewegung Richtung hoch
          signal FT_FH_Bew_tief_XIX_TSG_FT_01_XIX_E3V_EVCANFD: start 33, 1 bit, little-endian, data-type-policy=OVERRIDE, i-signal-type=PRIMITIVE, init-value=0, base-type=BT_FT_FH_Bew_tief, compu {0=Cx0_Init (CM_FT_FH_Bew_tief_Cx0_Init), 1=Cx1_FH_in_Bewegung_tief (CM_FT_FH_Bew_tief_Cx1_FH_in_Bewegung_tief)}, range raw 0..1, transfer-property=TRIGGERED-ON-CHANGE-WITHOUT-REPETITION  # Fensterheber in Bewegung Richtung tief
          signal FT_FH_Fang_XIX_TSG_FT_01_XIX_E3V_EVCANFD: start 34, 1 bit, little-endian, data-type-policy=OVERRIDE, i-signal-type=PRIMITIVE, init-value=0, base-type=BT_FT_FH_Fang, compu {0=Cx0_ausserhalb_Fangbereich (CM_FT_FH_Fang_Cx0_ausserhalb_Fangbereich), 1=Cx1_innerhalb_Fangbereich (CM_FT_FH_Fang_Cx1_innerhalb_Fangbereich)}, range raw 0..1, transfer-property=TRIGGERED-ON-CHANGE-WITHOUT-REPETITION  # Fangbereich ist 4mm von oberer Lippendichtung
          signal FT_FH_Block_XIX_TSG_FT_01_XIX_E3V_EVCANFD: start 35, 1 bit, little-endian, data-type-policy=OVERRIDE, i-signal-type=PRIMITIVE, init-value=0, base-type=BT_FT_FH_Block, compu {0=Cx0_Init (CM_FT_FH_Block_Cx0_Init), 1=Cx1_Fenster_Block (CM_FT_FH_Block_Cx1_Fenster_Block)}, range raw 0..1, transfer-property=TRIGGERED-ON-CHANGE-WITHOUT-REPETITION  # Fensterscheibe befindet sich im mechanischen Block (oben oder unten)
          signal FT_FH_Thermo_XIX_TSG_FT_01_XIX_E3V_EVCANFD: start 36, 1 bit, little-endian, data-type-policy=OVERRIDE, i-signal-type=PRIMITIVE, init-value=0, base-type=BT_FT_FH_Thermo, compu {0=Cx0_Init (CM_FT_FH_Thermo_Cx0_Init), 1=Cx1_Thermoschutz_aktiv (CM_FT_FH_Thermo_Cx1_Thermoschutz_aktiv)}, range raw 0..1, transfer-property=TRIGGERED-ON-CHANGE-WITHOUT-REPETITION  # gibt an ob Fensterheber im Thermoschutz ist
          signal FT_UEKB_aktiviert_XIX_TSG_FT_01_XIX_E3V_EVCANFD: start 37, 1 bit, little-endian, data-type-policy=OVERRIDE, i-signal-type=PRIMITIVE, init-value=0, base-type=BT_FT_UEKB_aktiviert, compu {0=Cx0_Init (CM_FT_UEKB_aktiviert_Cx0_Init), 1=Cx1_UEKB_aktiv (CM_FT_UEKB_aktiviert_Cx1_UEKB_aktiv)}, range raw 0..1, transfer-property=TRIGGERED-ON-CHANGE-WITHOUT-REPETITION  # Überschutzbegrenzungskraft bei Reversieren
          signal ASW_HMI_defekt_XIX_TSG_FT_01_XIX_E3V_EVCANFD: start 38, 1 bit, little-endian, data-type-policy=OVERRIDE, i-signal-type=PRIMITIVE, init-value=0, base-type=BT_ASW_HMI_defekt, compu {0=Cx0_iO (CM_ASW_HMI_defekt_Cx0_iO), 1=Cx1_defekt (CM_ASW_HMI_defekt_Cx1_defekt)}, range raw 0..1, transfer-property=PENDING  # HMI Status der Funktion AusstiegsWarnung (ASW). HMI wird durch das TSG angesteuert.
          signal FT_FH_normiert_XIX_TSG_FT_01_XIX_E3V_EVCANFD: start 39, 1 bit, little-endian, data-type-policy=OVERRIDE, i-signal-type=PRIMITIVE, init-value=0, base-type=BT_FT_FH_normiert, compu {0=Cx0_Init (CM_FT_FH_normiert_Cx0_Init), 1=Cx1_Fenster_normiert (CM_FT_FH_normiert_Cx1_Fenster_normiert)}, range raw 0..1, transfer-property=TRIGGERED-ON-CHANGE-WITHOUT-REPETITION  # Die Position der Fensterheberscheibe ist bekannt
          signal FT_Schliesstaster_XIX_TSG_FT_01_XIX_E3V_EVCANFD: start 40, 1 bit, little-endian, data-type-policy=OVERRIDE, i-signal-type=PRIMITIVE, init-value=0, base-type=BT_FT_Schliesstaster, compu {1=Cx1_Schliesstaster_betaetigt (CM_FT_Schliesstaster_Cx1_Schliesstaster_betaetigt)}, range raw 1, transfer-property=TRIGGERED-ON-CHANGE-WITHOUT-REPETITION  # Vorhalt
          signal FT_Zuziehhilfe_aktiv_XIX_TSG_FT_01_XIX_E3V_EVCANFD: start 41, 1 bit, little-endian, data-type-policy=OVERRIDE, i-signal-type=PRIMITIVE, init-value=0, base-type=BT_FT_Zuziehhilfe_aktiv, compu {0=Cx0_Init (CM_FT_Zuziehhilfe_aktiv_Cx0_Init), 1=Cx1_Zuziehilfe_aktiv (CM_FT_Zuziehhilfe_aktiv_Cx1_Zuziehilfe_aktiv)}, range raw 0..1, transfer-property=TRIGGERED-ON-CHANGE-WITHOUT-REPETITION  # Zuziehhilfe aktiv
          signal FT_SP_ausgerastet_XIX_TSG_FT_01_XIX_E3V_EVCANFD: start 42, 1 bit, little-endian, data-type-policy=OVERRIDE, i-signal-type=PRIMITIVE, init-value=0, base-type=BT_FT_SP_ausgerastet, compu {0=Cx0_Init (CM_FT_SP_ausgerastet_Cx0_Init), 1=Cx1_Spiegel_ausgerastet (CM_FT_SP_ausgerastet_Cx1_Spiegel_ausgerastet)}, range raw 0..1, transfer-property=TRIGGERED-ON-CHANGE-WITHOUT-REPETITION  # Spiegel ausgerastet
          signal FT_SP_lr_aktiv_XIX_TSG_FT_01_XIX_E3V_EVCANFD: start 43, 1 bit, little-endian, data-type-policy=OVERRIDE, i-signal-type=PRIMITIVE, init-value=0, base-type=BT_FT_SP_lr_aktiv, compu {0=Cx0_Init (CM_FT_SP_lr_aktiv_Cx0_Init), 1=Cx1_Spiegel_xAchse_aktiv (CM_FT_SP_lr_aktiv_Cx1_Spiegel_xAchse_aktiv)}, range raw 0..1, transfer-property=TRIGGERED-ON-CHANGE-WITHOUT-REPETITION  # Spiegelverstellung in Richtung links/rechts aktiv
          signal FT_SP_ht_aktiv_XIX_TSG_FT_01_XIX_E3V_EVCANFD: start 44, 1 bit, little-endian, data-type-policy=OVERRIDE, i-signal-type=PRIMITIVE, init-value=0, base-type=BT_FT_SP_ht_aktiv, compu {0=Cx0_Init (CM_FT_SP_ht_aktiv_Cx0_Init), 1=Cx1_Spiegel_yAchse_aktiv (CM_FT_SP_ht_aktiv_Cx1_Spiegel_yAchse_aktiv)}, range raw 0..1, transfer-property=TRIGGERED-ON-CHANGE-WITHOUT-REPETITION  # Spiegelverstellung in Richtung hoch/tief aktiv
          signal ASW_wakeup_XIX_TSG_FT_01_XIX_E3V_EVCANFD: start 45, 1 bit, little-endian, data-type-policy=OVERRIDE, i-signal-type=PRIMITIVE, init-value=0, base-type=BT_ASW_wakeup, compu {0=Cx0_Sleep (CM_ASW_wakeup_Cx0_Sleep), 1=Cx1_Wakeup (CM_ASW_wakeup_Cx1_Wakeup)}, range raw 0..1, transfer-property=TRIGGERED-ON-CHANGE-WITHOUT-REPETITION  # Trigger Start Nachlaufzeit t_1 für die Funktion Ausstieswarnung (ASW)
          signal FT_Oben_Block_erw_XIX_TSG_FT_01_XIX_E3V_EVCANFD: start 46, 1 bit, little-endian, data-type-policy=OVERRIDE, i-signal-type=PRIMITIVE, init-value=0, base-type=BT_FT_Oben_Block_erw, compu {0=Cx0_Fensterheber_nicht_in_Blockerwar (CM_FT_Oben_Block_erw_Cx0_Fensterheber_nicht_in_Blockerwar), 1=Cx1_Fensterheber_in_Blockerwartung_o (CM_FT_Oben_Block_erw_Cx1_Fensterheber_in_Blockerwartung_o)}, range raw 0..1, transfer-property=TRIGGERED-ON-CHANGE-WITHOUT-REPETITION  # Fensterheber in Blockerwartung oben
          signal FT_Unten_Block_erw_XIX_TSG_FT_01_XIX_E3V_EVCANFD: start 47, 1 bit, little-endian, data-type-policy=OVERRIDE, i-signal-type=PRIMITIVE, init-value=0, base-type=BT_FT_Unten_Block_erw, compu {0=Cx0_Fensterheber_nicht_in_Blockerwar (CM_FT_Unten_Block_erw_Cx0_Fensterheber_nicht_in_Blockerwar), 1=Cx1_Fensterheber_in_Blockerwartung_u (CM_FT_Unten_Block_erw_Cx1_Fensterheber_in_Blockerwartung_u)}, range raw 0..1, transfer-property=TRIGGERED-ON-CHANGE-WITHOUT-REPETITION  # Fensterheber in Blockerwartung unten
          signal FT_Kisi_li_aktiv_XIX_TSG_FT_01_XIX_E3V_EVCANFD: start 48, 1 bit, little-endian, data-type-policy=OVERRIDE, i-signal-type=PRIMITIVE, init-value=0, base-type=BT_FT_Kisi_li_aktiv, compu {0=Cx0_inaktiv (CM_FT_Kisi_li_aktiv_Cx0_inaktiv), 1=Cx1_aktiv (CM_FT_Kisi_li_aktiv_Cx1_aktiv)}, range raw 0..1, transfer-property=TRIGGERED-ON-CHANGE-WITHOUT-REPETITION, to Klima  # Aktivierungsstatus der Kindersicherung links
          signal FT_Kisi_re_aktiv_XIX_TSG_FT_01_XIX_E3V_EVCANFD: start 49, 1 bit, little-endian, data-type-policy=OVERRIDE, i-signal-type=PRIMITIVE, init-value=0, base-type=BT_FT_Kisi_re_aktiv, compu {0=Cx0_inaktiv (CM_FT_Kisi_re_aktiv_Cx0_inaktiv), 1=Cx1_aktiv (CM_FT_Kisi_re_aktiv_Cx1_aktiv)}, range raw 0..1, transfer-property=TRIGGERED-ON-CHANGE-WITHOUT-REPETITION  # Aktivierungsstatus der Kindersicherung rechts
          signal FT_Kisi_Taster_li_XIX_TSG_FT_01_XIX_E3V_EVCANFD: start 50, 1 bit, little-endian, data-type-policy=OVERRIDE, i-signal-type=PRIMITIVE, init-value=0, base-type=BT_FT_Kisi_Taster_li, compu {0=Cx0_nicht_betaetigt (CM_FT_Kisi_Taster_li_Cx0_nicht_betaetigt), 1=Cx1_betaetigt (CM_FT_Kisi_Taster_li_Cx1_betaetigt)}, range raw 0..1, transfer-property=TRIGGERED-ON-CHANGE-WITHOUT-REPETITION  # Linker Kisi Taster betaetigt
          signal FT_Kisi_Taster_re_XIX_TSG_FT_01_XIX_E3V_EVCANFD: start 51, 1 bit, little-endian, data-type-policy=OVERRIDE, i-signal-type=PRIMITIVE, init-value=0, base-type=BT_FT_Kisi_Taster_re, compu {0=Cx0_nicht_betaetigt (CM_FT_Kisi_Taster_re_Cx0_nicht_betaetigt), 1=Cx1_betaetigt (CM_FT_Kisi_Taster_re_Cx1_betaetigt)}, range raw 0..1, transfer-property=TRIGGERED-ON-CHANGE-WITHOUT-REPETITION  # Rechter Kisi Taster betaetigt
          signal FT_BFS_Fond_Freigabe_XIX_TSG_FT_01_XIX_E3V_EVCANFD: start 52, 1 bit, little-endian, data-type-policy=OVERRIDE, i-signal-type=PRIMITIVE, init-value=0, base-type=BT_FT_BFS_Fond_Freigabe, compu {0=Cx0_Init (CM_FT_BFS_Fond_Freigabe_Cx0_Init), 1=Cx1_Freigabe_fuer_Fondbedienung_BFS (CM_FT_BFS_Fond_Freigabe_Cx1_Freigabe_fuer_Fondbedienung_BFS)}, range raw 0..1, transfer-property=TRIGGERED-ON-CHANGE-WITHOUT-REPETITION  # Freigabe für Fondverstellung
          signal FT_Kisi_Fehler_XIX_TSG_FT_01_XIX_E3V_EVCANFD: start 53, 1 bit, little-endian, data-type-policy=OVERRIDE, i-signal-type=PRIMITIVE, init-value=0, base-type=BT_FT_Kisi_Fehler, invalid-value=Invalid_FT_Kisi_Fehler_XIX_TSG_FT_01_XIX_E3V_EVCANFD:1, compu {0=Cx0_kein_Fehler (CM_FT_Kisi_Fehler_Cx0_kein_Fehler), 1=Cx1_Fehler (CM_FT_Kisi_Fehler_Cx1_Fehler)}, range raw 0..1, transfer-property=TRIGGERED-ON-CHANGE-WITHOUT-REPETITION  # Fehlerstatus Kindersicherungsfunktion
          signal FT_Daemmglas_XIX_TSG_FT_01_XIX_E3V_EVCANFD: start 54, 1 bit, little-endian, data-type-policy=OVERRIDE, i-signal-type=PRIMITIVE, init-value=0, base-type=BT_FT_Daemmglas, compu {0=Cx0_Normalglas_verbaut (CM_FT_Daemmglas_Cx0_Normalglas_verbaut), 1=Cx1_Daemmglas_verbaut (CM_FT_Daemmglas_Cx1_Daemmglas_verbaut)}, range raw 0..1, transfer-property=TRIGGERED-ON-CHANGE-WITHOUT-REPETITION  # Daemmglas verbaut
          signal FT_SP_Heizung_Status_XIX_TSG_FT_01_XIX_E3V_EVCANFD: start 55, 1 bit, little-endian, data-type-policy=OVERRIDE, i-signal-type=PRIMITIVE, init-value=0, base-type=BT_FT_SP_Heizung_Status, compu {0=Cx0_Init (CM_FT_SP_Heizung_Status_Cx0_Init), 1=Cx1_Status_Spiegelheizung_ein (CM_FT_SP_Heizung_Status_Cx1_Status_Spiegelheizung_ein)}, range raw 0..1, transfer-property=TRIGGERED-ON-CHANGE-WITHOUT-REPETITION  # Status der Spiegelheizung
          signal ASW_Warnung_aktiv_FS_XIX_TSG_FT_01_XIX_E3V_EVCANFD: start 56, 1 bit, little-endian, data-type-policy=OVERRIDE, i-signal-type=PRIMITIVE, init-value=0, base-type=BT_ASW_Warnung_aktiv_FS, compu {0=Cx0_nicht_angefordert (CM_ASW_Warnung_aktiv_FS_Cx0_nicht_angefordert), 1=Cx1_angefordert (CM_ASW_Warnung_aktiv_FS_Cx1_angefordert)}, range raw 0..1, transfer-property=TRIGGERED-ON-CHANGE-WITHOUT-REPETITION  # Abschaltung der Ambientefunktion Fahrertür bei aktiver ASW Warnung an der Fahrertür
          signal FT_FH_Pos_oben_XIX_TSG_FT_01_XIX_E3V_EVCANFD: start 57, 1 bit, little-endian, data-type-policy=OVERRIDE, i-signal-type=PRIMITIVE, init-value=0, base-type=BT_FT_FH_Pos_oben, compu {1=Cx1_Scheibe_oben_nach_Absenken_auf_Position (CM_FT_FH_Pos_oben_Cx1_Scheibe_oben_nach_Absenken_auf_Position) (Scheibe oben (nach Absenken auf Position))}, range raw 1, transfer-property=TRIGGERED-ON-CHANGE-WITHOUT-REPETITION
          signal FT_Tuerschloss_defekt_XIX_TSG_FT_01_XIX_E3V_EVCANFD: start 58, 1 bit, little-endian, data-type-policy=OVERRIDE, i-signal-type=PRIMITIVE, init-value=0, base-type=BT_FT_Tuerschloss_defekt, compu {0=Cx0_Tuerschloss_funktionsfaehig (CM_FT_Tuerschloss_defekt_Cx0_Tuerschloss_funktionsfaehig), 1=Cx1_Tuerschloss_defekt (CM_FT_Tuerschloss_defekt_Cx1_Tuerschloss_defekt)}, range raw 0..1, transfer-property=PENDING  # Das Fahrertürschloss ist nicht mehr funktionsfähig.
          signal FT_SWA_Taster_XIX_TSG_FT_01_XIX_E3V_EVCANFD: start 59, 1 bit, little-endian, data-type-policy=OVERRIDE, i-signal-type=PRIMITIVE, init-value=0, base-type=BT_FT_SWA_Taster, compu {0=Cx0_Taster_nicht_betaetigt (CM_FT_SWA_Taster_Cx0_Taster_nicht_betaetigt), 1=Cx1_Taster_betaetigt (CM_FT_SWA_Taster_Cx1_Taster_betaetigt)}, range raw 0..1, transfer-property=TRIGGERED-ON-CHANGE-WITHOUT-REPETITION  # SWA/ASW Taster Fahrertür
          signal SWA_HMI_Diagnose_XIX_TSG_FT_01_XIX_E3V_EVCANFD: start 60, 2 bit, little-endian, data-type-policy=OVERRIDE, i-signal-type=PRIMITIVE, init-value=0, base-type=BT_SWA_HMI_Diagnose, compu {0=Cx0_kein_Fehler_erkannt (CM_SWA_HMI_Diagnose_Cx0_kein_Fehler_erkannt), 1=Cx1_Fehler_Taster_erkannt (CM_SWA_HMI_Diagnose_Cx1_Fehler_Taster_erkannt), 2=Cx2_Fehler_LED_erkannt (CM_SWA_HMI_Diagnose_Cx2_Fehler_LED_erkannt), 3=Cx3_Fehler_LED_und_Taster_erkannt (CM_SWA_HMI_Diagnose_Cx3_Fehler_LED_und_Taster_erkannt)}, range raw 0..3, transfer-property=PENDING  # SWA HMI Diagnose beim TSG
          signal FS_Status_eTAG_XIX_TSG_FT_01_XIX_E3V_EVCANFD: start 62, 2 bit, little-endian, data-type-policy=OVERRIDE, i-signal-type=PRIMITIVE, init-value=0, base-type=BT_FS_Status_eTAG, invalid-value=Invalid_FS_Status_eTAG_XIX_TSG_FT_01_XIX_E3V_EVCANFD:3, compu {0=Cx0_Init (CM_FS_Status_eTAG_Cx0_Init), 1=Cx1_Griff_ausgefahren (CM_FS_Status_eTAG_Cx1_Griff_ausgefahren), 2=Cx2_Griff_eingefahren (CM_FS_Status_eTAG_Cx2_Griff_eingefahren), 3=Cx3_Fehler (CM_FS_Status_eTAG_Cx3_Fehler)}, range raw 0..3, transfer-property=TRIGGERED-ON-CHANGE-WITHOUT-REPETITION  # Status des elektrischen Tueraussengriffes Fahrertuer
      frame TSG_HBFS_01_XIX_E3V_EVCANFD: id 0x3CF, to Klima, frame-length=8, can-addressing-mode=STANDARD, can-frame-rx-behavior=CAN-FD, can-frame-tx-behavior=CAN-FD
        pdu TSG_HBFS_01_XIX_E3V_EVCANFD: length=8, minimum-delay=0.02, transmission-mode-true-timing={cyclic-timing={time-offset=0.0, time-period=0.1}, event-controlled-timing={number-of-repetitions=0, repetition-period=0.0}}, unused-bit-pattern=0
          signal HBFS_Tuer_geoeffnet_XIX_TSG_HBFS_01_XIX_E3V_EVCANFD: start 0, 1 bit, little-endian, data-type-policy=OVERRIDE, i-signal-type=PRIMITIVE, init-value=0, base-type=BT_HBFS_Tuer_geoeffnet, compu {0=Cx0_geschlossen (CM_HBFS_Tuer_geoeffnet_Cx0_geschlossen), 1=Cx1_offen (CM_HBFS_Tuer_geoeffnet_Cx1_offen)}, range raw 0..1, transfer-property=TRIGGERED-ON-CHANGE-WITHOUT-REPETITION, to Klima(timeout 1 s)  # HBFS Tuer geoeffnet
          signal HBFS_verriegelt_XIX_TSG_HBFS_01_XIX_E3V_EVCANFD: start 1, 1 bit, little-endian, data-type-policy=OVERRIDE, i-signal-type=PRIMITIVE, init-value=0, base-type=BT_HBFS_verriegelt, compu {0=Cx0_nicht_verriegelt (CM_HBFS_verriegelt_Cx0_nicht_verriegelt), 1=Cx1_verriegelt (CM_HBFS_verriegelt_Cx1_verriegelt)}, range raw 0..1, transfer-property=TRIGGERED-ON-CHANGE-WITHOUT-REPETITION  # Verriegelungsstatus Tür
          signal HBFS_gesafet_XIX_TSG_HBFS_01_XIX_E3V_EVCANFD: start 2, 1 bit, little-endian, data-type-policy=OVERRIDE, i-signal-type=PRIMITIVE, init-value=0, base-type=BT_HBFS_gesafet, compu {0=Cx0_nicht_gesafet (CM_HBFS_gesafet_Cx0_nicht_gesafet), 1=Cx1_gesafet (CM_HBFS_gesafet_Cx1_gesafet)}, range raw 0..1, transfer-property=TRIGGERED-ON-CHANGE-WITHOUT-REPETITION  # HBFS Tuer gesafet. Im Zustand Safe wird auch das Signal HBFS_verriegelt = 1 gesendet.
          signal HBFS_Heckrollotaster_betaetigt_XIX_TSG_HBFS_01_XIX_E3V_EVCANFD: start 3, 1 bit, little-endian, data-type-policy=OVERRIDE, i-signal-type=PRIMITIVE, init-value=0, base-type=BT_HBFS_Heckrollotaster_betaetigt, compu {0=Cx0_keine_Verfahranweisung_in_Richtung_Hoch (CM_HBFS_Heckrollotaster_betaetigt_Cx0_keine_Verfahranweisung_in_Richtung_Hoch), 1=Cx1_In_Richtung_Hoch_Verfahren (CM_HBFS_Heckrollotaster_betaetigt_Cx1_In_Richtung_Hoch_Verfahren)}, range raw 0..1, transfer-property=TRIGGERED-ON-CHANGE-WITHOUT-REPETITION  # Verfahren des Heckrollos in Richtung Hoch Bei Einfachtaster wird Bit als Togglebit verwendet (Heckrollo hoch, tief)
          signal HBFS_Tuerschloss_defekt_XIX_TSG_HBFS_01_XIX_E3V_EVCANFD: start 4, 1 bit, little-endian, data-type-policy=OVERRIDE, i-signal-type=PRIMITIVE, base-type=BT_HBFS_Tuerschloss_defekt, compu {0=Cx0_Tuerschloss_funktionsfaehig (CM_HBFS_Tuerschloss_defekt_Cx0_Tuerschloss_funktionsfaehig), 1=Cx1_Tuerschloss_defekt (CM_HBFS_Tuerschloss_defekt_Cx1_Tuerschloss_defekt)}, range raw 0..1, transfer-property=PENDING  # Das hintere Tuerschloss auf der Beifahrerseite ist nicht mehr funktionsfähig.
          signal HBFS_Unlock_Taster_XIX_TSG_HBFS_01_XIX_E3V_EVCANFD: start 5, 1 bit, little-endian, data-type-policy=OVERRIDE, i-signal-type=PRIMITIVE, init-value=0, base-type=BT_HBFS_Unlock_Taster, compu {0=Cx0_nicht_betaetigt (CM_HBFS_Unlock_Taster_Cx0_nicht_betaetigt), 1=Cx1_betaetigt (CM_HBFS_Unlock_Taster_Cx1_betaetigt)}, range raw 0..1, transfer-property=TRIGGERED-ON-CHANGE-WITHOUT-REPETITION  # Betaetigung Unlock Taster
          signal HBFS_Lock_Taster_XIX_TSG_HBFS_01_XIX_E3V_EVCANFD: start 6, 1 bit, little-endian, data-type-policy=OVERRIDE, i-signal-type=PRIMITIVE, init-value=0, base-type=BT_HBFS_Lock_Taster, compu {0=Cx0_nicht_betaetigt (CM_HBFS_Lock_Taster_Cx0_nicht_betaetigt), 1=Cx1_betaetigt (CM_HBFS_Lock_Taster_Cx1_betaetigt)}, range raw 0..1, transfer-property=TRIGGERED-ON-CHANGE-WITHOUT-REPETITION  # Betaetigung Lock-Taster
          signal HBFS_Sperrklinke_XIX_TSG_HBFS_01_XIX_E3V_EVCANFD: start 7, 1 bit, little-endian, data-type-policy=OVERRIDE, i-signal-type=PRIMITIVE, init-value=0, base-type=BT_HBFS_Sperrklinke, compu {0=Cx0_Schloss_in_Vorraste_und_Hauptraste (CM_HBFS_Sperrklinke_Cx0_Schloss_in_Vorraste_und_Hauptraste), 1=Cx1_Tuer_auf_oder_Tuer_Position_zwischen_Vor_und_Hauptraste (CM_HBFS_Sperrklinke_Cx1_Tuer_auf_oder_Tuer_Position_zwischen_Vor_und_Hauptraste)}, range raw 0..1, transfer-property=TRIGGERED-ON-CHANGE-WITHOUT-REPETITION  # Vorraste für Schloß zwischen Vor- und Hauptraste Signal kurz auf 1, danach wieder auf 0 wenn Tür in Hauptraste (Tür ist sicher zu wenn Sperrklinke und Türkontakt auf 0 sind)
          signal HBFS_TAG_betaetigt_XIX_TSG_HBFS_01_XIX_E3V_EVCANFD: start 8, 1 bit, little-endian, data-type-policy=OVERRIDE, i-signal-type=PRIMITIVE, init-value=0, base-type=BT_HBFS_TAG_betaetigt, compu {0=Cx0_nicht_betaetigt (CM_HBFS_TAG_betaetigt_Cx0_nicht_betaetigt), 1=Cx1_betaetigt (CM_HBFS_TAG_betaetigt_Cx1_betaetigt)}, range raw 0..1, transfer-property=TRIGGERED-ON-CHANGE-WITHOUT-REPETITION  # Betaetigung Türaussengriff
          signal HBFS_TIG_betaetigt_XIX_TSG_HBFS_01_XIX_E3V_EVCANFD: start 9, 1 bit, little-endian, data-type-policy=OVERRIDE, i-signal-type=PRIMITIVE, init-value=0, base-type=BT_HBFS_TIG_betaetigt, compu {0=Cx0_nicht_betaetigt (CM_HBFS_TIG_betaetigt_Cx0_nicht_betaetigt), 1=Cx1_betaetigt (CM_HBFS_TIG_betaetigt_Cx1_betaetigt)}, range raw 0..1, transfer-property=TRIGGERED-ON-CHANGE-WITHOUT-REPETITION  # Betaetigung Tuerinnengriff
          signal HBFS_FH_S_HFS_AutoHoch_XIX_TSG_HBFS_01_XIX_E3V_EVCANFD: start 10, 1 bit, little-endian, data-type-policy=OVERRIDE, i-signal-type=PRIMITIVE, init-value=0, base-type=BT_HBFS_FH_S_HFS_AutoHoch, compu {0=Cx0_keine_Bedienung (CM_HBFS_FH_S_HFS_AutoHoch_Cx0_keine_Bedienung), 1=Cx1_Automatiklauf_Angefordert (CM_HBFS_FH_S_HFS_AutoHoch_Cx1_Automatiklauf_Angefordert)}, range raw 0..1, transfer-property=TRIGGERED-ON-CHANGE-WITHOUT-REPETITION  # Automatisches Hochfahren der Seitenscheibe HFS
          signal HBFS_FH_S_HFS_AutoTief_XIX_TSG_HBFS_01_XIX_E3V_EVCANFD: start 11, 1 bit, little-endian, data-type-policy=OVERRIDE, i-signal-type=PRIMITIVE, init-value=0, base-type=BT_HBFS_FH_S_HFS_AutoTief, compu {0=Cx0_keine_Bedienung (CM_HBFS_FH_S_HFS_AutoTief_Cx0_keine_Bedienung), 1=Cx1_Automatiklauf_Angefordert (CM_HBFS_FH_S_HFS_AutoTief_Cx1_Automatiklauf_Angefordert)}, range raw 0..1, transfer-property=TRIGGERED-ON-CHANGE-WITHOUT-REPETITION  # Automatisches Absenken der Seitenscheibe HFS
          signal HBFS_FH_S_HFS_ManHoch_XIX_TSG_HBFS_01_XIX_E3V_EVCANFD: start 12, 1 bit, little-endian, data-type-policy=OVERRIDE, i-signal-type=PRIMITIVE, init-value=0, base-type=BT_HBFS_FH_S_HFS_ManHoch, compu {0=Cx0_keine_Bedienung (CM_HBFS_FH_S_HFS_ManHoch_Cx0_keine_Bedienung), 1=Cx1_Manueller_Lauf_Angefordert (CM_HBFS_FH_S_HFS_ManHoch_Cx1_Manueller_Lauf_Angefordert)}, range raw 0..1, transfer-property=TRIGGERED-ON-CHANGE-WITHOUT-REPETITION  # Manuelles Hochfahren der Seitenscheibe HFS
          signal HBFS_FH_S_HFS_ManTief_XIX_TSG_HBFS_01_XIX_E3V_EVCANFD: start 13, 1 bit, little-endian, data-type-policy=OVERRIDE, i-signal-type=PRIMITIVE, init-value=0, base-type=BT_HBFS_FH_S_HFS_ManTief, compu {0=Cx0_keine_Bedienung (CM_HBFS_FH_S_HFS_ManTief_Cx0_keine_Bedienung), 1=Cx1_Manueller_Lauf_Angefordert (CM_HBFS_FH_S_HFS_ManTief_Cx1_Manueller_Lauf_Angefordert)}, range raw 0..1, transfer-property=TRIGGERED-ON-CHANGE-WITHOUT-REPETITION  # Manuelles Absenken der Seitenscheibe HFS
          signal HBFS_Tuer_Status_XIX_TSG_HBFS_01_XIX_E3V_EVCANFD: start 14, 2 bit, little-endian, data-type-policy=OVERRIDE, i-signal-type=PRIMITIVE, init-value=0, base-type=BT_HBFS_Tuer_Status, invalid-value=Invalid_HBFS_Tuer_Status_XIX_TSG_HBFS_01_XIX_E3V_EVCANFD:3, compu {0=Cx0_Init (CM_HBFS_Tuer_Status_Cx0_Init), 1=Cx1_Tuer_geschlossen (CM_HBFS_Tuer_Status_Cx1_Tuer_geschlossen), 2=Cx2_Tuer_offen (CM_HBFS_Tuer_Status_Cx2_Tuer_offen), 3=Cx3_Fehler (CM_HBFS_Tuer_Status_Cx3_Fehler)}, range raw 0..3, transfer-property=TRIGGERED-ON-CHANGE-WITHOUT-REPETITION  # Türstatus mit Fehler und Initwert
          signal HBFS_SAD_Schalter_XIX_TSG_HBFS_01_XIX_E3V_EVCANFD: start 16, 4 bit, little-endian, data-type-policy=OVERRIDE, i-signal-type=PRIMITIVE, init-value=14, base-type=BT_HBFS_SAD_Schalter, invalid-value=Invalid_HBFS_SAD_Schalter_XIX_TSG_HBFS_01_XIX_E3V_EVCANFD:15, compu {0=Cx0_nicht_betaetigt (CM_HBFS_SAD_Schalter_Cx0_nicht_betaetigt), 5=Cx5_AUF_manuell (CM_HBFS_SAD_Schalter_Cx5_AUF_manuell), 6=Cx6_AUF_automatik (CM_HBFS_SAD_Schalter_Cx6_AUF_automatik), 7=Cx7_ZU_manuell (CM_HBFS_SAD_Schalter_Cx7_ZU_manuell), 8=Cx8_ZU_automatik (CM_HBFS_SAD_Schalter_Cx8_ZU_automatik), 13=Cxd_nicht_verfuegbar (CM_HBFS_SAD_Schalter_Cxd_nicht_verfuegbar), 14=Cxe_Init (CM_HBFS_SAD_Schalter_Cxe_Init), 15=Cxf_Fehler (CM_HBFS_SAD_Schalter_Cxf_Fehler)}, range raw 0..15, transfer-property=TRIGGERED-ON-CHANGE-WITHOUT-REPETITION  # | Ausstelldach MD3 ----------------------------- 0 | nicht_betaetigt 1 | 2 | 3 | 4 | 5 | (m) Auf 6 | (a) Auf 7 | (m) Zu 8 | (a) Zu 13| Schalter nicht verfuegbar 14| Init 15| Fehlerfall
          signal HBFS_FH_S_ManHoch_XIX_TSG_HBFS_01_XIX_E3V_EVCANFD: start 20, 1 bit, little-endian, data-type-policy=OVERRIDE, i-signal-type=PRIMITIVE, init-value=0, base-type=BT_HBFS_FH_S_ManHoch, compu {0=Cx0_nicht_betaetigt (CM_HBFS_FH_S_ManHoch_Cx0_nicht_betaetigt), 1=Cx1_betaetigt (CM_HBFS_FH_S_ManHoch_Cx1_betaetigt)}, range raw 0..1, transfer-property=TRIGGERED-ON-CHANGE-WITHOUT-REPETITION  # Betaetigung FH Schalter man hoch
          signal HBFS_FH_S_AutoHoch_XIX_TSG_HBFS_01_XIX_E3V_EVCANFD: start 21, 1 bit, little-endian, data-type-policy=OVERRIDE, i-signal-type=PRIMITIVE, init-value=0, base-type=BT_HBFS_FH_S_AutoHoch, compu {0=Cx0_nicht_betaetigt (CM_HBFS_FH_S_AutoHoch_Cx0_nicht_betaetigt), 1=Cx1_betaetigt (CM_HBFS_FH_S_AutoHoch_Cx1_betaetigt)}, range raw 0..1, transfer-property=TRIGGERED-ON-CHANGE-WITHOUT-REPETITION  # Betaetigung FH Schalter auto tief
          signal HBFS_FH_S_ManTief_XIX_TSG_HBFS_01_XIX_E3V_EVCANFD: start 22, 1 bit, little-endian, data-type-policy=OVERRIDE, i-signal-type=PRIMITIVE, init-value=0, base-type=BT_HBFS_FH_S_ManTief, compu {0=Cx0_nicht_betaetigt (CM_HBFS_FH_S_ManTief_Cx0_nicht_betaetigt), 1=Cx1_betaetigt (CM_HBFS_FH_S_ManTief_Cx1_betaetigt)}, range raw 0..1, transfer-property=TRIGGERED-ON-CHANGE-WITHOUT-REPETITION  # Betaetigung FH Schalter man tief
          signal HBFS_FH_S_AutoTief_XIX_TSG_HBFS_01_XIX_E3V_EVCANFD: start 23, 1 bit, little-endian, data-type-policy=OVERRIDE, i-signal-type=PRIMITIVE, init-value=0, base-type=BT_HBFS_FH_S_AutoTief, compu {0=Cx0_nicht_betaetigt (CM_HBFS_FH_S_AutoTief_Cx0_nicht_betaetigt), 1=Cx1_betaetigt (CM_HBFS_FH_S_AutoTief_Cx1_betaetigt)}, range raw 0..1, transfer-property=TRIGGERED-ON-CHANGE-WITHOUT-REPETITION  # Betaetigung FH Schalter auto hoch
          signal HBFS_FH_Oeffnung_XIX_TSG_HBFS_01_XIX_E3V_EVCANFD: start 24, 8 bit, little-endian, data-type-policy=OVERRIDE, i-signal-type=PRIMITIVE, init-value=0, base-type=BT_HBFS_FH_Oeffnung, compu {phys=raw*0.5 for raw 0..200; unit Unit_PerCent}, range phys 0..100 Unit_PerCent, raw 0..200, unit=Unit_PerCent, transfer-property=TRIGGERED-ON-CHANGE-WITHOUT-REPETITION, to Klima(timeout 1 s)  # Gibt den Fensteröffnungswert in % an.
          signal HBFS_FH_Bew_hoch_XIX_TSG_HBFS_01_XIX_E3V_EVCANFD: start 32, 1 bit, little-endian, data-type-policy=OVERRIDE, i-signal-type=PRIMITIVE, init-value=0, base-type=BT_HBFS_FH_Bew_hoch, compu {0=Cx0_inaktiv (CM_HBFS_FH_Bew_hoch_Cx0_inaktiv), 1=Cx1_aktiv (CM_HBFS_FH_Bew_hoch_Cx1_aktiv)}, range raw 0..1, transfer-property=TRIGGERED-ON-CHANGE-WITHOUT-REPETITION  # HBFS Fenster bewegt sich in Richtung hoch
          signal HBFS_FH_Bew_tief_XIX_TSG_HBFS_01_XIX_E3V_EVCANFD: start 33, 1 bit, little-endian, data-type-policy=OVERRIDE, i-signal-type=PRIMITIVE, init-value=0, base-type=BT_HBFS_FH_Bew_tief, compu {0=Cx0_inaktiv (CM_HBFS_FH_Bew_tief_Cx0_inaktiv), 1=Cx1_aktiv (CM_HBFS_FH_Bew_tief_Cx1_aktiv)}, range raw 0..1, transfer-property=TRIGGERED-ON-CHANGE-WITHOUT-REPETITION  # HBFS Fenster bewegt sich in Richtung tief
          signal HBFS_FH_Fang_XIX_TSG_HBFS_01_XIX_E3V_EVCANFD: start 34, 1 bit, little-endian, data-type-policy=OVERRIDE, i-signal-type=PRIMITIVE, init-value=0, base-type=BT_HBFS_FH_Fang, compu {0=Cx0_ausserhalb_Fangbereich (CM_HBFS_FH_Fang_Cx0_ausserhalb_Fangbereich), 1=Cx1_innerhalb_Fangbereich (CM_HBFS_FH_Fang_Cx1_innerhalb_Fangbereich)}, range raw 0..1, transfer-property=TRIGGERED-ON-CHANGE-WITHOUT-REPETITION  # Fangbereich ist 4mm von oberer Lippendichtung
          signal HBFS_FH_Block_XIX_TSG_HBFS_01_XIX_E3V_EVCANFD: start 35, 1 bit, little-endian, data-type-policy=OVERRIDE, i-signal-type=PRIMITIVE, init-value=0, base-type=BT_HBFS_FH_Block, compu {0=Cx0_inaktiv (CM_HBFS_FH_Block_Cx0_inaktiv), 1=Cx1_aktiv (CM_HBFS_FH_Block_Cx1_aktiv)}, range raw 0..1, transfer-property=TRIGGERED-ON-CHANGE-WITHOUT-REPETITION  # Fensterscheibe befindet sich im mechanischen Block (oben oder unten)
          signal HBFS_FH_Thermo_XIX_TSG_HBFS_01_XIX_E3V_EVCANFD: start 36, 1 bit, little-endian, data-type-policy=OVERRIDE, i-signal-type=PRIMITIVE, init-value=0, base-type=BT_HBFS_FH_Thermo, compu {0=Cx0_inaktiv (CM_HBFS_FH_Thermo_Cx0_inaktiv), 1=Cx1_aktiv (CM_HBFS_FH_Thermo_Cx1_aktiv)}, range raw 0..1, transfer-property=TRIGGERED-ON-CHANGE-WITHOUT-REPETITION  # gibt an ob Fensterheber im Thermoschutz ist
          signal HBFS_UEKB_aktiviert_XIX_TSG_HBFS_01_XIX_E3V_EVCANFD: start 37, 1 bit, little-endian, data-type-policy=OVERRIDE, i-signal-type=PRIMITIVE, init-value=0, base-type=BT_HBFS_UEKB_aktiviert, compu {0=Cx0_inaktiv (CM_HBFS_UEKB_aktiviert_Cx0_inaktiv), 1=Cx1_aktiv (CM_HBFS_UEKB_aktiviert_Cx1_aktiv)}, range raw 0..1, transfer-property=TRIGGERED-ON-CHANGE-WITHOUT-REPETITION  # Überschutzbegrenzungskraft bei Reversieren
          signal HBFS_Tueroeffnen_Warnung_XIX_TSG_HBFS_01_XIX_E3V_EVCANFD: start 38, 1 bit, little-endian, data-type-policy=OVERRIDE, i-signal-type=PRIMITIVE, init-value=0, base-type=BT_HBFS_Tueroeffnen_Warnung, compu {0=Cx0_Tuerwarnung_nicht_aktiv (CM_HBFS_Tueroeffnen_Warnung_Cx0_Tuerwarnung_nicht_aktiv), 1=Cx1_Tuerwarnung_aktiv (CM_HBFS_Tueroeffnen_Warnung_Cx1_Tuerwarnung_aktiv)}, range raw 0..1, transfer-property=TRIGGERED-ON-CHANGE-WITHOUT-REPETITION  # Bit wird gesetzt, wenn Tür während der Fahrt geoeffnet werden soll.
          signal HBFS_FH_normiert_XIX_TSG_HBFS_01_XIX_E3V_EVCANFD: start 39, 1 bit, little-endian, data-type-policy=OVERRIDE, i-signal-type=PRIMITIVE, init-value=0, base-type=BT_HBFS_FH_normiert, compu {0=Cx0_inaktiv (CM_HBFS_FH_normiert_Cx0_inaktiv), 1=Cx1_aktiv (CM_HBFS_FH_normiert_Cx1_aktiv)}, range raw 0..1, transfer-property=TRIGGERED-ON-CHANGE-WITHOUT-REPETITION  # Die Position der Fensterheberscheibe ist bekannt.
          signal ASW_Warnung_aktiv_HBFS_XIX_TSG_HBFS_01_XIX_E3V_EVCANFD: start 40, 1 bit, little-endian, data-type-policy=OVERRIDE, i-signal-type=PRIMITIVE, init-value=0, base-type=BT_ASW_Warnung_aktiv_HBFS, compu {0=Cx0_nicht_angefordert (CM_ASW_Warnung_aktiv_HBFS_Cx0_nicht_angefordert), 1=Cx1_angefordert (CM_ASW_Warnung_aktiv_HBFS_Cx1_angefordert)}, range raw 0..1, transfer-property=TRIGGERED-ON-CHANGE-WITHOUT-REPETITION  # Abschaltung der Ambientefunktion Tür hinten der Beifahrerseite bei aktiver ASW Warnung an der Fahrertür
          signal HBFS_Zuziehhilfe_aktiv_XIX_TSG_HBFS_01_XIX_E3V_EVCANFD: start 41, 1 bit, little-endian, data-type-policy=OVERRIDE, i-signal-type=PRIMITIVE, init-value=0, base-type=BT_HBFS_Zuziehhilfe_aktiv, compu {0=Cx0_Init (CM_HBFS_Zuziehhilfe_aktiv_Cx0_Init), 1=Cx1_Zuziehhilfe_aktiv (CM_HBFS_Zuziehhilfe_aktiv_Cx1_Zuziehhilfe_aktiv)}, range raw 0..1, transfer-property=TRIGGERED-ON-CHANGE-WITHOUT-REPETITION  # Zuziehhilfe aktiv
          signal HBFS_Seitenrollo_hoch_XIX_TSG_HBFS_01_XIX_E3V_EVCANFD: start 42, 1 bit, little-endian, data-type-policy=OVERRIDE, i-signal-type=PRIMITIVE, init-value=0, base-type=BT_HBFS_Seitenrollo_hoch, compu {0=Cx0_Init (CM_HBFS_Seitenrollo_hoch_Cx0_Init), 1=Cx1_Seitenrollo_in_Bewegung_hoch (CM_HBFS_Seitenrollo_hoch_Cx1_Seitenrollo_in_Bewegung_hoch)}, range raw 0..1, transfer-property=TRIGGERED-ON-CHANGE-WITHOUT-REPETITION  # Seitenrollo in Bewegung Richtung hoch
          signal HBFS_Seitenrollo_tief_XIX_TSG_HBFS_01_XIX_E3V_EVCANFD: start 43, 1 bit, little-endian, data-type-policy=OVERRIDE, i-signal-type=PRIMITIVE, init-value=0, base-type=BT_HBFS_Seitenrollo_tief, compu {0=Cx0_Init (CM_HBFS_Seitenrollo_tief_Cx0_Init), 1=Cx1_Seitenrollo_in_Bewegung_tief (CM_HBFS_Seitenrollo_tief_Cx1_Seitenrollo_in_Bewegung_tief)}, range raw 0..1, transfer-property=TRIGGERED-ON-CHANGE-WITHOUT-REPETITION  # Seitenrollo in Bewegung Richtung tief
          signal HBFS_Status_KiSi_XIX_TSG_HBFS_01_XIX_E3V_EVCANFD: start 44, 1 bit, little-endian, data-type-policy=OVERRIDE, i-signal-type=PRIMITIVE, init-value=0, base-type=BT_HBFS_Status_KiSi, compu {0=Cx0_inaktiv (CM_HBFS_Status_KiSi_Cx0_inaktiv), 1=Cx1_aktiv (CM_HBFS_Status_KiSi_Cx1_aktiv)}, range raw 0..1, transfer-property=TRIGGERED-ON-CHANGE-WITHOUT-REPETITION  # Status Kindersicherung HBFS
          signal SSR_HBFS_Pos_Unten_XIX_TSG_HBFS_01_XIX_E3V_EVCANFD: start 45, 1 bit, little-endian, data-type-policy=OVERRIDE, i-signal-type=PRIMITIVE, init-value=0, base-type=BT_SSR_HBFS_Pos_Unten, compu {0=Cx0_SSR_Oben (CM_SSR_HBFS_Pos_Unten_Cx0_SSR_Oben), 1=Cx1_SSR_Unten (CM_SSR_HBFS_Pos_Unten_Cx1_SSR_Unten)}, range raw 0..1, transfer-property=PENDING  # Signal für die "Global Close". Über dieses Bit wissen die anderen TSGs, ob der SSR oder der FH verfahren werden darf.
          signal HBFS_Oben_Block_erw_XIX_TSG_HBFS_01_XIX_E3V_EVCANFD: start 46, 1 bit, little-endian, data-type-policy=OVERRIDE, i-signal-type=PRIMITIVE, init-value=0, base-type=BT_HBFS_Oben_Block_erw, compu {0=Cx0_Fensterheber_nicht_in_Blockerwar (CM_HBFS_Oben_Block_erw_Cx0_Fensterheber_nicht_in_Blockerwar), 1=Cx1_Fensterheber_in_Blockerwartung_o (CM_HBFS_Oben_Block_erw_Cx1_Fensterheber_in_Blockerwartung_o)}, range raw 0..1, transfer-property=TRIGGERED-ON-CHANGE-WITHOUT-REPETITION  # Fensterheber in Blockerwartung oben
          signal HBFS_Unten_Block_erw_XIX_TSG_HBFS_01_XIX_E3V_EVCANFD: start 47, 1 bit, little-endian, data-type-policy=OVERRIDE, i-signal-type=PRIMITIVE, init-value=0, base-type=BT_HBFS_Unten_Block_erw, compu {0=Cx0_Fensterheber_nicht_in_Blockerwar (CM_HBFS_Unten_Block_erw_Cx0_Fensterheber_nicht_in_Blockerwar), 1=Cx1_Fensterheber_in_Blockerwartung_u (CM_HBFS_Unten_Block_erw_Cx1_Fensterheber_in_Blockerwartung_u)}, range raw 0..1, transfer-property=TRIGGERED-ON-CHANGE-WITHOUT-REPETITION  # Fensterheber in Blockerwartung unten
          signal MTHBFS_M_Taste_XIX_TSG_HBFS_01_XIX_E3V_EVCANFD: start 48, 1 bit, little-endian, data-type-policy=OVERRIDE, i-signal-type=PRIMITIVE, init-value=0, base-type=BT_MTHBFS_M_Taste, compu {0=Cx0_nicht_betaetigt (CM_MTHBFS_M_Taste_Cx0_nicht_betaetigt), 1=Cx1_betaetigt (CM_MTHBFS_M_Taste_Cx1_betaetigt)}, range raw 0..1, transfer-property=TRIGGERED-ON-CHANGE-WITHOUT-REPETITION  # Betätigung M-Taste HBFS
          signal MTHBFS_Pos1_XIX_TSG_HBFS_01_XIX_E3V_EVCANFD: start 49, 1 bit, little-endian, data-type-policy=OVERRIDE, i-signal-type=PRIMITIVE, init-value=0, base-type=BT_MTHBFS_Pos1, compu {0=Cx0_nicht_betaetigt (CM_MTHBFS_Pos1_Cx0_nicht_betaetigt), 1=Cx1_betaetigt (CM_MTHBFS_Pos1_Cx1_betaetigt)}, range raw 0..1, transfer-property=TRIGGERED-ON-CHANGE-WITHOUT-REPETITION  # Betätigung Postionstaste 1 HBFS
          signal MTHBFS_Pos2_XIX_TSG_HBFS_01_XIX_E3V_EVCANFD: start 50, 1 bit, little-endian, data-type-policy=OVERRIDE, i-signal-type=PRIMITIVE, init-value=0, base-type=BT_MTHBFS_Pos2, compu {0=Cx0_nicht_betaetigt (CM_MTHBFS_Pos2_Cx0_nicht_betaetigt), 1=Cx1_betaetigt (CM_MTHBFS_Pos2_Cx1_betaetigt)}, range raw 0..1, transfer-property=TRIGGERED-ON-CHANGE-WITHOUT-REPETITION  # Betätigung Postionstaste 2 HBFS
          signal MTHBFS_Pos3_XIX_TSG_HBFS_01_XIX_E3V_EVCANFD: start 51, 1 bit, little-endian, data-type-policy=OVERRIDE, i-signal-type=PRIMITIVE, init-value=0, base-type=BT_MTHBFS_Pos3, compu {0=Cx0_nicht_betaetigt (CM_MTHBFS_Pos3_Cx0_nicht_betaetigt), 1=Cx1_betaetigt (CM_MTHBFS_Pos3_Cx1_betaetigt)}, range raw 0..1, transfer-property=TRIGGERED-ON-CHANGE-WITHOUT-REPETITION  # Betätigung Postionstaste 3 HBFS
          signal HBFS_MRollo_Schalter_XIX_TSG_HBFS_01_XIX_E3V_EVCANFD: start 52, 3 bit, little-endian, data-type-policy=OVERRIDE, i-signal-type=PRIMITIVE, init-value=6, base-type=BT_HBFS_MRollo_Schalter, invalid-value=Invalid_HBFS_MRollo_Schalter_XIX_TSG_HBFS_01_XIX_E3V_EVCANFD:7, compu {0=Cx0_nicht_betaetigt (CM_HBFS_MRollo_Schalter_Cx0_nicht_betaetigt), 1=Cx1_ZU_manuell (CM_HBFS_MRollo_Schalter_Cx1_ZU_manuell), 2=Cx2_ZU_automatik (CM_HBFS_MRollo_Schalter_Cx2_ZU_automatik), 3=Cx3_AUF_manuell (CM_HBFS_MRollo_Schalter_Cx3_AUF_manuell), 4=Cx4_AUF_automatik (CM_HBFS_MRollo_Schalter_Cx4_AUF_automatik), 5=Cx5_nicht_verfuegbar (CM_HBFS_MRollo_Schalter_Cx5_nicht_verfuegbar), 6=Cx6_Init (CM_HBFS_MRollo_Schalter_Cx6_Init), 7=Cx7_Fehler (CM_HBFS_MRollo_Schalter_Cx7_Fehler)}, range raw 0..7, transfer-property=TRIGGERED-ON-CHANGE-WITHOUT-REPETITION  # | MRollo2 ----------------------------- 0 | nicht_betaetigt 1 | (m) Zu 2 | (a) Zu 3 | (m) Auf 4 | (a) Auf 5 | Schalter nicht verfuegbar 6 | Init 7 | Fehlerfall
          signal HBFS_Lock_Taster_inv_XIX_TSG_HBFS_01_XIX_E3V_EVCANFD: start 55, 1 bit, little-endian, data-type-policy=OVERRIDE, i-signal-type=PRIMITIVE, base-type=BT_HBFS_Lock_Taster_inv, compu {0=Cx0_Lock_Taster_betaetgit (CM_HBFS_Lock_Taster_inv_Cx0_Lock_Taster_betaetgit) (Lock Taster betätgit), 1=Cx1_Lock_Taster_nicht_betaetigt (CM_HBFS_Lock_Taster_inv_Cx1_Lock_Taster_nicht_betaetigt) (Lock Taster nicht betätigt)}, range raw 0..1, transfer-property=TRIGGERED-ON-CHANGE-WITHOUT-REPETITION  # Lock Taster nicht betätigt
          signal HBFS_Status_KiSi_inv_XIX_TSG_HBFS_01_XIX_E3V_EVCANFD: start 56, 1 bit, little-endian, data-type-policy=OVERRIDE, i-signal-type=PRIMITIVE, init-value=1, base-type=BT_HBFS_Status_KiSi_inv, compu {0=Cx0_aktiv (CM_HBFS_Status_KiSi_inv_Cx0_aktiv), 1=Cx1_inaktiv (CM_HBFS_Status_KiSi_inv_Cx1_inaktiv)}, range raw 0..1, transfer-property=TRIGGERED-ON-CHANGE-WITHOUT-REPETITION  # Inverser Status der elektrischen Kindersicherung Beifahrerseite hinten
          signal HBFS_Status_eTAG_XIX_TSG_HBFS_01_XIX_E3V_EVCANFD: start 57, 2 bit, little-endian, data-type-policy=OVERRIDE, i-signal-type=PRIMITIVE, init-value=0, base-type=BT_HBFS_Status_eTAG, invalid-value=Invalid_HBFS_Status_eTAG_XIX_TSG_HBFS_01_XIX_E3V_EVCANFD:3, compu {0=Cx0_Init (CM_HBFS_Status_eTAG_Cx0_Init), 1=Cx1_Griff_ausgefahren (CM_HBFS_Status_eTAG_Cx1_Griff_ausgefahren), 2=Cx2_Griff_eingefahren (CM_HBFS_Status_eTAG_Cx2_Griff_eingefahren), 3=Cx3_Fehler (CM_HBFS_Status_eTAG_Cx3_Fehler)}, range raw 0..3, transfer-property=TRIGGERED-ON-CHANGE-WITHOUT-REPETITION  # Status des elektrischen Tueraussengriffes Tuer Beifahrerseite hinten
          signal HBFS_Tuer_Status_QBit_XIX_TSG_HBFS_01_XIX_E3V_EVCANFD: start 59, 1 bit, little-endian, data-type-policy=OVERRIDE, i-signal-type=PRIMITIVE, init-value=0, base-type=BT_HBFS_Tuer_Status_QBit, compu {0=Cx0_Status_Tuerkontakt_sicher (CM_HBFS_Tuer_Status_QBit_Cx0_Status_Tuerkontakt_sicher), 1=Cx1_Status_Tuerkontakt_unsicher (CM_HBFS_Tuer_Status_QBit_Cx1_Status_Tuerkontakt_unsicher)}, range raw 0..1, transfer-property=TRIGGERED-ON-CHANGE-WITHOUT-REPETITION  # Dieses Bit gibt die Zuverlässigkeit des Türkontakts an. Ein auf dieses Bit folgender Fehlereintrag ist mit dem Sender des Bits abzustimmen (gültig ab PPE).
          signal HBFS_TIG_betaetigt_schliessen_XIX_TSG_HBFS_01_XIX_E3V_EVCANFD: start 60, 1 bit, little-endian, data-type-policy=OVERRIDE, i-signal-type=PRIMITIVE, init-value=0, base-type=BT_HBFS_TIG_betaetigt_schliessen, compu {0=Cx0_nicht_betaetigt (CM_HBFS_TIG_betaetigt_schliessen_Cx0_nicht_betaetigt), 1=Cx1_betaetigt (CM_HBFS_TIG_betaetigt_schliessen_Cx1_betaetigt)}, range raw 0..1, transfer-property=TRIGGERED-ON-CHANGE-WITHOUT-REPETITION  # Türinnenbetätigung, Taster Tür schließen.
          signal HBFS_TIG_betaetigt_oeffnen_XIX_TSG_HBFS_01_XIX_E3V_EVCANFD: start 61, 1 bit, little-endian, data-type-policy=OVERRIDE, i-signal-type=PRIMITIVE, init-value=0, base-type=BT_HBFS_TIG_betaetigt_oeffnen, compu {0=Cx0_nicht_betaetigt (CM_HBFS_TIG_betaetigt_oeffnen_Cx0_nicht_betaetigt), 1=Cx1_betaetigt (CM_HBFS_TIG_betaetigt_oeffnen_Cx1_betaetigt)}, range raw 0..1, transfer-property=TRIGGERED-ON-CHANGE-WITHOUT-REPETITION  # Türinnenbetätigung, Taster Tür öffnen.
          signal HBFS_Vorraste_betaetigt_XIX_TSG_HBFS_01_XIX_E3V_EVCANFD: start 62, 1 bit, little-endian, data-type-policy=OVERRIDE, i-signal-type=PRIMITIVE, init-value=0, base-type=BT_HBFS_Vorraste_betaetigt, compu {0=Cx0_nicht_in_Vorraste (CM_HBFS_Vorraste_betaetigt_Cx0_nicht_in_Vorraste), 1=Cx1_in_Vorraste (CM_HBFS_Vorraste_betaetigt_Cx1_in_Vorraste)}, range raw 0..1, transfer-property=TRIGGERED-ON-CHANGE-WITHOUT-REPETITION  # Status der Vorraste
          signal HBFS_SK_betaetigt_XIX_TSG_HBFS_01_XIX_E3V_EVCANFD: start 63, 1 bit, little-endian, data-type-policy=OVERRIDE, i-signal-type=PRIMITIVE, init-value=0, base-type=BT_HBFS_SK_betaetigt, compu {0=Cx0_ausgehoben (CM_HBFS_SK_betaetigt_Cx0_ausgehoben), 1=Cx1_eingefallen (CM_HBFS_SK_betaetigt_Cx1_eingefallen)}, range raw 0..1, transfer-property=TRIGGERED-ON-CHANGE-WITHOUT-REPETITION  # Status der Sperrklinke
      frame TSG_HFS_01_XIX_E3V_EVCANFD: id 0x3CE, to Klima, frame-length=8, can-addressing-mode=STANDARD, can-frame-rx-behavior=CAN-FD, can-frame-tx-behavior=CAN-FD
        pdu TSG_HFS_01_XIX_E3V_EVCANFD: length=8, minimum-delay=0.02, transmission-mode-true-timing={cyclic-timing={time-offset=0.0, time-period=0.1}, event-controlled-timing={number-of-repetitions=0, repetition-period=0.0}}, unused-bit-pattern=0
          signal HFS_Tuer_geoeffnet_XIX_TSG_HFS_01_XIX_E3V_EVCANFD: start 0, 1 bit, little-endian, data-type-policy=OVERRIDE, i-signal-type=PRIMITIVE, init-value=0, base-type=BT_HFS_Tuer_geoeffnet, compu {0=Cx0_geschlossen (CM_HFS_Tuer_geoeffnet_Cx0_geschlossen), 1=Cx1_offen (CM_HFS_Tuer_geoeffnet_Cx1_offen)}, range raw 0..1, transfer-property=TRIGGERED-ON-CHANGE-WITHOUT-REPETITION, to Klima(timeout 1 s)  # HFS Tuer geoeffnet
          signal HFS_verriegelt_XIX_TSG_HFS_01_XIX_E3V_EVCANFD: start 1, 1 bit, little-endian, data-type-policy=OVERRIDE, i-signal-type=PRIMITIVE, init-value=0, base-type=BT_HFS_verriegelt, compu {0=Cx0_nicht_verriegelt (CM_HFS_verriegelt_Cx0_nicht_verriegelt), 1=Cx1_verriegelt (CM_HFS_verriegelt_Cx1_verriegelt)}, range raw 0..1, transfer-property=TRIGGERED-ON-CHANGE-WITHOUT-REPETITION  # HFS Tuer verriegelt
          signal HFS_gesafet_XIX_TSG_HFS_01_XIX_E3V_EVCANFD: start 2, 1 bit, little-endian, data-type-policy=OVERRIDE, i-signal-type=PRIMITIVE, init-value=0, base-type=BT_HFS_gesafet, compu {0=Cx0_nicht_gesafet (CM_HFS_gesafet_Cx0_nicht_gesafet), 1=Cx1_gesafet (CM_HFS_gesafet_Cx1_gesafet)}, range raw 0..1, transfer-property=TRIGGERED-ON-CHANGE-WITHOUT-REPETITION  # HFS Tuer gesafet. Im Zustand Safe wird auch das Signal HFS_verriegelt = 1 gesendet.
          signal HFS_Heckrollotaster_betaetigt_XIX_TSG_HFS_01_XIX_E3V_EVCANFD: start 3, 1 bit, little-endian, data-type-policy=OVERRIDE, i-signal-type=PRIMITIVE, init-value=0, base-type=BT_HFS_Heckrollotaster_betaetigt, compu {0=Cx0_keine_Verfahranweisung_in_Richtung_Hoch (CM_HFS_Heckrollotaster_betaetigt_Cx0_keine_Verfahranweisung_in_Richtung_Hoch), 1=Cx1_In_Richtung_Hoch_Verfahren (CM_HFS_Heckrollotaster_betaetigt_Cx1_In_Richtung_Hoch_Verfahren)}, range raw 0..1, transfer-property=TRIGGERED-ON-CHANGE-WITHOUT-REPETITION  # Verfahren des Heckrollos in Richtung Hoch Bei Einfachtaster wird Bit als Togglebit verwendet (Heckrollo hoch, tief)
          signal HFS_Tuerschloss_defekt_XIX_TSG_HFS_01_XIX_E3V_EVCANFD: start 4, 1 bit, little-endian, data-type-policy=OVERRIDE, i-signal-type=PRIMITIVE, base-type=BT_HFS_Tuerschloss_defekt, compu {0=Cx0_Tuerschloss_funktionsfaehig (CM_HFS_Tuerschloss_defekt_Cx0_Tuerschloss_funktionsfaehig), 1=Cx1_Tuerschloss_defekt (CM_HFS_Tuerschloss_defekt_Cx1_Tuerschloss_defekt)}, range raw 0..1, transfer-property=PENDING  # Das hintere Tuerschloss auf der Fahrerseite ist nicht mehr funktionsfähig.
          signal HFS_Unlock_Taster_XIX_TSG_HFS_01_XIX_E3V_EVCANFD: start 5, 1 bit, little-endian, data-type-policy=OVERRIDE, i-signal-type=PRIMITIVE, init-value=0, base-type=BT_HFS_Unlock_Taster, compu {0=Cx0_nicht_betaetigt (CM_HFS_Unlock_Taster_Cx0_nicht_betaetigt), 1=Cx1_betaetigt (CM_HFS_Unlock_Taster_Cx1_betaetigt)}, range raw 0..1, transfer-property=TRIGGERED-ON-CHANGE-WITHOUT-REPETITION  # Betaetigung Unlock Taster
          signal HFS_Lock_Taster_XIX_TSG_HFS_01_XIX_E3V_EVCANFD: start 6, 1 bit, little-endian, data-type-policy=OVERRIDE, i-signal-type=PRIMITIVE, init-value=0, base-type=BT_HFS_Lock_Taster, compu {0=Cx0_nicht_betaetigt (CM_HFS_Lock_Taster_Cx0_nicht_betaetigt), 1=Cx1_betaetigt (CM_HFS_Lock_Taster_Cx1_betaetigt)}, range raw 0..1, transfer-property=TRIGGERED-ON-CHANGE-WITHOUT-REPETITION  # Betätigung Lock-Taster
          signal HFS_Sperrklinke_XIX_TSG_HFS_01_XIX_E3V_EVCANFD: start 7, 1 bit, little-endian, data-type-policy=OVERRIDE, i-signal-type=PRIMITIVE, init-value=0, base-type=BT_HFS_Sperrklinke, compu {0=Cx0_Schloss_in_Vorraste_und_Hauptraste (CM_HFS_Sperrklinke_Cx0_Schloss_in_Vorraste_und_Hauptraste), 1=Cx1_Tuer_auf_oder_Tuer_Position_zwischen_Vor_und_Hauptraste (CM_HFS_Sperrklinke_Cx1_Tuer_auf_oder_Tuer_Position_zwischen_Vor_und_Hauptraste)}, range raw 0..1, transfer-property=TRIGGERED-ON-CHANGE-WITHOUT-REPETITION  # Vorraste für Schloß zwischen Vor- und Hauptraste Signal kurz auf 1, danach wieder auf 0 wenn Tür in Hauptraste (Tür ist sicher zu wenn Sperrklinke und Türkontakt auf 0 sind)
          signal HFS_TAG_betaetigt_XIX_TSG_HFS_01_XIX_E3V_EVCANFD: start 8, 1 bit, little-endian, data-type-policy=OVERRIDE, i-signal-type=PRIMITIVE, init-value=0, base-type=BT_HFS_TAG_betaetigt, compu {0=Cx0_nicht_betaetigt (CM_HFS_TAG_betaetigt_Cx0_nicht_betaetigt), 1=Cx1_betaetigt (CM_HFS_TAG_betaetigt_Cx1_betaetigt)}, range raw 0..1, transfer-property=TRIGGERED-ON-CHANGE-WITHOUT-REPETITION  # Betaetigung Türaussengriff
          signal HFS_TIG_betaetigt_XIX_TSG_HFS_01_XIX_E3V_EVCANFD: start 9, 1 bit, little-endian, data-type-policy=OVERRIDE, i-signal-type=PRIMITIVE, init-value=0, base-type=BT_HFS_TIG_betaetigt, compu {0=Cx0_nicht_betaetigt (CM_HFS_TIG_betaetigt_Cx0_nicht_betaetigt), 1=Cx1_betaetigt (CM_HFS_TIG_betaetigt_Cx1_betaetigt)}, range raw 0..1, transfer-property=TRIGGERED-ON-CHANGE-WITHOUT-REPETITION  # Betaetigung Türinnengriff
          signal HFS_FH_S_HBFS_AutoHoch_XIX_TSG_HFS_01_XIX_E3V_EVCANFD: start 10, 1 bit, little-endian, data-type-policy=OVERRIDE, i-signal-type=PRIMITIVE, init-value=0, base-type=BT_HFS_FH_S_HBFS_AutoHoch, compu {0=Cx0_keine_Bedienung (CM_HFS_FH_S_HBFS_AutoHoch_Cx0_keine_Bedienung), 1=Cx1_Automatiklauf_Angefordert (CM_HFS_FH_S_HBFS_AutoHoch_Cx1_Automatiklauf_Angefordert)}, range raw 0..1, transfer-property=TRIGGERED-ON-CHANGE-WITHOUT-REPETITION  # Automatisches Hochfahren der Seitenscheibe HBFS
          signal HFS_FH_S_HBFS_AutoTief_XIX_TSG_HFS_01_XIX_E3V_EVCANFD: start 11, 1 bit, little-endian, data-type-policy=OVERRIDE, i-signal-type=PRIMITIVE, init-value=0, base-type=BT_HFS_FH_S_HBFS_AutoTief, compu {0=Cx0_keine_Bedienung (CM_HFS_FH_S_HBFS_AutoTief_Cx0_keine_Bedienung), 1=Cx1_Automatiklauf_Angefordert (CM_HFS_FH_S_HBFS_AutoTief_Cx1_Automatiklauf_Angefordert)}, range raw 0..1, transfer-property=TRIGGERED-ON-CHANGE-WITHOUT-REPETITION  # Automatisches Absenken der Seitenscheibe HBFS
          signal HFS_FH_S_HBFS_ManHoch_XIX_TSG_HFS_01_XIX_E3V_EVCANFD: start 12, 1 bit, little-endian, data-type-policy=OVERRIDE, i-signal-type=PRIMITIVE, init-value=0, base-type=BT_HFS_FH_S_HBFS_ManHoch, compu {0=Cx0_keine_Bedienung (CM_HFS_FH_S_HBFS_ManHoch_Cx0_keine_Bedienung), 1=Cx1_Manueller_Lauf_Angefordert (CM_HFS_FH_S_HBFS_ManHoch_Cx1_Manueller_Lauf_Angefordert)}, range raw 0..1, transfer-property=TRIGGERED-ON-CHANGE-WITHOUT-REPETITION  # Manuelles Hochfahren der Seitenscheibe HBFS
          signal HFS_FH_S_HBFS_ManTief_XIX_TSG_HFS_01_XIX_E3V_EVCANFD: start 13, 1 bit, little-endian, data-type-policy=OVERRIDE, i-signal-type=PRIMITIVE, init-value=0, base-type=BT_HFS_FH_S_HBFS_ManTief, compu {0=Cx0_keine_Bedienung (CM_HFS_FH_S_HBFS_ManTief_Cx0_keine_Bedienung), 1=Cx1_Manueller_Lauf_Angefordert (CM_HFS_FH_S_HBFS_ManTief_Cx1_Manueller_Lauf_Angefordert)}, range raw 0..1, transfer-property=TRIGGERED-ON-CHANGE-WITHOUT-REPETITION  # Manuelles Absenken der Seitenscheibe HBFS
          signal HFS_Tuer_Status_XIX_TSG_HFS_01_XIX_E3V_EVCANFD: start 14, 2 bit, little-endian, data-type-policy=OVERRIDE, i-signal-type=PRIMITIVE, init-value=0, base-type=BT_HFS_Tuer_Status, invalid-value=Invalid_HFS_Tuer_Status_XIX_TSG_HFS_01_XIX_E3V_EVCANFD:3, compu {0=Cx0_Init (CM_HFS_Tuer_Status_Cx0_Init), 1=Cx1_Tuer_geschlossen (CM_HFS_Tuer_Status_Cx1_Tuer_geschlossen), 2=Cx2_Tuer_offen (CM_HFS_Tuer_Status_Cx2_Tuer_offen), 3=Cx3_Fehler (CM_HFS_Tuer_Status_Cx3_Fehler)}, range raw 0..3, transfer-property=TRIGGERED-ON-CHANGE-WITHOUT-REPETITION  # Türstatus mit Fehler und Initwert
          signal HFS_SAD_Schalter_XIX_TSG_HFS_01_XIX_E3V_EVCANFD: start 16, 4 bit, little-endian, data-type-policy=OVERRIDE, i-signal-type=PRIMITIVE, init-value=14, base-type=BT_HFS_SAD_Schalter, invalid-value=Invalid_HFS_SAD_Schalter_XIX_TSG_HFS_01_XIX_E3V_EVCANFD:15, compu {0=Cx0_nicht_betaetigt (CM_HFS_SAD_Schalter_Cx0_nicht_betaetigt), 5=Cx5_AUF_manuell (CM_HFS_SAD_Schalter_Cx5_AUF_manuell), 6=Cx6_AUF_automatik (CM_HFS_SAD_Schalter_Cx6_AUF_automatik), 7=Cx7_ZU_manuell (CM_HFS_SAD_Schalter_Cx7_ZU_manuell), 8=Cx8_ZU_automatik (CM_HFS_SAD_Schalter_Cx8_ZU_automatik), 13=Cxd_nicht_verfuegbar (CM_HFS_SAD_Schalter_Cxd_nicht_verfuegbar), 14=Cxe_Init (CM_HFS_SAD_Schalter_Cxe_Init), 15=Cxf_Fehler (CM_HFS_SAD_Schalter_Cxf_Fehler)}, range raw 0..15, transfer-property=TRIGGERED-ON-CHANGE-WITHOUT-REPETITION  # | Ausstelldach MD3 ----------------------------- 0 | nicht_betaetigt 1 | 2 | 3 | 4 | 5 | (m) Auf 6 | (a) Auf 7 | (m) Zu 8 | (a) Zu 13| Schalter nicht verfuegbar 14| Init 15| Fehlerfall
          signal HFS_FH_S_ManHoch_XIX_TSG_HFS_01_XIX_E3V_EVCANFD: start 20, 1 bit, little-endian, data-type-policy=OVERRIDE, i-signal-type=PRIMITIVE, init-value=0, base-type=BT_HFS_FH_S_ManHoch, compu {0=Cx0_nicht_betaetigt (CM_HFS_FH_S_ManHoch_Cx0_nicht_betaetigt), 1=Cx1_betaetigt (CM_HFS_FH_S_ManHoch_Cx1_betaetigt)}, range raw 0..1, transfer-property=TRIGGERED-ON-CHANGE-WITHOUT-REPETITION  # Betaetigung FH Schalter man hoch
          signal HFS_FH_S_AutoHoch_XIX_TSG_HFS_01_XIX_E3V_EVCANFD: start 21, 1 bit, little-endian, data-type-policy=OVERRIDE, i-signal-type=PRIMITIVE, init-value=0, base-type=BT_HFS_FH_S_AutoHoch, compu {0=Cx0_nicht_betaetigt (CM_HFS_FH_S_AutoHoch_Cx0_nicht_betaetigt), 1=Cx1_betaetigt (CM_HFS_FH_S_AutoHoch_Cx1_betaetigt)}, range raw 0..1, transfer-property=TRIGGERED-ON-CHANGE-WITHOUT-REPETITION  # Betaetigung FH Schalter auto hoch
          signal HFS_FH_S_ManTief_XIX_TSG_HFS_01_XIX_E3V_EVCANFD: start 22, 1 bit, little-endian, data-type-policy=OVERRIDE, i-signal-type=PRIMITIVE, init-value=0, base-type=BT_HFS_FH_S_ManTief, compu {0=Cx0_nicht_betaetigt (CM_HFS_FH_S_ManTief_Cx0_nicht_betaetigt), 1=Cx1_betaetigt (CM_HFS_FH_S_ManTief_Cx1_betaetigt)}, range raw 0..1, transfer-property=TRIGGERED-ON-CHANGE-WITHOUT-REPETITION  # Betaetigung FH Schalter man tief
          signal HFS_FH_S_AutoTief_XIX_TSG_HFS_01_XIX_E3V_EVCANFD: start 23, 1 bit, little-endian, data-type-policy=OVERRIDE, i-signal-type=PRIMITIVE, init-value=0, base-type=BT_HFS_FH_S_AutoTief, compu {0=Cx0_nicht_betaetigt (CM_HFS_FH_S_AutoTief_Cx0_nicht_betaetigt), 1=Cx1_betaetigt (CM_HFS_FH_S_AutoTief_Cx1_betaetigt)}, range raw 0..1, transfer-property=TRIGGERED-ON-CHANGE-WITHOUT-REPETITION  # Betaetigung FH Schalter auto tief
          signal HFS_FH_Oeffnung_XIX_TSG_HFS_01_XIX_E3V_EVCANFD: start 24, 8 bit, little-endian, data-type-policy=OVERRIDE, i-signal-type=PRIMITIVE, init-value=0, base-type=BT_HFS_FH_Oeffnung, compu {phys=raw*0.5 for raw 0..200; unit Unit_PerCent}, range phys 0..100 Unit_PerCent, raw 0..200, unit=Unit_PerCent, transfer-property=TRIGGERED-ON-CHANGE-WITHOUT-REPETITION, to Klima(timeout 1 s)  # Gibt den Fensteröffnungswert in % an.
          signal HFS_FH_Bew_hoch_XIX_TSG_HFS_01_XIX_E3V_EVCANFD: start 32, 1 bit, little-endian, data-type-policy=OVERRIDE, i-signal-type=PRIMITIVE, init-value=0, base-type=BT_HFS_FH_Bew_hoch, compu {0=Cx0_inaktiv (CM_HFS_FH_Bew_hoch_Cx0_inaktiv), 1=Cx1_aktiv (CM_HFS_FH_Bew_hoch_Cx1_aktiv)}, range raw 0..1, transfer-property=TRIGGERED-ON-CHANGE-WITHOUT-REPETITION  # HFS Fenster bewegt sich in Richtung hoch
          signal HFS_FH_Bew_tief_XIX_TSG_HFS_01_XIX_E3V_EVCANFD: start 33, 1 bit, little-endian, data-type-policy=OVERRIDE, i-signal-type=PRIMITIVE, init-value=0, base-type=BT_HFS_FH_Bew_tief, compu {0=Cx0_inaktiv (CM_HFS_FH_Bew_tief_Cx0_inaktiv), 1=Cx1_aktiv (CM_HFS_FH_Bew_tief_Cx1_aktiv)}, range raw 0..1, transfer-property=TRIGGERED-ON-CHANGE-WITHOUT-REPETITION  # HFS Fenster bewegt sich in Richtung tief
          signal HFS_FH_Fang_XIX_TSG_HFS_01_XIX_E3V_EVCANFD: start 34, 1 bit, little-endian, data-type-policy=OVERRIDE, i-signal-type=PRIMITIVE, init-value=0, base-type=BT_HFS_FH_Fang, compu {0=Cx0_ausserhalb_Fangbereich (CM_HFS_FH_Fang_Cx0_ausserhalb_Fangbereich), 1=Cx1_innerhalb_Fangbereich (CM_HFS_FH_Fang_Cx1_innerhalb_Fangbereich)}, range raw 0..1, transfer-property=TRIGGERED-ON-CHANGE-WITHOUT-REPETITION  # Fangbereich ist 4mm von oberer Lippendichtung
          signal HFS_FH_Block_XIX_TSG_HFS_01_XIX_E3V_EVCANFD: start 35, 1 bit, little-endian, data-type-policy=OVERRIDE, i-signal-type=PRIMITIVE, init-value=0, base-type=BT_HFS_FH_Block, compu {0=Cx0_inaktiv (CM_HFS_FH_Block_Cx0_inaktiv), 1=Cx1_aktiv (CM_HFS_FH_Block_Cx1_aktiv)}, range raw 0..1, transfer-property=TRIGGERED-ON-CHANGE-WITHOUT-REPETITION  # Fensterscheibe befindet sich im mechanischen Block (oben oder unten)
          signal HFS_FH_Thermo_XIX_TSG_HFS_01_XIX_E3V_EVCANFD: start 36, 1 bit, little-endian, data-type-policy=OVERRIDE, i-signal-type=PRIMITIVE, init-value=0, base-type=BT_HFS_FH_Thermo, compu {0=Cx0_inaktiv (CM_HFS_FH_Thermo_Cx0_inaktiv), 1=Cx1_aktiv (CM_HFS_FH_Thermo_Cx1_aktiv)}, range raw 0..1, transfer-property=TRIGGERED-ON-CHANGE-WITHOUT-REPETITION  # gibt an ob Fensterheber im Thermoschutz ist
          signal HFS_UEKB_aktiviert_XIX_TSG_HFS_01_XIX_E3V_EVCANFD: start 37, 1 bit, little-endian, data-type-policy=OVERRIDE, i-signal-type=PRIMITIVE, init-value=0, base-type=BT_HFS_UEKB_aktiviert, compu {0=Cx0_inaktiv (CM_HFS_UEKB_aktiviert_Cx0_inaktiv), 1=Cx1_aktiv (CM_HFS_UEKB_aktiviert_Cx1_aktiv)}, range raw 0..1, transfer-property=TRIGGERED-ON-CHANGE-WITHOUT-REPETITION  # Überschutzbegrenzungskraft bei Reversieren
          signal HFS_Tueroeffnen_Warnung_XIX_TSG_HFS_01_XIX_E3V_EVCANFD: start 38, 1 bit, little-endian, data-type-policy=OVERRIDE, i-signal-type=PRIMITIVE, init-value=0, base-type=BT_HFS_Tueroeffnen_Warnung, compu {0=Cx0_Tuerwarnung_nicht_aktiv (CM_HFS_Tueroeffnen_Warnung_Cx0_Tuerwarnung_nicht_aktiv), 1=Cx1_Tuerwarnung_aktiv (CM_HFS_Tueroeffnen_Warnung_Cx1_Tuerwarnung_aktiv)}, range raw 0..1, transfer-property=TRIGGERED-ON-CHANGE-WITHOUT-REPETITION  # Bit wird gesetzt, wenn Tür während der Fahrt geoeffnet werden soll.
          signal HFS_FH_normiert_XIX_TSG_HFS_01_XIX_E3V_EVCANFD: start 39, 1 bit, little-endian, data-type-policy=OVERRIDE, i-signal-type=PRIMITIVE, init-value=0, base-type=BT_HFS_FH_normiert, compu {0=Cx0_inaktiv (CM_HFS_FH_normiert_Cx0_inaktiv), 1=Cx1_aktiv (CM_HFS_FH_normiert_Cx1_aktiv)}, range raw 0..1, transfer-property=TRIGGERED-ON-CHANGE-WITHOUT-REPETITION  # Die Position der Fensterheberscheibe ist bekannt.
          signal ASW_Warnung_aktiv_HFS_XIX_TSG_HFS_01_XIX_E3V_EVCANFD: start 40, 1 bit, little-endian, data-type-policy=OVERRIDE, i-signal-type=PRIMITIVE, init-value=0, base-type=BT_ASW_Warnung_aktiv_HFS, compu {0=Cx0_nicht_angefordert (CM_ASW_Warnung_aktiv_HFS_Cx0_nicht_angefordert), 1=Cx1_angefordert (CM_ASW_Warnung_aktiv_HFS_Cx1_angefordert)}, range raw 0..1, transfer-property=TRIGGERED-ON-CHANGE-WITHOUT-REPETITION  # Abschaltung der Ambientefunktion Tür hinten der Fahrerseite bei aktiver ASW Warnung an der Fahrertür
          signal HFS_Zuziehhilfe_aktiv_XIX_TSG_HFS_01_XIX_E3V_EVCANFD: start 41, 1 bit, little-endian, data-type-policy=OVERRIDE, i-signal-type=PRIMITIVE, init-value=0, base-type=BT_HFS_Zuziehhilfe_aktiv, compu {0=Cx0_Init (CM_HFS_Zuziehhilfe_aktiv_Cx0_Init), 1=Cx1_Zuziehhilfe_aktiv (CM_HFS_Zuziehhilfe_aktiv_Cx1_Zuziehhilfe_aktiv)}, range raw 0..1, transfer-property=TRIGGERED-ON-CHANGE-WITHOUT-REPETITION  # Zuziehhilfe aktiv
          signal HFS_Seitenrollo_hoch_XIX_TSG_HFS_01_XIX_E3V_EVCANFD: start 42, 1 bit, little-endian, data-type-policy=OVERRIDE, i-signal-type=PRIMITIVE, init-value=0, base-type=BT_HFS_Seitenrollo_hoch, compu {0=Cx0_Init (CM_HFS_Seitenrollo_hoch_Cx0_Init), 1=Cx1_Seitenrollo_in_Bewegung_hoch (CM_HFS_Seitenrollo_hoch_Cx1_Seitenrollo_in_Bewegung_hoch)}, range raw 0..1, transfer-property=TRIGGERED-ON-CHANGE-WITHOUT-REPETITION  # Seitenrollo in Bewegung Richtung hoch
          signal HFS_Seitenrollo_tief_XIX_TSG_HFS_01_XIX_E3V_EVCANFD: start 43, 1 bit, little-endian, data-type-policy=OVERRIDE, i-signal-type=PRIMITIVE, init-value=0, base-type=BT_HFS_Seitenrollo_tief, compu {0=Cx0_Init (CM_HFS_Seitenrollo_tief_Cx0_Init), 1=Cx1_Seitenrollo_in_Bewegung_tief (CM_HFS_Seitenrollo_tief_Cx1_Seitenrollo_in_Bewegung_tief)}, range raw 0..1, transfer-property=TRIGGERED-ON-CHANGE-WITHOUT-REPETITION  # Seitenrollo in Bewegung Richtung tief
          signal HFS_Status_KiSi_XIX_TSG_HFS_01_XIX_E3V_EVCANFD: start 44, 1 bit, little-endian, data-type-policy=OVERRIDE, i-signal-type=PRIMITIVE, init-value=0, base-type=BT_HFS_Status_KiSi, compu {0=Cx0_inaktiv (CM_HFS_Status_KiSi_Cx0_inaktiv), 1=Cx1_aktiv (CM_HFS_Status_KiSi_Cx1_aktiv)}, range raw 0..1, transfer-property=TRIGGERED-ON-CHANGE-WITHOUT-REPETITION  # Status Kindersicherung hinten Fahrerseite
          signal SSR_HFS_Pos_Unten_XIX_TSG_HFS_01_XIX_E3V_EVCANFD: start 45, 1 bit, little-endian, data-type-policy=OVERRIDE, i-signal-type=PRIMITIVE, init-value=0, base-type=BT_SSR_HFS_Pos_Unten, compu {0=Cx0_SSR_Oben (CM_SSR_HFS_Pos_Unten_Cx0_SSR_Oben), 1=Cx1_SSR_Unten (CM_SSR_HFS_Pos_Unten_Cx1_SSR_Unten)}, range raw 0..1, transfer-property=PENDING  # Signal für die "Global Close". Über dieses Bit wissen die anderen TSGs, ob der SSR oder der FH verfahren werden darf.
          signal HFS_Oben_Block_erw_XIX_TSG_HFS_01_XIX_E3V_EVCANFD: start 46, 1 bit, little-endian, data-type-policy=OVERRIDE, i-signal-type=PRIMITIVE, init-value=0, base-type=BT_HFS_Oben_Block_erw, compu {0=Cx0_Fensterheber_nicht_in_Blockerwar (CM_HFS_Oben_Block_erw_Cx0_Fensterheber_nicht_in_Blockerwar), 1=Cx1_Fensterheber_in_Blockerwartung_o (CM_HFS_Oben_Block_erw_Cx1_Fensterheber_in_Blockerwartung_o)}, range raw 0..1, transfer-property=TRIGGERED-ON-CHANGE-WITHOUT-REPETITION  # Fensterheber in Blockerwartung oben
          signal HFS_Unten_Block_erw_XIX_TSG_HFS_01_XIX_E3V_EVCANFD: start 47, 1 bit, little-endian, data-type-policy=OVERRIDE, i-signal-type=PRIMITIVE, init-value=0, base-type=BT_HFS_Unten_Block_erw, compu {0=Cx0_Fensterheber_nicht_in_Blockerwar (CM_HFS_Unten_Block_erw_Cx0_Fensterheber_nicht_in_Blockerwar), 1=Cx1_Fensterheber_in_Blockerwartung_u (CM_HFS_Unten_Block_erw_Cx1_Fensterheber_in_Blockerwartung_u)}, range raw 0..1, transfer-property=TRIGGERED-ON-CHANGE-WITHOUT-REPETITION  # Fensterheber in Blockerwartung unten
          signal MTHFS_M_Taste_XIX_TSG_HFS_01_XIX_E3V_EVCANFD: start 48, 1 bit, little-endian, data-type-policy=OVERRIDE, i-signal-type=PRIMITIVE, init-value=0, base-type=BT_MTHFS_M_Taste, compu {0=Cx0_nicht_betaetigt (CM_MTHFS_M_Taste_Cx0_nicht_betaetigt), 1=Cx1_betaetigt (CM_MTHFS_M_Taste_Cx1_betaetigt)}, range raw 0..1, transfer-property=TRIGGERED-ON-CHANGE-WITHOUT-REPETITION  # Betätigung M-Taste HFS
          signal MTHFS_Pos1_XIX_TSG_HFS_01_XIX_E3V_EVCANFD: start 49, 1 bit, little-endian, data-type-policy=OVERRIDE, i-signal-type=PRIMITIVE, init-value=0, base-type=BT_MTHFS_Pos1, compu {0=Cx0_nicht_betaetigt (CM_MTHFS_Pos1_Cx0_nicht_betaetigt), 1=Cx1_betaetigt (CM_MTHFS_Pos1_Cx1_betaetigt)}, range raw 0..1, transfer-property=TRIGGERED-ON-CHANGE-WITHOUT-REPETITION  # Betätigung Postionstaste 1 HFS
          signal MTHFS_Pos2_XIX_TSG_HFS_01_XIX_E3V_EVCANFD: start 50, 1 bit, little-endian, data-type-policy=OVERRIDE, i-signal-type=PRIMITIVE, init-value=0, base-type=BT_MTHFS_Pos2, compu {0=Cx0_nicht_betaetigt (CM_MTHFS_Pos2_Cx0_nicht_betaetigt), 1=Cx1_betaetigt (CM_MTHFS_Pos2_Cx1_betaetigt)}, range raw 0..1, transfer-property=TRIGGERED-ON-CHANGE-WITHOUT-REPETITION  # Betätigung Postionstaste 2 HFS
          signal MTHFS_Pos3_XIX_TSG_HFS_01_XIX_E3V_EVCANFD: start 51, 1 bit, little-endian, data-type-policy=OVERRIDE, i-signal-type=PRIMITIVE, init-value=0, base-type=BT_MTHFS_Pos3, compu {0=Cx0_nicht_betaetigt (CM_MTHFS_Pos3_Cx0_nicht_betaetigt), 1=Cx1_betaetigt (CM_MTHFS_Pos3_Cx1_betaetigt)}, range raw 0..1, transfer-property=TRIGGERED-ON-CHANGE-WITHOUT-REPETITION  # Betätigung Postionstaste 3 HFS
          signal HFS_MRollo_Schalter_XIX_TSG_HFS_01_XIX_E3V_EVCANFD: start 52, 3 bit, little-endian, data-type-policy=OVERRIDE, i-signal-type=PRIMITIVE, init-value=6, base-type=BT_HFS_MRollo_Schalter, invalid-value=Invalid_HFS_MRollo_Schalter_XIX_TSG_HFS_01_XIX_E3V_EVCANFD:7, compu {0=Cx0_nicht_betaetigt (CM_HFS_MRollo_Schalter_Cx0_nicht_betaetigt), 1=Cx1_ZU_manuell (CM_HFS_MRollo_Schalter_Cx1_ZU_manuell), 2=Cx2_ZU_automatik (CM_HFS_MRollo_Schalter_Cx2_ZU_automatik), 3=Cx3_AUF_manuell (CM_HFS_MRollo_Schalter_Cx3_AUF_manuell), 4=Cx4_AUF_automatik (CM_HFS_MRollo_Schalter_Cx4_AUF_automatik), 5=Cx5_nicht_verfuegbar (CM_HFS_MRollo_Schalter_Cx5_nicht_verfuegbar), 6=Cx6_Init (CM_HFS_MRollo_Schalter_Cx6_Init), 7=Cx7_Fehler (CM_HFS_MRollo_Schalter_Cx7_Fehler)}, range raw 0..7, transfer-property=TRIGGERED-ON-CHANGE-WITHOUT-REPETITION  # | MRollo2 ----------------------------- 0 | nicht_betaetigt 1 | (m) Zu 2 | (a) Zu 3 | (m) Auf 4 | (a) Auf 5 | Schalter nicht verfuegbar 6 | Init 7 | Fehlerfall
          signal HFS_Lock_Taster_inv_XIX_TSG_HFS_01_XIX_E3V_EVCANFD: start 55, 1 bit, little-endian, data-type-policy=OVERRIDE, i-signal-type=PRIMITIVE, init-value=0, base-type=BT_HFS_Lock_Taster_inv, compu {0=Cx0_Lock_Taster_betaetgit (CM_HFS_Lock_Taster_inv_Cx0_Lock_Taster_betaetgit) (Lock Taster betätgit), 1=Cx1_Lock_Taster_nicht_betaetigt (CM_HFS_Lock_Taster_inv_Cx1_Lock_Taster_nicht_betaetigt) (Lock Taster nicht betätigt)}, range raw 0..1, transfer-property=TRIGGERED-ON-CHANGE-WITHOUT-REPETITION  # Lock Taster nicht betätigt
          signal HFS_Status_eTAG_XIX_TSG_HFS_01_XIX_E3V_EVCANFD: start 56, 2 bit, little-endian, data-type-policy=OVERRIDE, i-signal-type=PRIMITIVE, init-value=0, base-type=BT_HFS_Status_eTAG, invalid-value=Invalid_HFS_Status_eTAG_XIX_TSG_HFS_01_XIX_E3V_EVCANFD:3, compu {0=Cx0_Init (CM_HFS_Status_eTAG_Cx0_Init), 1=Cx1_Griff_ausgefahren (CM_HFS_Status_eTAG_Cx1_Griff_ausgefahren), 2=Cx2_Griff_eingefahren (CM_HFS_Status_eTAG_Cx2_Griff_eingefahren), 3=Cx3_Fehler (CM_HFS_Status_eTAG_Cx3_Fehler)}, range raw 0..3, transfer-property=TRIGGERED-ON-CHANGE-WITHOUT-REPETITION  # Status des elektrischen Tueraussengriffes Tuer Fahrerseite hinten
          signal HFS_Tuer_Status_QBit_XIX_TSG_HFS_01_XIX_E3V_EVCANFD: start 58, 1 bit, little-endian, data-type-policy=OVERRIDE, i-signal-type=PRIMITIVE, base-type=BT_HFS_Tuer_Status_QBit, compu {0=Cx0_Status_Tuerkontakt_sicher (CM_HFS_Tuer_Status_QBit_Cx0_Status_Tuerkontakt_sicher), 1=Cx1_Status_Tuerkontakt_unsicher (CM_HFS_Tuer_Status_QBit_Cx1_Status_Tuerkontakt_unsicher)}, range raw 0..1, transfer-property=PENDING  # Dieses Bit gibt die Zuverlässigkeit des Türkontakts an. Ein auf dieses Bit folgender Fehlereintrag ist mit dem Sender des Bits abzustimmen (gültig ab PPE).
          signal HFS_TCR_Mode_aktiv_XIX_TSG_HFS_01_XIX_E3V_EVCANFD: start 59, 1 bit, little-endian, data-type-policy=OVERRIDE, i-signal-type=PRIMITIVE, init-value=0, base-type=BT_HFS_TCR_Mode_aktiv, compu {0=Cx0_TCR_Mode_deaktiv (CM_HFS_TCR_Mode_aktiv_Cx0_TCR_Mode_deaktiv), 1=Cx1_TCR_Mode_aktiv (CM_HFS_TCR_Mode_aktiv_Cx1_TCR_Mode_aktiv)}, range raw 0..1, transfer-property=TRIGGERED-ON-CHANGE-WITHOUT-REPETITION  # Signal zeigt eine aktive mechanische Redundanz am Türschloss an.
          signal HFS_TIG_betaetigt_schliessen_XIX_TSG_HFS_01_XIX_E3V_EVCANFD: start 60, 1 bit, little-endian, data-type-policy=OVERRIDE, i-signal-type=PRIMITIVE, init-value=0, base-type=BT_HFS_TIG_betaetigt_schliessen, compu {0=Cx0_nicht_betaetigt (CM_HFS_TIG_betaetigt_schliessen_Cx0_nicht_betaetigt), 1=Cx1_betaetigt (CM_HFS_TIG_betaetigt_schliessen_Cx1_betaetigt)}, range raw 0..1, transfer-property=TRIGGERED-ON-CHANGE-WITHOUT-REPETITION  # Türinnenbetätigung, Taster Tür schließen.
          signal HFS_TIG_betaetigt_oeffnen_XIX_TSG_HFS_01_XIX_E3V_EVCANFD: start 61, 1 bit, little-endian, data-type-policy=OVERRIDE, i-signal-type=PRIMITIVE, init-value=0, base-type=BT_HFS_TIG_betaetigt_oeffnen, compu {0=Cx0_nicht_betaetigt (CM_HFS_TIG_betaetigt_oeffnen_Cx0_nicht_betaetigt), 1=Cx1_betaetigt (CM_HFS_TIG_betaetigt_oeffnen_Cx1_betaetigt)}, range raw 0..1, transfer-property=TRIGGERED-ON-CHANGE-WITHOUT-REPETITION  # Türinnenbetätigung, Taster Tür öffnen.
          signal HFS_Vorraste_betaetigt_XIX_TSG_HFS_01_XIX_E3V_EVCANFD: start 62, 1 bit, little-endian, data-type-policy=OVERRIDE, i-signal-type=PRIMITIVE, init-value=0, base-type=BT_HFS_Vorraste_betaetigt, compu {0=Cx0_nicht_in_Vorraste (CM_HFS_Vorraste_betaetigt_Cx0_nicht_in_Vorraste), 1=Cx1_in_Vorraste (CM_HFS_Vorraste_betaetigt_Cx1_in_Vorraste)}, range raw 0..1, transfer-property=TRIGGERED-ON-CHANGE-WITHOUT-REPETITION  # Status der Vorraste
          signal HFS_SK_betaetigt_XIX_TSG_HFS_01_XIX_E3V_EVCANFD: start 63, 1 bit, little-endian, data-type-policy=OVERRIDE, i-signal-type=PRIMITIVE, init-value=0, base-type=BT_HFS_SK_betaetigt, compu {0=Cx0_ausgehoben (CM_HFS_SK_betaetigt_Cx0_ausgehoben), 1=Cx1_eingefallen (CM_HFS_SK_betaetigt_Cx1_eingefallen)}, range raw 0..1, transfer-property=TRIGGERED-ON-CHANGE-WITHOUT-REPETITION  # Status der Sperrklinke
